VERSION ""

NS_ :

BS_:

BU_: APIM_CISM FCIMB RACM_RCIM DSP WCM DACMC HUD_ADV TRM_ITRM ACM GWM _delete APIM IPC GENERIC TSTR

BO_ 611 Driveline_Data_1_HS3: 8 GWM
 SG_ AwdTerrMdeChng_D_Rdy : 58|3@0+ (1,0) [0|7] "SED"  IPC
 SG_ AwdTerrMde_D_Actl : 50|3@0+ (1,0) [0|7] "SED"  IPC
 SG_ AwdSys_D_Stat : 27|2@0+ (1,0) [0|3] "SED"  IPC
 SG_ AwdStat_D_RqDsply : 63|5@0+ (1,0) [0|31] "SED"  IPC
 SG_ AwdLck_D_Stat : 31|4@0+ (1,0) [0|15] "SED"  IPC
 SG_ AwdSrvcRqd_B_Rq : 0|1@0+ (1,0) [0|1] "SED"  IPC
 SG_ AwdLck_Tq_Rq : 15|12@0+ (1,0) [0|4093] "Nm"  IPC
 SG_ TrnAout_Tq_RqMx : 47|13@0+ (1,-1250) [-1250|6941] "Nm"  IPC
 SG_ AwdOffRoadMode_D_Stats : 25|2@0+ (1,0) [0|3] "SED"  APIM_CISM,APIM,IPC
 SG_ AwdLoLamp_D_RqDsply : 35|2@0+ (1,0) [0|3] "SED"  APIM,APIM_CISM,IPC
 SG_ AwdHiLamp_D_RqDsply : 19|2@0+ (1,0) [0|3] "SED"  APIM,APIM_CISM,IPC
 SG_ AwdAutoLamp_D_RqDsply : 17|2@0+ (1,0) [0|3] "SED"  APIM,APIM_CISM,IPC
 SG_ Awd2wdLamp_D_RqDsply : 2|2@0+ (1,0) [0|3] "SED"  APIM,APIM_CISM,IPC
 SG_ AwdRnge_D_Actl : 7|3@0+ (1,0) [0|7] "SED"  APIM_CISM,ACM,APIM,IPC
 SG_ NtrlTowAvail_B_Stat : 4|1@0+ (1,0) [0|1] "SED"  IPC
 SG_ AwdDrvMde_D_Stat : 38|3@0+ (1,0) [0|7] "SED"  IPC
 SG_ SelDrvMdeAwd_D_Stat : 33|2@0+ (1,0) [0|3] "SED"  GENERIC

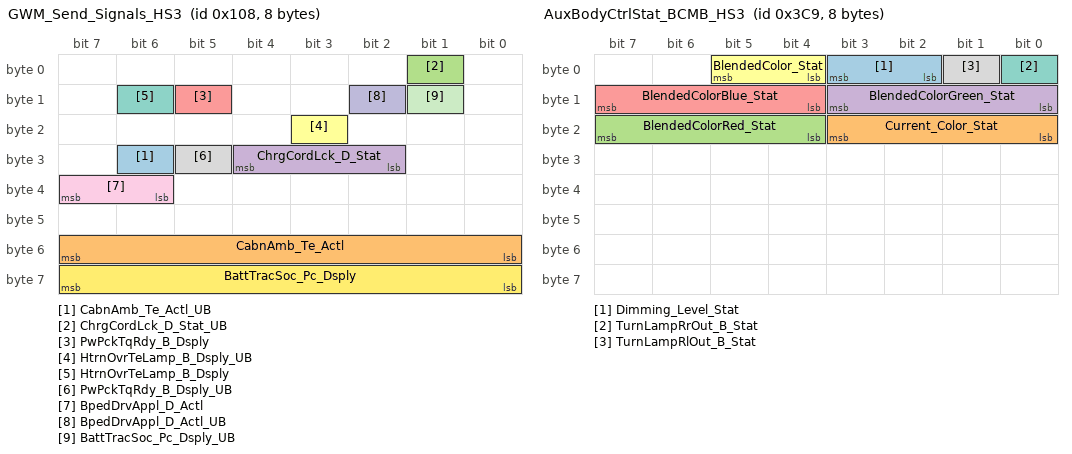
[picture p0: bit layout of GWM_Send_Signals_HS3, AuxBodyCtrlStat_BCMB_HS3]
BO_ 264 GWM_Send_Signals_HS3: 8 GWM
 SG_ CabnAmb_Te_Actl_UB : 30|1@0+ (1,0) [0|1] "SED"  APIM,APIM_CISM,WCM,ACM
 SG_ CabnAmb_Te_Actl : 55|8@0+ (0.5,-57) [-57|70] "degreesC"  APIM,APIM_CISM,WCM,ACM
 SG_ ChrgCordLck_D_Stat_UB : 1|1@0+ (1,0) [0|1] "SED"  APIM_CISM,APIM
 SG_ ChrgCordLck_D_Stat : 28|3@0+ (1,0) [0|7] "SED"  APIM_CISM,APIM
 SG_ PwPckTqRdy_B_Dsply : 13|1@0+ (1,0) [0|1] "SED"  APIM_CISM,APIM,IPC
 SG_ HtrnOvrTeLamp_B_Dsply_UB : 19|1@0+ (1,0) [0|1] "SED"  IPC
 SG_ HtrnOvrTeLamp_B_Dsply : 14|1@0+ (1,0) [0|1] "SED"  IPC
 SG_ PwPckTqRdy_B_Dsply_UB : 29|1@0+ (1,0) [0|1] "SED"  APIM_CISM,APIM,IPC
 SG_ BpedDrvAppl_D_Actl : 39|2@0+ (1,0) [0|3] "SED"  APIM_CISM,APIM,TRM_ITRM,IPC
 SG_ BpedDrvAppl_D_Actl_UB : 10|1@0+ (1,0) [0|1] "SED"  APIM_CISM,APIM,TRM_ITRM,IPC
 SG_ BattTracSoc_Pc_Dsply_UB : 9|1@0+ (1,0) [0|1] "SED"  APIM_CISM,HUD_ADV,APIM,IPC
 SG_ BattTracSoc_Pc_Dsply : 63|8@0+ (0.5,0) [0|126.5] "Percent"  APIM_CISM,HUD_ADV,APIM,IPC

BO_ 1114 TrailerAid_Data: 8 IPC
 SG_ TrailCtlSwtch_B_Stat2 : 16|1@0+ (1,0) [0|1] "SED"  GWM
 SG_ TrlBrkInitOut_D_Rq : 60|2@0+ (1,0) [0|3] "SED"  TRM_ITRM,GWM

BO_ 968 Cluster_Lighting_Rq: 8 IPC
 SG_ RvltnMatchAllw_D_Rq : 58|2@0+ (1,0) [0|3] "SED"  GWM
 SG_ BrkDrvMde_D_Rq : 18|3@0+ (1,0) [0|7] "SED"  GWM
 SG_ LnchCtl_N_Rq : 55|8@0+ (50,0) [0|12750] "rpm"  GWM
 SG_ LnchCtl_D_Rq : 63|2@0+ (1,0) [0|3] "SED"  GWM
 SG_ CurrentColor_CmdGage : 43|4@0+ (1,0) [0|15] "SED"  GWM
 SG_ BlendedColor_CmdGage : 25|2@0+ (1,0) [0|3] "SED"  GWM
 SG_ BlendColorRed_CmdGage : 47|4@0+ (1,0) [0|15] "SED"  GWM
 SG_ BlendColorGrn_CmdGage : 35|4@0+ (1,0) [0|15] "SED"  GWM
 SG_ BlendColorBlue_CmdGage : 39|4@0+ (1,0) [0|15] "SED"  GWM
 SG_ Dimming_Level_Cmd : 1|2@0+ (1,0) [0|3] "SED"  GWM
 SG_ Current_Color_Cmd : 23|4@0+ (1,0) [0|15] "SED"  GWM
 SG_ BlendedColorRed_Cmd : 11|4@0+ (1,0) [0|15] "SED"  GWM
 SG_ BlendedColorGreen_Cmd : 15|4@0+ (1,0) [0|15] "SED"  GWM
 SG_ BlendedColorBlue_Cmd : 5|4@0+ (1,0) [0|15] "SED"  GWM
 SG_ BlendedColor_Cmd : 7|2@0+ (1,0) [0|3] "SED"  GWM
 SG_ SuspDrvMde_D_Rq : 61|3@0+ (1,0) [0|7] "SED"  GWM
 SG_ SlMde_D_Rq : 27|2@0+ (1,0) [0|3] "SED"  GWM
 SG_ IsaOffst_D_Rq : 31|4@0+ (1,0) [0|15] "SED"  GWM

BO_ 969 AuxBodyCtrlStat_BCMB_HS3: 8 GWM
 SG_ Dimming_Level_Stat : 3|2@0+ (1,0) [0|3] "SED"  IPC
 SG_ Current_Color_Stat : 19|4@0+ (1,0) [0|15] "SED"  IPC
 SG_ BlendedColorRed_Stat : 23|4@0+ (1,0) [0|15] "SED"  IPC
 SG_ BlendedColorGreen_Stat : 11|4@0+ (1,0) [0|15] "SED"  IPC
 SG_ BlendedColorBlue_Stat : 15|4@0+ (1,0) [0|15] "SED"  IPC
 SG_ BlendedColor_Stat : 5|2@0+ (1,0) [0|3] "SED"  IPC
 SG_ TurnLampRrOut_B_Stat : 0|1@0+ (1,0) [0|1] "SED"  IPC
 SG_ TurnLampRlOut_B_Stat : 1|1@0+ (1,0) [0|1] "SED"  IPC

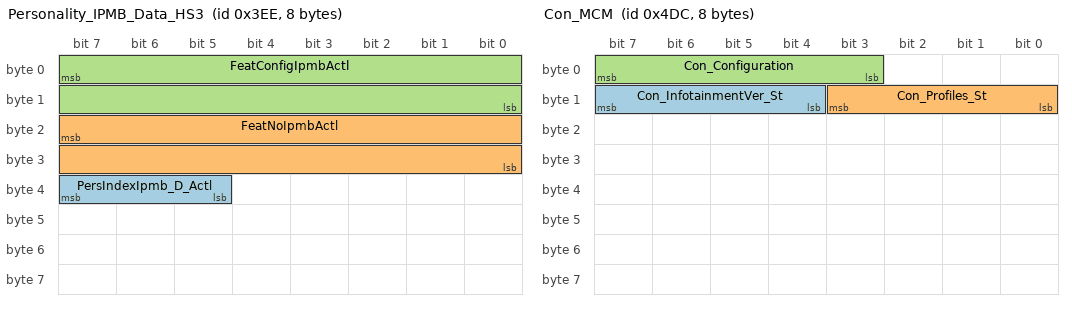
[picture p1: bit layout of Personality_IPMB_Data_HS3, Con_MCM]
BO_ 1006 Personality_IPMB_Data_HS3: 8 GWM
 SG_ PersIndexIpmb_D_Actl : 39|3@0+ (1,0) [0|7] "SED"  APIM_CISM,APIM,ACM
 SG_ FeatNoIpmbActl : 23|16@0+ (1,0) [0|65535] "Number"  APIM_CISM,APIM,ACM
 SG_ FeatConfigIpmbActl : 7|16@0+ (1,0) [0|65535] "Undefined"  APIM_CISM,APIM,ACM

BO_ 130 Steering_Wheel_Data2_HS3: 8 GWM
 SG_ EngExhMdeQuiet_B_RqDrv2 : 39|1@0+ (1,0) [0|1] "SED"  IPC
 SG_ SteWhlSwtchHome_B_Stat : 19|1@0+ (1,0) [0|1] "SED"  IPC
 SG_ SteWhlSwtchInfo_B_Stat : 18|1@0+ (1,0) [0|1] "SED"  IPC
 SG_ SelDrvMdeSwtch_D_Stat4 : 21|2@0+ (1,0) [0|3] "SED"  APIM,APIM_CISM
 SG_ SelDrvMdeSwtch3_D_Stat4 : 25|2@0+ (1,0) [0|3] "SED"  GENERIC
 SG_ SelDrvMdeSwtch2_D_Stat4 : 27|2@0+ (1,0) [0|3] "SED"  GENERIC
 SG_ SelDrvMdeSwtch1_D_Stat4 : 29|2@0+ (1,0) [0|3] "SED"  GENERIC
 SG_ PoliceAux4Swtch_B_Stat : 30|1@0+ (1,0) [0|1] "SED"  TRM_ITRM
 SG_ PoliceAux3Swtch_B_Stat : 31|1@0+ (1,0) [0|1] "SED"  TRM_ITRM
 SG_ PoliceAux2Swtch_B_Stat : 16|1@0+ (1,0) [0|1] "SED"  TRM_ITRM
 SG_ PoliceAux1Swtch_B_Stat : 17|1@0+ (1,0) [0|1] "SED"  TRM_ITRM
 SG_ SteWhlSwtchView_B_Stat : 23|1@0+ (1,0) [0|1] "SED"  IPC
 SG_ SteWhlSwtchSet_B_Stat : 8|1@0+ (1,0) [0|1] "SED"  IPC
 SG_ SteWhlSwtchPhon_B_Stat : 9|1@0+ (1,0) [0|1] "SED"  HUD_ADV,IPC
 SG_ SteWhlSwtchNav_B_Stat : 10|1@0+ (1,0) [0|1] "SED"  IPC
 SG_ SteWhlSwtchMed_B_Stat : 11|1@0+ (1,0) [0|1] "SED"  HUD_ADV,IPC
 SG_ SteWhlSwtchIod_B_Stat : 12|1@0+ (1,0) [0|1] "SED"  IPC
 SG_ SteWhlSwtchHud_B_Stat : 13|1@0+ (1,0) [0|1] "SED"  HUD_ADV,IPC
 SG_ SteWhlSwtchBack_B_Stat : 14|1@0+ (1,0) [0|1] "SED"  HUD_ADV,IPC
 SG_ SteWhlSwtchMenu_B_Stat : 22|1@0+ (1,0) [0|1] "SED"  IPC
 SG_ SteEffortInc_B_RqDrv : 5|1@0+ (1,0) [0|1] "SED"  IPC
 SG_ SelDrvMdeInc_B_RqDrv : 6|1@0+ (1,0) [0|1] "SED"  IPC
 SG_ SelDrvMdeDec_B_RqDrv : 7|1@0+ (1,0) [0|1] "SED"  IPC
 SG_ SuspDampInc_B_RqDrv : 15|1@0+ (1,0) [0|1] "SED"  IPC
 SG_ SteWhlSwtchUp_B_Stat : 3|1@0+ (1,0) [0|1] "SED"  HUD_ADV,IPC
 SG_ SteWhlSwtchRght_B_Stat : 2|1@0+ (1,0) [0|1] "SED"  HUD_ADV,IPC
 SG_ SteWhlSwtchOk_B_Stat : 4|1@0+ (1,0) [0|1] "SED"  HUD_ADV,IPC
 SG_ SteWhlSwtchLeft_B_Stat : 1|1@0+ (1,0) [0|1] "SED"  HUD_ADV,IPC
 SG_ SteWhlSwtchDown_B_Stat : 0|1@0+ (1,0) [0|1] "SED"  HUD_ADV,IPC

BO_ 1244 Con_MCM: 8 ACM
 SG_ Con_InfotainmentVer_St : 15|4@0+ (1,0) [0|0] ""  IPC
 SG_ Con_Profiles_St : 11|4@0+ (1,0) [0|0] ""  IPC
 SG_ Con_Configuration : 7|5@0+ (1,0) [0|0] ""  IPC

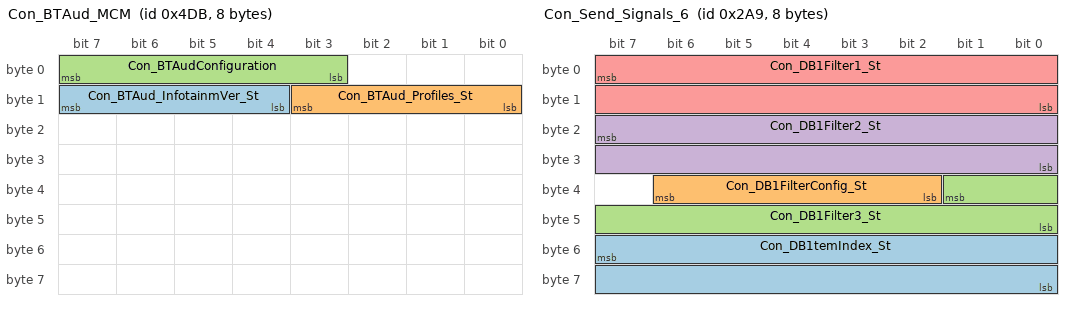
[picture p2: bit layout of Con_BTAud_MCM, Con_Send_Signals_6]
BO_ 1243 Con_BTAud_MCM: 8 ACM
 SG_ Con_BTAud_InfotainmVer_St : 15|4@0+ (1,0) [0|0] ""  IPC
 SG_ Con_BTAud_Profiles_St : 11|4@0+ (1,0) [0|0] ""  IPC
 SG_ Con_BTAudConfiguration : 7|5@0+ (1,0) [0|0] ""  IPC

BO_ 681 Con_Send_Signals_6: 8 ACM
 SG_ Con_DB1temIndex_St : 55|16@0+ (1,0) [0|0] ""  IPC
 SG_ Con_DB1FilterConfig_St : 38|5@0+ (1,0) [0|31] "SED"  IPC
 SG_ Con_DB1Filter3_St : 33|10@0+ (1,0) [0|1023] "unitless"  IPC
 SG_ Con_DB1Filter2_St : 23|16@0+ (1,0) [0|65535] "unitless"  IPC
 SG_ Con_DB1Filter1_St : 7|16@0+ (1,0) [0|65535] "unitless"  IPC

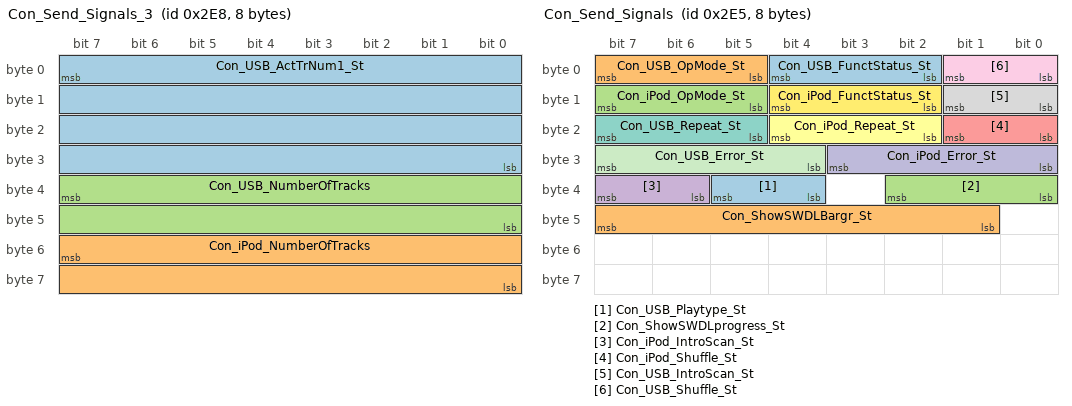
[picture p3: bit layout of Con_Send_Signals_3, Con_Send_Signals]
BO_ 744 Con_Send_Signals_3: 8 ACM
 SG_ Con_USB_ActTrNum1_St : 7|32@0+ (1,0) [0|4294967295] ""  IPC
 SG_ Con_iPod_NumberOfTracks : 55|16@0+ (1,0) [0|65535] ""  IPC
 SG_ Con_USB_NumberOfTracks : 39|16@0+ (1,0) [0|65535] ""  IPC

BO_ 741 Con_Send_Signals: 8 ACM
 SG_ Con_USB_Playtype_St : 37|2@0+ (1,0) [0|3] "SED"  APIM
 SG_ Con_ShowSWDLBargr_St : 47|7@0+ (1,0) [0|127] "unitless"  APIM
 SG_ Con_ShowSWDLprogress_St : 34|3@0+ (1,0) [0|7] "SED"  APIM
 SG_ Con_iPod_IntroScan_St : 39|2@0+ (1,0) [0|3] "SED"  APIM
 SG_ Con_iPod_Shuffle_St : 17|2@0+ (1,0) [0|3] "SED"  APIM
 SG_ Con_iPod_Repeat_St : 20|3@0+ (1,0) [0|7] "SED"  APIM
 SG_ Con_USB_Repeat_St : 23|3@0+ (1,0) [0|7] "SED"  APIM
 SG_ Con_USB_IntroScan_St : 9|2@0+ (1,0) [0|3] "SED"  APIM
 SG_ Con_USB_Shuffle_St : 1|2@0+ (1,0) [0|3] "SED"  APIM
 SG_ Con_iPod_Error_St : 27|4@0+ (1,0) [0|15] "SED"  APIM
 SG_ Con_USB_Error_St : 31|4@0+ (1,0) [0|15] "SED"  APIM
 SG_ Con_iPod_FunctStatus_St : 12|3@0+ (1,0) [0|7] "SED"  APIM
 SG_ Con_USB_FunctStatus_St : 4|3@0+ (1,0) [0|7] "SED"  APIM
 SG_ Con_USB_OpMode_St : 7|3@0+ (1,0) [0|7] "SED"  APIM
 SG_ Con_iPod_OpMode_St : 15|3@0+ (1,0) [0|7] "SED"  APIM

BO_ 954 Body_Info_10_HS3: 8 GWM
 SG_ ExtLghtFront_D_RqBody : 61|2@0+ (1,0) [0|3] "SED"  GENERIC
 SG_ CrtsyLghtRear_D_Stat : 63|2@0+ (1,0) [0|3] "SED"  APIM,APIM_CISM
 SG_ PosLghtFl_D_Stat : 51|2@0+ (1,0) [0|3] "SED"  GENERIC
 SG_ PosLghtFr_D_Stat : 49|2@0+ (1,0) [0|3] "SED"  GENERIC
 SG_ CargoLght_D_Stat : 55|2@0+ (1,0) [0|3] "SED"  APIM_CISM,APIM
 SG_ TlghtTestLght_D_Stat : 44|3@0+ (1,0) [0|7] "SED"  APIM_CISM,APIM
 SG_ LghtAmbDrvMde_B_Stat : 34|1@0+ (1,0) [0|1] "SED"  APIM_CISM,APIM
 SG_ KeylessIdl_B_Stat : 41|1@0+ (1,0) [0|1] "SED"  APIM_CISM,APIM
 SG_ PwRnngBoardPoll_D_Stat : 36|2@0+ (1,0) [0|3] "SED"  GENERIC
 SG_ PoliceDmngLvl_D_Stat : 39|3@0+ (1,0) [0|7] "SED"  APIM,IPC,APIM_CISM,GWM
 SG_ TrlrHitchLamp_D_Stat : 25|1@0+ (1,0) [0|1] "SED"  APIM,APIM_CISM
 SG_ LicPlateLght_B_Stat : 26|1@0+ (1,0) [0|1] "SED"  APIM,APIM_CISM
 SG_ TrukBedLght_B_Stat : 24|1@0+ (1,0) [0|1] "SED"  APIM,APIM_CISM
 SG_ VehWlcmFrwlMde_D_Stat : 29|3@0+ (1,0) [0|7] "SED"  APIM_CISM,RACM_RCIM,APIM,IPC
 SG_ GenericSwtch3_No_Actl : 15|3@0+ (1,0) [0|7] "unitless"  GENERIC
 SG_ GenericSwtch2_No_Actl : 4|3@0+ (1,0) [0|7] "unitless"  GENERIC
 SG_ GenericSwtch1_No_Actl : 7|3@0+ (1,0) [0|7] "unitless"  GENERIC
 SG_ PudSptLghtRight_D_Rq : 17|2@0+ (1,0) [0|3] "SED"  GENERIC
 SG_ PudSptLghtLeft_D_Rq : 19|2@0+ (1,0) [0|3] "SED"  GENERIC
 SG_ ExtLghtRight_D_Stat : 21|2@0+ (1,0) [0|3] "SED"  APIM,APIM_CISM
 SG_ VehWlcmFrwl_D_Stat : 31|2@0+ (1,0) [0|3] "SED"  RACM_RCIM,GENERIC,APIM_CISM,APIM
 SG_ ExtLghtRear_D_Stat : 23|2@0+ (1,0) [0|3] "SED"  APIM,APIM_CISM
 SG_ ExtLghtLeft_D_Stat : 9|2@0+ (1,0) [0|3] "SED"  APIM,APIM_CISM
 SG_ ExtLghtAlrt_B_Rq : 12|1@0+ (1,0) [0|1] "SED"  APIM_CISM,APIM
 SG_ ExtLght_D_Falt : 1|2@0+ (1,0) [0|3] "SED"  APIM_CISM,APIM
 SG_ ExtLghtFront_D_Stat : 11|2@0+ (1,0) [0|3] "SED"  APIM_CISM,APIM
 SG_ TlghtTestPrecnd_D_Stat : 47|3@0+ (1,0) [0|7] "SED"  APIM_CISM,APIM
 SG_ TlghtTest_D_Stat : 33|2@0+ (1,0) [0|3] "SED"  APIM_CISM,APIM

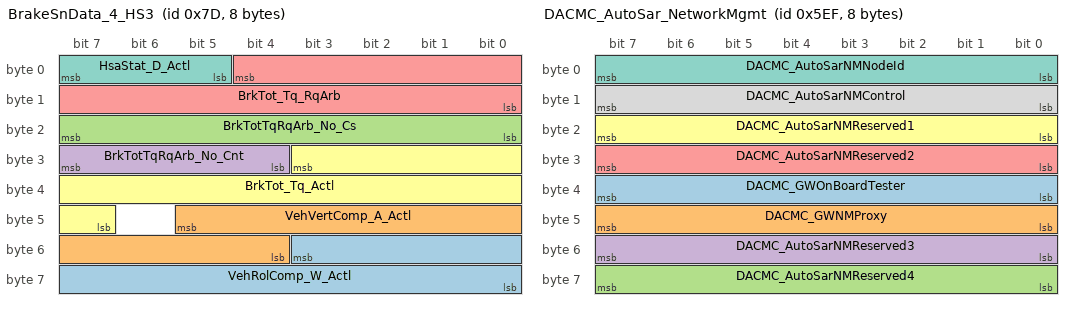
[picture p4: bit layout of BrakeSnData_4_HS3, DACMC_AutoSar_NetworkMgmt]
BO_ 125 BrakeSnData_4_HS3: 8 GWM
 SG_ VehRolComp_W_Actl : 51|12@0+ (0.03663,-75) [-75|74.92659] "degrees/sec"  APIM,APIM_CISM
 SG_ VehVertComp_A_Actl : 45|10@0+ (0.035,-17.9) [-17.9|17.835] "m/s^2"  APIM,APIM_CISM
 SG_ BrkTotTqRqArb_No_Cs : 23|8@0+ (1,0) [0|255] "Unitless"  TRM_ITRM
 SG_ BrkTotTqRqArb_No_Cnt : 31|4@0+ (1,0) [0|15] "Unitless"  TRM_ITRM
 SG_ BrkTot_Tq_RqArb : 4|13@0+ (4,0) [0|32756] "Nm"  TRM_ITRM,APIM_CISM,APIM
 SG_ BrkTot_Tq_Actl : 27|13@0+ (4,0) [0|32756] "Nm"  APIM_CISM,APIM,IPC
 SG_ HsaStat_D_Actl : 7|3@0+ (1,0) [0|7] "SED"  IPC

BO_ 2612224096 PARSEDPushIPCtoGWM_ECG: 8 IPC
 SG_ PARSEDPushIPCtoGWM_ECG : 7|29@0+ (1,0) [0|536870911] "unitless"  GWM

BO_ 2611052760 PARSEDPhysGWM_ECGtoIPC: 8 GWM
 SG_ PARSEDPhysGWM_ECGtoIPC : 7|29@0+ (1,0) [0|536870911] "unitless"  IPC

BO_ 2611175520 PARSEDPhysIPCtoGWM_ECG: 8 IPC
 SG_ PARSEDPhysIPCtoGWM_ECG : 7|29@0+ (1,0) [0|536870911] "unitless"  GWM

BO_ 2610126944 OTAPhysIPCtoGWM_ECG: 8 IPC
 SG_ OTAPhysIPCtoGWM_ECG : 7|29@0+ (1,0) [0|536870911] "unitless"  GWM

BO_ 2610004184 OTAPhysGWM_ECGtoIPC: 8 GWM
 SG_ OTAPhysGWM_ECGtoIPC : 7|29@0+ (1,0) [0|536870911] "unitless"  IPC

BO_ 2005 TesterPhysicalReqDACMC: 8 TSTR
 SG_ TesterPhysicalReqDACMC : 7|64@0+ (1,0) [0|1.84467E+019] "unitless"  DACMC

BO_ 2013 TesterPhysicalResDACMC: 8 DACMC
 SG_ TesterPhysicalResDACMC : 7|64@0+ (1,0) [0|1.84467E+019] "unitless"  TSTR

BO_ 1519 DACMC_AutoSar_NetworkMgmt: 8 DACMC
 SG_ DACMC_GWOnBoardTester : 39|8@0+ (1,0) [0|255] "unitless"  HUD_ADV,GWM
 SG_ DACMC_GWNMProxy : 47|8@0+ (1,0) [0|255] "unitless"  HUD_ADV,GWM
 SG_ DACMC_AutoSarNMReserved4 : 63|8@0+ (1,0) [0|255] "unitless"  HUD_ADV,GWM
 SG_ DACMC_AutoSarNMReserved3 : 55|8@0+ (1,0) [0|255] "unitless"  HUD_ADV,GWM
 SG_ DACMC_AutoSarNMReserved2 : 31|8@0+ (1,0) [0|255] "unitless"  HUD_ADV,GWM
 SG_ DACMC_AutoSarNMReserved1 : 23|8@0+ (1,0) [0|255] "unitless"  HUD_ADV,GWM
 SG_ DACMC_AutoSarNMNodeId : 7|8@0+ (1,0) [0|255] "unitless"  HUD_ADV,GWM
 SG_ DACMC_AutoSarNMControl : 15|8@0+ (1,0) [0|255] "unitless"  HUD_ADV,GWM

BO_ 2612002008 PARSEDFuncGWM_ECG_HS3: 8 GWM
 SG_ PARSEDFuncGWM_ECG : 7|29@0+ (1,0) [0|536870911] "unitless"  HUD_ADV,WCM,IPC

BO_ 2610953432 OTAFuncGWM_ECG_HS3: 8 GWM
 SG_ OTAFuncGWM_ECG : 7|29@0+ (1,0) [0|536870911] "unitless"  HUD_ADV,IPC,WCM

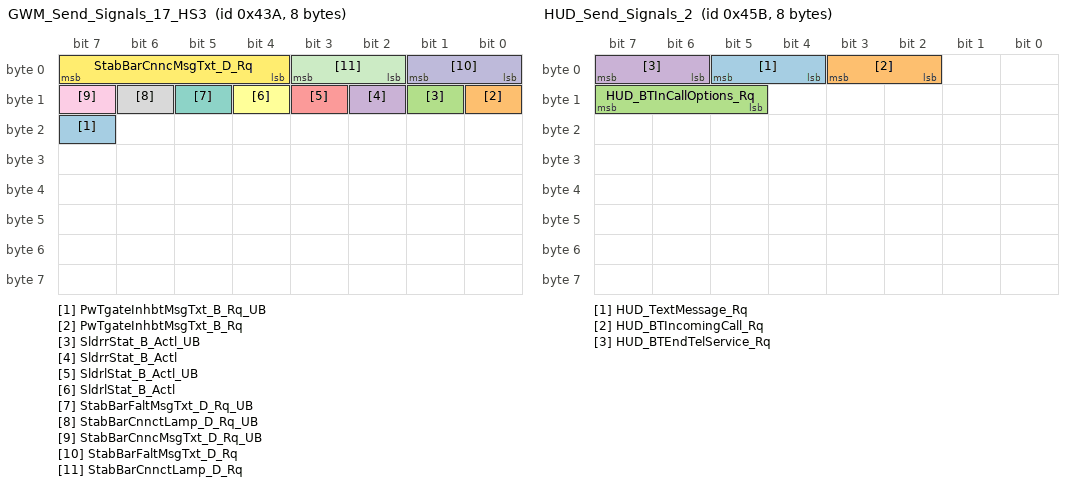
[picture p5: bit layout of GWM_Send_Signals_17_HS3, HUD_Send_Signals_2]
BO_ 1082 GWM_Send_Signals_17_HS3: 8 GWM
 SG_ PwTgateInhbtMsgTxt_B_Rq_UB : 23|1@0+ (1,0) [0|1] "SED"  IPC
 SG_ PwTgateInhbtMsgTxt_B_Rq : 8|1@0+ (1,0) [0|1] "SED"  IPC
 SG_ SldrrStat_B_Actl_UB : 9|1@0+ (1,0) [0|1] "SED"  IPC
 SG_ SldrrStat_B_Actl : 10|1@0+ (1,0) [0|1] "SED"  IPC
 SG_ SldrlStat_B_Actl_UB : 11|1@0+ (1,0) [0|1] "SED"  IPC
 SG_ SldrlStat_B_Actl : 12|1@0+ (1,0) [0|1] "SED"  IPC
 SG_ StabBarFaltMsgTxt_D_Rq_UB : 13|1@0+ (1,0) [0|1] "SED"  IPC
 SG_ StabBarCnnctLamp_D_Rq_UB : 14|1@0+ (1,0) [0|1] "SED"  APIM_CISM,IPC,APIM
 SG_ StabBarCnncMsgTxt_D_Rq_UB : 15|1@0+ (1,0) [0|1] "SED"  IPC
 SG_ StabBarFaltMsgTxt_D_Rq : 1|2@0+ (1,0) [0|3] "SED"  IPC
 SG_ StabBarCnnctLamp_D_Rq : 3|2@0+ (1,0) [0|3] "SED"  APIM_CISM,IPC,APIM
 SG_ StabBarCnncMsgTxt_D_Rq : 7|4@0+ (1,0) [0|15] "SED"  IPC

BO_ 576 AUDIO_RDISP2_WORD_Tx: 8 ACM
 SG_ AUDIO_RDISP2_WORD_Tx : 7|64@0+ (1,0) [0|1.84467440737096E+019] "unitless"  HUD_ADV

BO_ 1115 HUD_Send_Signals_2: 8 HUD_ADV
 SG_ HUD_TextMessage_Rq : 5|2@0+ (1,0) [0|3] "SED"  APIM_CISM,APIM
 SG_ HUD_BTIncomingCall_Rq : 3|2@0+ (1,0) [0|3] "SED"  APIM_CISM,APIM
 SG_ HUD_BTInCallOptions_Rq : 15|3@0+ (1,0) [0|7] "SED"  APIM_CISM,APIM
 SG_ HUD_BTEndTelService_Rq : 7|2@0+ (1,0) [0|3] "SED"  APIM_CISM,APIM

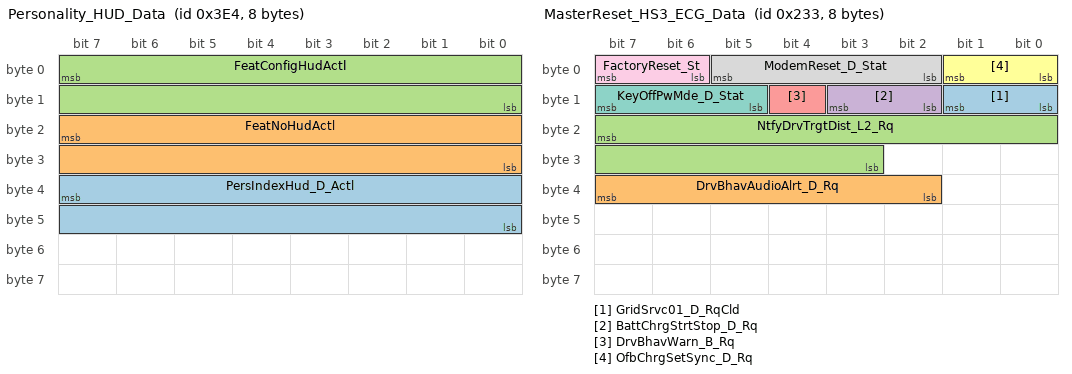
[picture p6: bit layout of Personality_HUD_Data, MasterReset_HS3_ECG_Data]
BO_ 996 Personality_HUD_Data: 8 HUD_ADV
 SG_ PersIndexHud_D_Actl : 39|16@0+ (1,0) [0|65535] "Unitless"  IPC
 SG_ FeatNoHudActl : 23|16@0+ (1,0) [0|65535] "Unitless"  IPC
 SG_ FeatConfigHudActl : 7|16@0+ (1,0) [0|65535] "Unitless"  IPC

BO_ 588 RDRV_RDISP2_WORD_Rx: 8 HUD_ADV
 SG_ RDRV_RDISP2_WORD_Rx : 7|64@0+ (1,0) [0|1.84467440737096E+019] "unitless"  GENERIC

BO_ 811 APIM_Data: 8 APIM
 SG_ ExtLghtDsply_D_Stat : 7|3@0+ (1,0) [0|7] "SED"  GWM
 SG_ SpeedoMajorUnit_D_Confg : 59|2@0+ (1,0) [0|3] "SED"  GWM
 SG_ ScMnSoc_Pc_RqMnu : 55|7@0+ (1,0) [0|125] "percent"  GWM
 SG_ ScEnbl_D_RqMnu : 57|2@0+ (1,0) [0|3] "SED"  GWM
 SG_ OnePdlDrvButtn_B_Falt : 16|1@0+ (1,0) [0|1] "SED"  GWM
 SG_ OnePdlDrvButtn_B_Stat : 48|1@0+ (1,0) [0|1] "SED"  GWM
 SG_ LongTermReset_B_RqMnu : 17|1@0+ (1,0) [0|1] "SED"  GWM
 SG_ DistToStopover_L_Actl : 31|16@0+ (0.1,0) [0|6553.4] "kilometer"  IPC,GWM
 SG_ StopoverType_D_Stat : 47|3@0+ (1,0) [0|0] "SED"  IPC,GWM
 SG_ ExtLghtRight_D_RqMnu : 11|3@0+ (1,0) [0|7] "SED"  GWM
 SG_ AutoLghtOvrrd_B_RqDrv : 8|1@0+ (1,0) [0|1] "SED"  GWM
 SG_ ExtLghtRear_D_RqMnu : 14|3@0+ (1,0) [0|7] "SED"  GWM
 SG_ ExtLghtLeft_D_RqMnu : 1|3@0+ (1,0) [0|7] "SED"  GWM
 SG_ ExtLghtFront_D_RqMnu : 4|3@0+ (1,0) [0|7] "SED"  GWM
 SG_ BecRleas_No_RqMnu : 23|3@0+ (1,0) [0|7] "unitless"  GWM
 SG_ TrnkFrontRleas_No_RqMnu : 20|3@0+ (1,0) [0|7] "unitless"  GWM
 SG_ GoTEditMnte_T_RqMnu : 63|4@0+ (1,0) [0|15] "SED"  GWM
 SG_ GoTEditHr_T_RqMnu : 44|5@0+ (1,0) [0|29] "SED"  GWM

BO_ 543 TelTaleData: 8 IPC
 SG_ TeltalWarnData_No_Actl : 7|64@0+ (1,0) [0|1.84467E+019] "unitless"  APIM,GWM,APIM_CISM

BO_ 563 MasterReset_HS3_ECG_Data: 8 GWM
 SG_ GridSrvc01_D_RqCld : 9|2@0+ (1,0) [0|3] "SED"  APIM
 SG_ DrvBhavAudioAlrt_D_Rq : 39|6@0+ (1,0) [0|63] "SED"  APIM,APIM_CISM
 SG_ NtfyDrvTrgtDist_L2_Rq : 23|13@0+ (0.1,0) [0|818.9] "Km"  GENERIC
 SG_ BattChrgStrtStop_D_Rq : 11|2@0+ (1,0) [0|3] "SED"  GENERIC
 SG_ DrvBhavWarn_B_Rq : 12|1@0+ (1,0) [0|1] "SED"  IPC
 SG_ OfbChrgSetSync_D_Rq : 1|2@0+ (1,0) [0|3] "SED"  APIM,APIM_CISM
 SG_ KeyOffPwMde_D_Stat : 15|3@0+ (1,0) [0|7] "SED"  APIM_CISM,APIM
 SG_ ModemReset_D_Stat : 5|4@0+ (1,0) [0|15] "SED"  APIM_CISM,ACM,APIM
 SG_ FactoryReset_St : 7|2@0+ (1,0) [0|3] "SED"  APIM_CISM,ACM,APIM

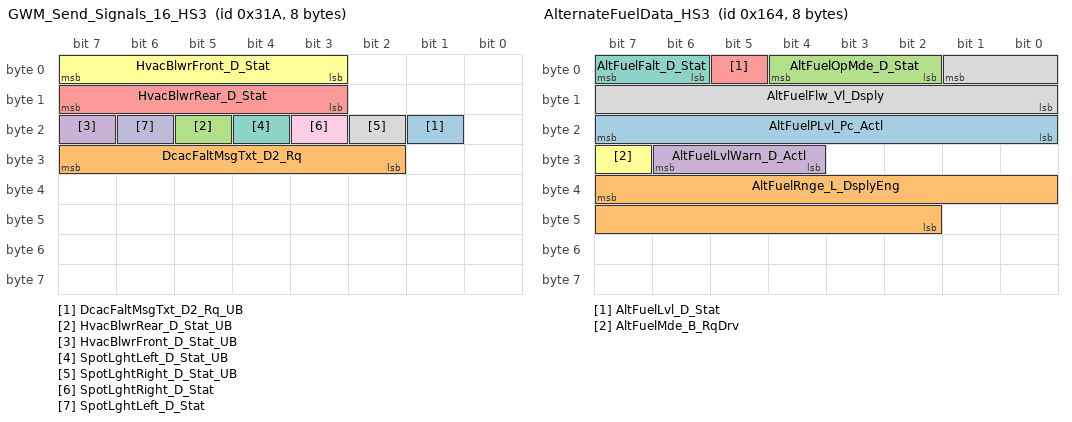
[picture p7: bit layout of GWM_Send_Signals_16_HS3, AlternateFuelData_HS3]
BO_ 794 GWM_Send_Signals_16_HS3: 8 GWM
 SG_ DcacFaltMsgTxt_D2_Rq_UB : 17|1@0+ (1,0) [0|1] "SED"  APIM,APIM_CISM
 SG_ DcacFaltMsgTxt_D2_Rq : 31|6@0+ (1,0) [0|63] "SED"  APIM,APIM_CISM
 SG_ HvacBlwrRear_D_Stat_UB : 21|1@0+ (1,0) [0|1] "SED"  WCM
 SG_ HvacBlwrFront_D_Stat_UB : 23|1@0+ (1,0) [0|1] "SED"  WCM
 SG_ HvacBlwrRear_D_Stat : 15|5@0+ (1,0) [0|31] "SED"  WCM
 SG_ HvacBlwrFront_D_Stat : 7|5@0+ (1,0) [0|31] "SED"  WCM
 SG_ SpotLghtLeft_D_Stat_UB : 20|1@0+ (1,0) [0|1] "SED"  APIM,APIM_CISM
 SG_ SpotLghtRight_D_Stat_UB : 18|1@0+ (1,0) [0|1] "SED"  APIM,APIM_CISM
 SG_ SpotLghtRight_D_Stat : 19|1@0+ (1,0) [0|1] "SED"  APIM,APIM_CISM
 SG_ SpotLghtLeft_D_Stat : 22|1@0+ (1,0) [0|1] "SED"  APIM_CISM,APIM

BO_ 587 PHONE_RDISP2_WORD_Rx: 8 HUD_ADV
 SG_ PHONE_RDISP2_WORD_Rx : 7|64@0+ (1,0) [0|1.84467440737096E+019] "unitless"  APIM_CISM,ACM,APIM

BO_ 579 PHONE_RDISP2_WORD_Tx: 8 APIM
 SG_ PHONE_RDISP2_WORD_Tx : 7|64@0+ (1,0) [0|1.84467440737096E+019] "unitless"  HUD_ADV

BO_ 585 NAV_RDISP2_WORD_Rx: 8 HUD_ADV
 SG_ NAV_RDISP2_WORD_Rx : 7|64@0+ (1,0) [0|1.84467440737096E+019] "unitless"  APIM_CISM,APIM

BO_ 586 CONMP_RDISP2_WORD_Rx: 8 HUD_ADV
 SG_ CONMP_RDISP2_WORD_Rx : 7|64@0+ (1,0) [0|1.84467440737096E+019] "unitless"  APIM_CISM,APIM

BO_ 578 CONMP_RDISP2_WORD_Tx: 8 APIM
 SG_ CONMP_RDISP2_WORD_Tx : 7|64@0+ (1,0) [0|1.84467440737096E+019] "unitless"  HUD_ADV

BO_ 577 NAV_RDISP2_WORD_Tx: 8 APIM
 SG_ NAV_RDISP2_WORD_Tx : 7|64@0+ (1,0) [0|1.84467440737096E+019] "unitless"  HUD_ADV

BO_ 356 AlternateFuelData_HS3: 8 GWM
 SG_ AltFuelPLvl_Pc_Actl : 23|8@0+ (0.471,0) [0|120.105] "percent"  APIM,IPC,APIM_CISM
 SG_ AltFuelRnge_L_DsplyEng : 39|14@0+ (0.1,0) [0|1638.3] "kilometer"  IPC,APIM_CISM,APIM
 SG_ AltFuelOpMde_D_Stat : 4|3@0+ (1,0) [0|7] "SED"  IPC
 SG_ AltFuelLvlWarn_D_Actl : 30|3@0+ (1,0) [0|7] "SED"  IPC
 SG_ AltFuelLvl_D_Stat : 5|1@0+ (1,0) [0|1] "SED"  APIM,IPC,APIM_CISM
 SG_ AltFuelMde_B_RqDrv : 31|1@0+ (1,0) [0|1] "SED"  IPC
 SG_ AltFuelFalt_D_Stat : 7|2@0+ (1,0) [0|3] "SED"  IPC
 SG_ AltFuelFlw_Vl_Dsply : 1|10@0+ (25,0) [0|25575] "micro_litre"  IPC

BO_ 712 NAV_MC_WORD_Rx: 8 IPC
 SG_ NAV_MC_WORD_Rx : 7|64@0+ (1,0) [0|1.84467440737096E+019] "unitless"  APIM_CISM,APIM

BO_ 717 DSPAMP_RDISP_WORD_Rx: 8 APIM
 SG_ DSPAMP_RDISP_WORD_Rx : 7|64@0+ (1,0) [0|1.84467440737096E+019] "unitless"  DSP

BO_ 719 MyKeySrvr_Clnt_Word_Rx: 8 APIM
 SG_ MyKeySrvr_Clnt_Word_Rx : 7|64@0+ (1,0) [0|1.84467440737096E+019] "unitless"  IPC

BO_ 1879 TesterPhysicalReqTBM_HS3: 8 TSTR
 SG_ TesterPhysicalReqTBM_HS3 : 7|64@0+ (1,0) [0|1.84467E+019] "unitless"  TRM_ITRM

BO_ 1887 TesterPhysicalResTBM_HS3: 8 TRM_ITRM
 SG_ TesterPhysicalResTBM_HS3 : 7|64@0+ (1,0) [0|1.84467E+019] "unitless"  TSTR

BO_ 1146 TrailerInfo_ITRM: 8 TRM_ITRM
 SG_ TrlrAidSwtch_D_RqDrv : 35|2@0+ (1,0) [0|3] "SED"  GWM
 SG_ TrlrAidCtl_U_RqDrv : 31|12@0+ (0.00125,0) [0|5.11625] "volt"  GWM

BO_ 737 APIM_ECG_Word_Tx: 8 APIM
 SG_ APIM_ECG_Word_Tx : 7|64@0+ (1,0) [0|1.84467440737096E+019] "unitless"  GWM

BO_ 745 ECG_APIM_Word_Tx: 8 GWM
 SG_ ECG_APIM_Word_Tx : 7|64@0+ (1,0) [0|1.84467440737096E+019] "unitless"  APIM_CISM,APIM

BO_ 1195 TCU_RDISP2_WORD_Rx: 8 HUD_ADV
 SG_ TCU_RDISP2_WORD_Rx : 7|64@0+ (1,0) [0|1.84467440737096E+019] "unitless"  GWM

BO_ 1185 TCU_MC_WORD_Rx: 8 IPC
 SG_ TCU_MC_WORD_Rx : 7|64@0+ (1,0) [0|1.84467440737096E+019] "unitless"  GWM

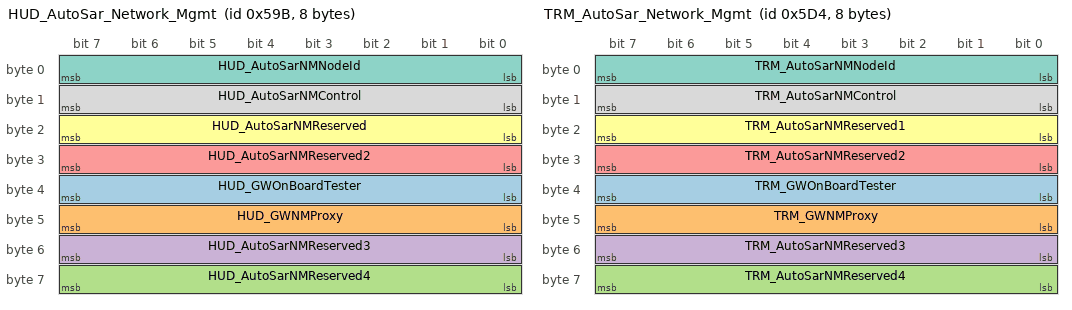
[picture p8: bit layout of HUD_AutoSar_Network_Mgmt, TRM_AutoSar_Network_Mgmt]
BO_ 1435 HUD_AutoSar_Network_Mgmt: 8 HUD_ADV
 SG_ HUD_GWOnBoardTester : 39|8@0+ (1,0) [0|255] "unitless"  GWM
 SG_ HUD_GWNMProxy : 47|8@0+ (1,0) [0|255] "unitless"  GWM
 SG_ HUD_AutoSarNMReserved4 : 63|8@0+ (1,0) [0|255] "unitless"  GWM
 SG_ HUD_AutoSarNMReserved3 : 55|8@0+ (1,0) [0|255] "unitless"  GWM
 SG_ HUD_AutoSarNMReserved2 : 31|8@0+ (1,0) [0|255] "unitless"  GWM
 SG_ HUD_AutoSarNMReserved : 23|8@0+ (1,0) [0|255] "unitless"  GWM
 SG_ HUD_AutoSarNMNodeId : 7|8@0+ (1,0) [0|255] "unitless"  GWM
 SG_ HUD_AutoSarNMControl : 15|8@0+ (1,0) [0|255] "unitless"  GWM

BO_ 1109 eCall_Info: 8 APIM
 SG_ eCallConfirmation : 7|3@0+ (1,0) [0|7] "SED"  IPC,GWM

BO_ 1492 TRM_AutoSar_Network_Mgmt: 8 TRM_ITRM
 SG_ TRM_GWOnBoardTester : 39|8@0+ (1,0) [0|255] "unitless"  GWM
 SG_ TRM_GWNMProxy : 47|8@0+ (1,0) [0|255] "unitless"  GWM
 SG_ TRM_AutoSarNMReserved4 : 63|8@0+ (1,0) [0|255] "unitless"  GWM
 SG_ TRM_AutoSarNMReserved3 : 55|8@0+ (1,0) [0|255] "unitless"  GWM
 SG_ TRM_AutoSarNMReserved2 : 31|8@0+ (1,0) [0|255] "unitless"  GWM
 SG_ TRM_AutoSarNMReserved1 : 23|8@0+ (1,0) [0|255] "unitless"  GWM
 SG_ TRM_AutoSarNMNodeId : 7|8@0+ (1,0) [0|255] "unitless"  GWM
 SG_ TRM_AutoSarNMControl : 15|8@0+ (1,0) [0|255] "unitless"  GWM

BO_ 1945 TesterPhysicalResTRM_ITRM: 8 TRM_ITRM
 SG_ TesterPhysicalResTRM_ITRM : 7|64@0+ (1,0) [0|1.84467E+019] "unitless"  TSTR

BO_ 1937 TesterPhysicalReqTRM_ITRM: 8 TSTR
 SG_ TesterPhysicalReqTRM_ITRM : 7|64@0+ (1,0) [0|1.84467E+019] "unitless"  TRM_ITRM

BO_ 300 RollerShutterControlData_HS3: 8 GWM
 SG_ TrukBedLght_B_Stat2 : 7|1@0+ (1,0) [0|1] "SED"  APIM,APIM_CISM

BO_ 2612224006 PARSEDPushHUDtoGWM_ECG: 8 HUD_ADV
 SG_ PARSEDPushHUDtoGWM_ECG : 7|29@0+ (1,0) [0|536870911] "unitless"  GWM

BO_ 2611175430 PARSEDPhysHUDtoGWM_ECG: 8 HUD_ADV
 SG_ PARSEDPhysHUDtoGWM_ECG : 7|29@0+ (1,0) [0|536870911] "Unitless"  GWM

BO_ 2610960600 PARSEDPhysGWM_ECGtoHUD: 8 GWM
 SG_ PARSEDPhysGWM_ECGtoHUD : 7|29@0+ (1,0) [0|536870911] "unitless"  HUD_ADV

BO_ 2610126854 OTAPhysHUDtoGWM_ECG: 8 HUD_ADV
 SG_ OTAPhysHUDtoGWM_ECG : 7|29@0+ (1,0) [0|536870911] "unitless"  GWM

BO_ 2609912024 OTAPhysGWM_ECGtoHUD: 8 GWM
 SG_ OTAPhysGWM_ECGtoHUD : 7|29@0+ (1,0) [0|536870911] "unitless"  HUD_ADV

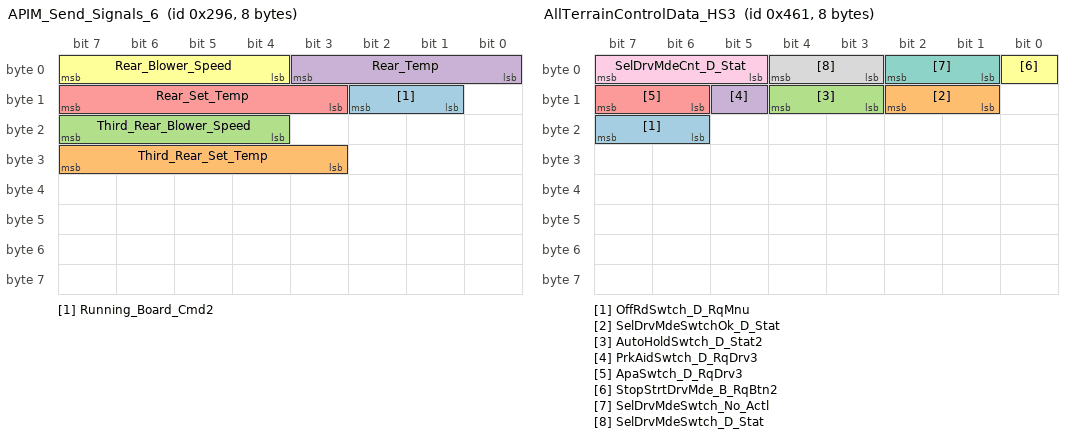
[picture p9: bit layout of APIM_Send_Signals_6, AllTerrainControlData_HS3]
BO_ 662 APIM_Send_Signals_6: 8 APIM
 SG_ Running_Board_Cmd2 : 10|2@0+ (1,0) [0|3] "SED"  GWM
 SG_ Third_Rear_Set_Temp : 31|5@0+ (1,0) [0|31] "SED"  GWM
 SG_ Third_Rear_Blower_Speed : 23|4@0+ (1,0) [0|15] "SED"  GWM
 SG_ Rear_Temp : 3|4@0+ (1,0) [0|15] "SED"  GWM
 SG_ Rear_Set_Temp : 15|5@0+ (1,0) [0|31] "SED"  GWM
 SG_ Rear_Blower_Speed : 7|4@0+ (1,0) [0|15] "SED"  GWM

BO_ 837 VeyDynamics_Data_HS3: 8 GWM
 SG_ VehCurb_M_Actl : 43|10@0+ (5,0) [0|5105] "kilogram"  APIM,APIM_CISM
 SG_ VehGvwr_M_Actl : 49|10@0+ (10,0) [0|10210] "kilogram"  APIM,APIM_CISM
 SG_ SuspVLimBRq_No_Cs : 39|8@0+ (1,0) [0|255] "Unitless"  GENERIC
 SG_ SuspVLimBRq_No_Cnt : 47|4@0+ (1,0) [0|15] "Unitless"  GENERIC
 SG_ VdmSustnActv_B_Rq : 12|1@0+ (1,0) [0|1] "SED"  GENERIC
 SG_ Ccd_B_Falt : 24|1@0+ (1,0) [0|1] "SED"  GENERIC
 SG_ SuspVLim_B_Rq : 18|1@0+ (1,0) [0|1] "SED"  GENERIC
 SG_ SelDrvMdeSusp_D_Stat : 20|2@0+ (1,0) [0|3] "SED"  GENERIC
 SG_ AdptDrvMdePt_D_Rq : 23|3@0+ (1,0) [0|7] "SED"  GENERIC
 SG_ AdptDrvMdeChassis_D_Rq : 10|3@0+ (1,0) [0|7] "SED"  GENERIC
 SG_ AirSprngRateRr_D_Rq : 27|2@0+ (1,0) [0|3] "SED"  GENERIC
 SG_ AirSprngRateRl_D_Rq : 29|2@0+ (1,0) [0|3] "SED"  GENERIC
 SG_ SuspType_B_Stat : 25|1@0+ (1,0) [0|1] "SED"  GENERIC
 SG_ AirSprngRateFr_D_Rq : 31|2@0+ (1,0) [0|3] "SED"  GENERIC
 SG_ AirSprngRateFl_D_Rq : 17|2@0+ (1,0) [0|3] "SED"  GENERIC
 SG_ AirSusp_D_Stat : 1|2@0+ (1,0) [0|3] "SED"  GENERIC
 SG_ AirSuspMsgTxt_D_Rq : 3|2@0+ (1,0) [0|3] "SED"  GENERIC
 SG_ SuspDrvMde_D_Stat : 15|3@0+ (1,0) [0|7] "SED"  GENERIC
 SG_ CcdMsgTxt_D_RqDsply : 7|4@0+ (1,0) [0|15] "SED"  GENERIC

BO_ 1121 AllTerrainControlData_HS3: 8 GWM
 SG_ OffRdSwtch_D_RqMnu : 23|2@0+ (1,0) [0|3] "SED"  APIM,APIM_CISM
 SG_ SelDrvMdeSwtchOk_D_Stat : 10|2@0+ (1,0) [0|3] "SED"  GENERIC
 SG_ AutoHoldSwtch_D_Stat2 : 12|2@0+ (1,0) [0|3] "SED"  GWM
 SG_ PrkAidSwtch_D_RqDrv3 : 13|1@0+ (1,0) [0|1] "SED"  GENERIC
 SG_ ApaSwtch_D_RqDrv3 : 15|2@0+ (1,0) [0|3] "SED"  GENERIC
 SG_ StopStrtDrvMde_B_RqBtn2 : 0|1@0+ (1,0) [0|1] "SED"  GENERIC
 SG_ SelDrvMdeSwtch_No_Actl : 2|2@0+ (1,0) [0|3] "unitless"  GENERIC
 SG_ SelDrvMdeSwtch_D_Stat : 4|2@0+ (1,0) [0|3] "SED"  GENERIC
 SG_ SelDrvMdeCnt_D_Stat : 7|3@0+ (1,0) [0|7] "Counts"  GENERIC

BO_ 670 Driver_Dr_Stat2_HS3: 8 GWM
 SG_ DrHandleOuterRl_D_Stat : 4|3@0+ (1,0) [0|7] "SED"  IPC
 SG_ DrHandleOuterFl_D_Stat : 7|3@0+ (1,0) [0|7] "SED"  IPC

BO_ 669 Pass_Dr_Stat2_HS3: 8 GWM
 SG_ DrHandleOuterRr_D_Stat : 4|3@0+ (1,0) [0|7] "SED"  IPC
 SG_ DrHandleOuterFr_D_Stat : 7|3@0+ (1,0) [0|7] "SED"  IPC

BO_ 140 CruiseCtrl_StrgData2: 8 IPC
 SG_ CcAslButtnIndxIncPress2 : 18|1@0+ (1,0) [0|1] "SED"  GWM
 SG_ SteWhlSwtchMde_D_Stat : 23|2@0+ (1,0) [0|3] "SED"  GWM
 SG_ CcAslButtnOffCnclPress2 : 17|1@0+ (1,0) [0|1] "SED"  GWM
 SG_ CcAslButtnIndxDecPress2 : 19|1@0+ (1,0) [0|1] "SED"  GWM
 SG_ CcAslButtnCnclResPress2 : 21|1@0+ (1,0) [0|1] "SED"  GWM
 SG_ CcAslButtnResIncPress3 : 29|1@0+ (1,0) [0|1] "SED"  GWM
 SG_ CcButtnOnPress3 : 37|1@0+ (1,0) [0|1] "SED"  GWM
 SG_ CcButtnOnOffPress3 : 38|1@0+ (1,0) [0|1] "SED"  GWM
 SG_ CcButtnOnOffCnclPress3 : 39|1@0+ (1,0) [0|1] "SED"  GWM
 SG_ CcButtnOffPress3 : 24|1@0+ (1,0) [0|1] "SED"  GWM
 SG_ CcAsllButtnResPress3 : 25|1@0+ (1,0) [0|1] "SED"  GWM
 SG_ CcAslButtnSetPress3 : 26|1@0+ (1,0) [0|1] "SED"  GWM
 SG_ CcAslButtnSetIncPress3 : 27|1@0+ (1,0) [0|1] "SED"  GWM
 SG_ CcAslButtnSetDecPress3 : 28|1@0+ (1,0) [0|1] "SED"  GWM
 SG_ CcAslButtnResDecPress3 : 30|1@0+ (1,0) [0|1] "SED"  GWM
 SG_ CcAslButtnOnPress3 : 31|1@0+ (1,0) [0|1] "SED"  GWM
 SG_ CcAslButtnOnOffCncl3 : 16|1@0+ (1,0) [0|1] "SED"  GWM
 SG_ CcAslButtnDeny_B_Actl3 : 20|1@0+ (1,0) [0|1] "SED"  GWM
 SG_ CcAslButtnCnclPress3 : 8|1@0+ (1,0) [0|1] "SED"  GWM
 SG_ AslButtnOnOffPress3 : 9|1@0+ (1,0) [0|1] "SED"  GWM
 SG_ AslButtnOnOffCnclPress2 : 10|1@0+ (1,0) [0|1] "SED"  GWM

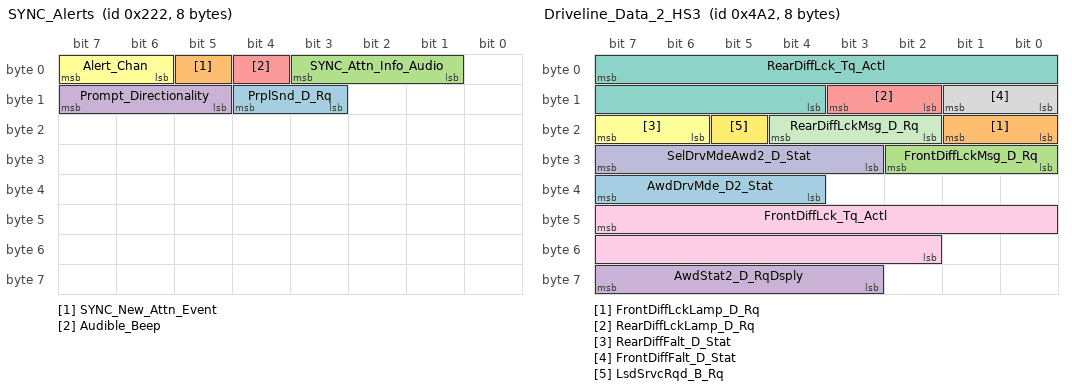
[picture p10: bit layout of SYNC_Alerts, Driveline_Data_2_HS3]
BO_ 546 SYNC_Alerts: 8 APIM
 SG_ PrplSnd_D_Rq : 12|2@0+ (1,0) [0|3] "SED"  ACM
 SG_ SYNC_New_Attn_Event : 5|1@0+ (1,0) [0|1] "SED"  ACM,DSP
 SG_ SYNC_Attn_Info_Audio : 3|3@0+ (1,0) [0|7] "SED"  ACM,DSP
 SG_ Prompt_Directionality : 15|3@0+ (1,0) [0|7] "SED"  ACM,DSP
 SG_ Audible_Beep : 4|1@0+ (1,0) [0|1] "SED"  ACM,DSP
 SG_ Alert_Chan : 7|2@0+ (1,0) [0|3] "SED"  WCM,RACM_RCIM,ACM,DSP

BO_ 1186 Driveline_Data_2_HS3: 8 GWM
 SG_ AwdDrvMde_D2_Stat : 39|4@0+ (1,0) [0|15] "SED"  IPC
 SG_ FrontDiffLckLamp_D_Rq : 17|2@0+ (1,0) [0|3] "SED"  APIM_CISM,IPC,APIM
 SG_ FrontDiffLckMsg_D_Rq : 26|3@0+ (1,0) [0|7] "SED"  IPC
 SG_ AwdStat2_D_RqDsply : 63|5@0+ (1,0) [0|31] "SED"  IPC
 SG_ RearDiffLckLamp_D_Rq : 11|2@0+ (1,0) [0|3] "SED"  APIM_CISM,ACM,APIM,IPC
 SG_ RearDiffFalt_D_Stat : 23|2@0+ (1,0) [0|3] "SED" Vector__XXX
 SG_ RearDiffLck_Tq_Actl : 7|12@0+ (1,0) [0|4093] "Nm" Vector__XXX
 SG_ FrontDiffFalt_D_Stat : 9|2@0+ (1,0) [0|3] "SED"  GENERIC
 SG_ FrontDiffLck_Tq_Actl : 47|14@0+ (1,0) [0|16381] "Nm"  GENERIC
 SG_ SelDrvMdeAwd2_D_Stat : 31|5@0+ (1,0) [0|31] "SED"  GENERIC
 SG_ RearDiffLckMsg_D_Rq : 20|3@0+ (1,0) [0|7] "SED"  IPC
 SG_ LsdSrvcRqd_B_Rq : 21|1@0+ (1,0) [0|1] "SED"  IPC

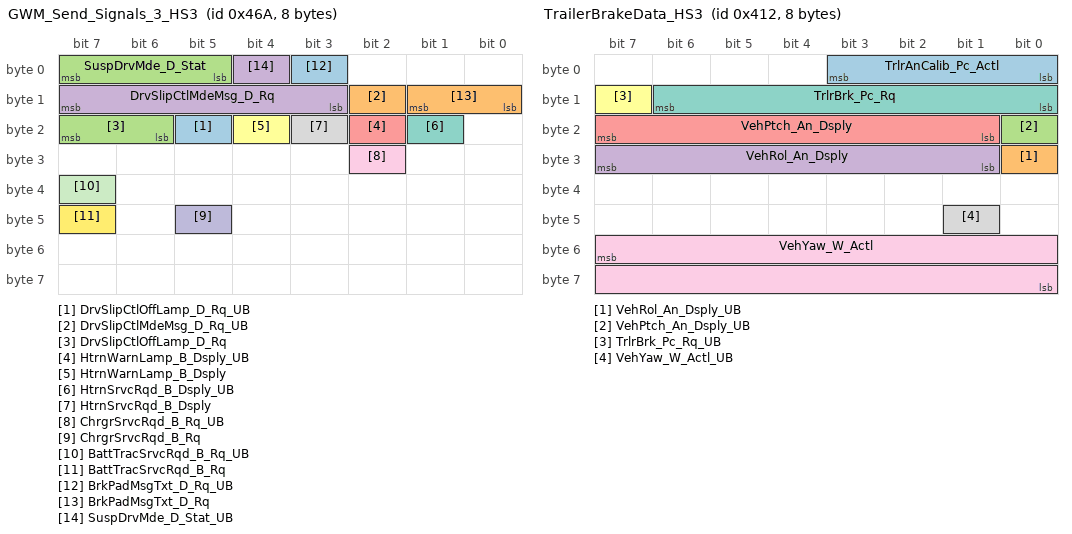
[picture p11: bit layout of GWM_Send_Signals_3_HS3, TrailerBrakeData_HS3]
BO_ 1130 GWM_Send_Signals_3_HS3: 8 GWM
 SG_ DrvSlipCtlOffLamp_D_Rq_UB : 21|1@0+ (1,0) [0|1] "SED"  APIM,IPC
 SG_ DrvSlipCtlMdeMsg_D_Rq_UB : 10|1@0+ (1,0) [0|1] "SED"  APIM,APIM_CISM,IPC
 SG_ DrvSlipCtlOffLamp_D_Rq : 23|2@0+ (1,0) [0|3] "SED"  APIM,IPC
 SG_ DrvSlipCtlMdeMsg_D_Rq : 15|5@0+ (1,0) [0|31] "SED"  APIM,APIM_CISM,IPC
 SG_ HtrnWarnLamp_B_Dsply_UB : 18|1@0+ (1,0) [0|1] "SED"  IPC
 SG_ HtrnWarnLamp_B_Dsply : 20|1@0+ (1,0) [0|1] "SED"  IPC
 SG_ HtrnSrvcRqd_B_Dsply_UB : 17|1@0+ (1,0) [0|1] "SED"  IPC
 SG_ HtrnSrvcRqd_B_Dsply : 19|1@0+ (1,0) [0|1] "SED"  IPC
 SG_ ChrgrSrvcRqd_B_Rq_UB : 26|1@0+ (1,0) [0|1] "SED"  IPC
 SG_ ChrgrSrvcRqd_B_Rq : 45|1@0+ (1,0) [0|1] "SED"  IPC
 SG_ BattTracSrvcRqd_B_Rq_UB : 39|1@0+ (1,0) [0|1] "SED"  IPC
 SG_ BattTracSrvcRqd_B_Rq : 47|1@0+ (1,0) [0|1] "SED"  IPC
 SG_ BrkPadMsgTxt_D_Rq_UB : 3|1@0+ (1,0) [0|1] "SED"  IPC
 SG_ BrkPadMsgTxt_D_Rq : 9|2@0+ (1,0) [0|3] "SED"  IPC
 SG_ SuspDrvMde_D_Stat : 7|3@0+ (1,0) [0|7] "SED"  IPC
 SG_ SuspDrvMde_D_Stat_UB : 4|1@0+ (1,0) [0|1] "SED"  IPC

BO_ 1042 TrailerBrakeData_HS3: 8 GWM
 SG_ TrlrAnCalib_Pc_Actl : 3|4@0+ (10,0) [0|140] "percent"  IPC
 SG_ VehRol_An_Dsply_UB : 24|1@0+ (1,0) [0|1] "SED"  APIM_CISM,APIM,IPC
 SG_ VehPtch_An_Dsply_UB : 16|1@0+ (1,0) [0|1] "SED"  APIM_CISM,APIM,IPC
 SG_ VehRol_An_Dsply : 31|7@0+ (1,-64) [-64|61] "degrees"  APIM_CISM,APIM,IPC
 SG_ VehPtch_An_Dsply : 23|7@0+ (1,-64) [-64|61] "degrees"  APIM_CISM,APIM,IPC
 SG_ TrlrBrk_Pc_Rq_UB : 15|1@0+ (1,0) [0|1] "SED"  TRM_ITRM,IPC
 SG_ TrlrBrk_Pc_Rq : 14|7@0+ (1,0) [0|127] "percent"  TRM_ITRM,IPC
 SG_ VehYaw_W_Actl_UB : 41|1@0+ (1,0) [0|1] "SED"  APIM_CISM,ACM,APIM
 SG_ VehYaw_W_Actl : 55|16@0+ (0.0002,-6.5) [-6.5|6.6066] "rad/s"  APIM_CISM,ACM,APIM

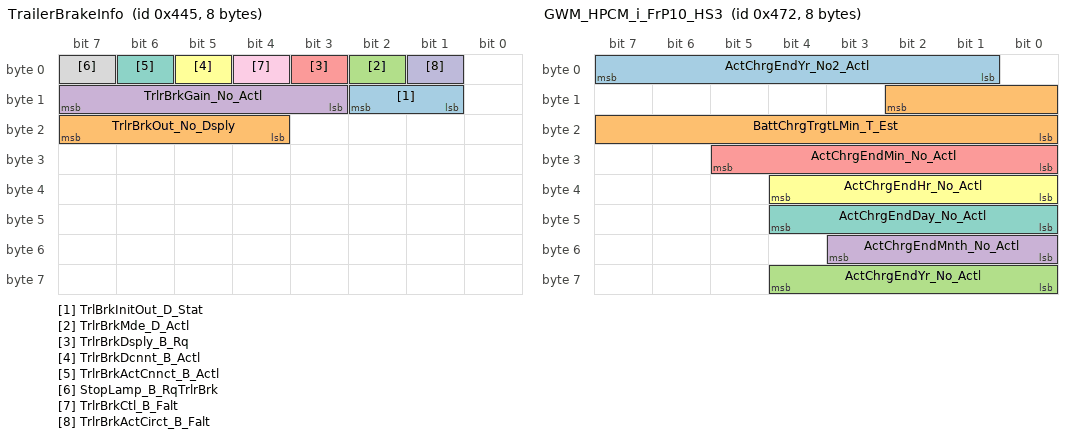
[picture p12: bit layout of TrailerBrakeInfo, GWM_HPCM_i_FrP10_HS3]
BO_ 1093 TrailerBrakeInfo: 8 TRM_ITRM
 SG_ TrlBrkInitOut_D_Stat : 10|2@0+ (1,0) [0|3] "SED"  GWM,IPC
 SG_ TrlrBrkOut_No_Dsply : 23|4@0+ (1,0) [0|15] "unitless"  GWM,IPC
 SG_ TrlrBrkMde_D_Actl : 2|1@0+ (1,0) [0|1] "SED"  GWM,IPC
 SG_ TrlrBrkGain_No_Actl : 15|5@0+ (0.5,0) [0|15.5] "unitless"  APIM_CISM,APIM,GWM,IPC
 SG_ TrlrBrkDsply_B_Rq : 3|1@0+ (1,0) [0|1] "SED"  GWM,IPC
 SG_ TrlrBrkDcnnt_B_Actl : 5|1@0+ (1,0) [0|1] "SED"  GWM,IPC
 SG_ TrlrBrkActCnnct_B_Actl : 6|1@0+ (1,0) [0|1] "SED"  APIM,APIM_CISM,GWM,IPC
 SG_ StopLamp_B_RqTrlrBrk : 7|1@0+ (1,0) [0|1] "SED"  GWM
 SG_ TrlrBrkCtl_B_Falt : 4|1@0+ (1,0) [0|1] "SED"  GWM,IPC
 SG_ TrlrBrkActCirct_B_Falt : 1|1@0+ (1,0) [0|1] "SED"  GWM,IPC

BO_ 1138 GWM_HPCM_i_FrP10_HS3: 8 GWM
 SG_ ActChrgEndYr_No2_Actl : 7|7@0+ (1,2017) [2017|2144] "year"  APIM_CISM,APIM,IPC
 SG_ BattChrgTrgtLMin_T_Est : 10|11@0+ (1,0) [0|2045] "minute"  APIM_CISM,APIM
 SG_ ActChrgEndYr_No_Actl : 60|5@0+ (1,2010) [2010|2040] "year"  IPC,APIM_CISM,APIM
 SG_ ActChrgEndMnth_No_Actl : 51|4@0+ (1,1) [1|15] "month"  IPC,APIM_CISM,APIM
 SG_ ActChrgEndMin_No_Actl : 29|6@0+ (1,0) [0|61] "minute"  IPC,APIM_CISM,APIM
 SG_ ActChrgEndHr_No_Actl : 36|5@0+ (1,0) [0|29] "hour"  IPC,APIM_CISM,APIM
 SG_ ActChrgEndDay_No_Actl : 44|5@0+ (1,1) [1|31] "days"  IPC,APIM_CISM,APIM

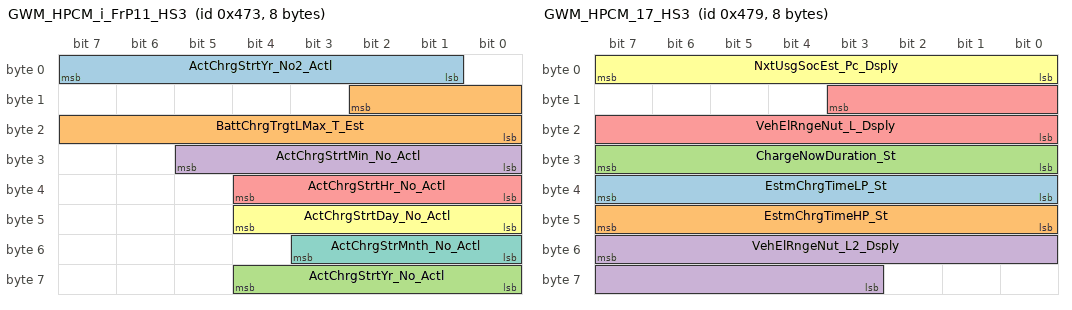
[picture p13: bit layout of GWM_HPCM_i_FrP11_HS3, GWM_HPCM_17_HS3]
BO_ 1139 GWM_HPCM_i_FrP11_HS3: 8 GWM
 SG_ ActChrgStrtYr_No2_Actl : 7|7@0+ (1,2017) [2017|2144] "year"  APIM_CISM,APIM,IPC
 SG_ BattChrgTrgtLMax_T_Est : 10|11@0+ (1,0) [0|2045] "minute"  APIM_CISM,APIM
 SG_ ActChrgStrtYr_No_Actl : 60|5@0+ (1,2010) [2010|2040] "year"  IPC,APIM_CISM,APIM
 SG_ ActChrgStrtMin_No_Actl : 29|6@0+ (1,0) [0|61] "minute"  IPC,APIM_CISM,APIM
 SG_ ActChrgStrtHr_No_Actl : 36|5@0+ (1,0) [0|29] "hour"  IPC,APIM_CISM,HUD_ADV,APIM
 SG_ ActChrgStrtDay_No_Actl : 44|5@0+ (1,1) [1|31] "days"  IPC,APIM_CISM,APIM
 SG_ ActChrgStrMnth_No_Actl : 51|4@0+ (1,1) [1|15] "month"  IPC,APIM_CISM,APIM

BO_ 1145 GWM_HPCM_17_HS3: 8 GWM
 SG_ EstmChrgTimeLP_St : 39|8@0+ (0.1,0) [0|25.4] "hour"  GENERIC
 SG_ EstmChrgTimeHP_St : 47|8@0+ (0.1,0) [0|25.4] "hour"  GENERIC
 SG_ ChargeNowDuration_St : 31|8@0+ (0.1,0) [0|25.4] "hour"  GENERIC
 SG_ VehElRngeNut_L2_Dsply : 55|13@0+ (0.1,0) [0|818.9] "km"  APIM_CISM,APIM
 SG_ VehElRngeNut_L_Dsply : 11|12@0+ (0.1,0) [0|409.3] "km"  APIM_CISM,APIM,IPC
 SG_ NxtUsgSocEst_Pc_Dsply : 7|8@0+ (0.5,0) [0|126.5] "unitless"  APIM_CISM,APIM

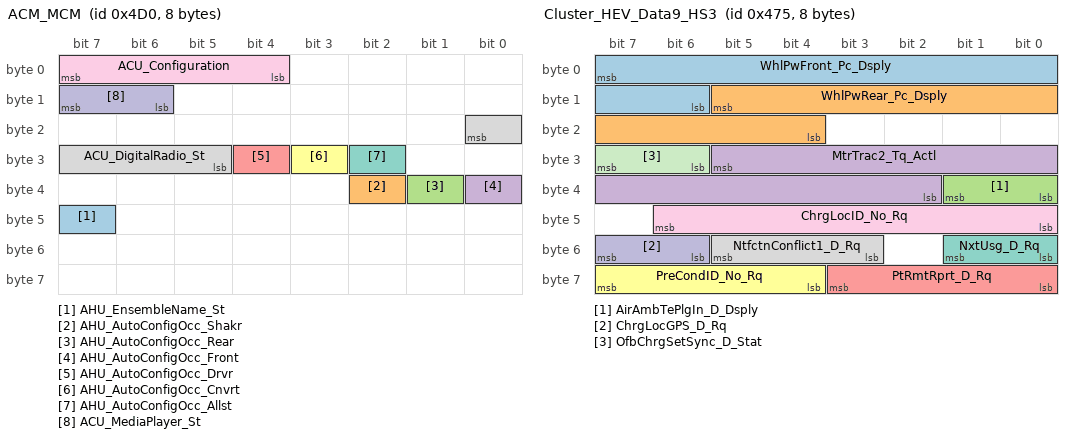
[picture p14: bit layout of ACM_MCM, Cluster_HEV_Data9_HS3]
BO_ 1232 ACM_MCM: 8 ACM
 SG_ AHU_EnsembleName_St : 47|1@0+ (1,0) [0|1] "SED"  APIM
 SG_ AHU_AutoConfigOcc_Shakr : 34|1@0+ (1,0) [0|1] "SED"  APIM
 SG_ AHU_AutoConfigOcc_Rear : 33|1@0+ (1,0) [0|1] "SED"  APIM
 SG_ AHU_AutoConfigOcc_Front : 32|1@0+ (1,0) [0|1] "SED"  APIM
 SG_ AHU_AutoConfigOcc_Drvr : 28|1@0+ (1,0) [0|1] "SED"  APIM
 SG_ AHU_AutoConfigOcc_Cnvrt : 27|1@0+ (1,0) [0|1] "SED"  APIM
 SG_ AHU_AutoConfigOcc_Allst : 26|1@0+ (1,0) [0|1] "SED"  APIM
 SG_ ACU_DigitalRadio_St : 16|4@0+ (1,0) [0|15] "SED"  APIM,IPC
 SG_ ACU_Configuration : 7|4@0+ (1,0) [0|15] "SED"  APIM,IPC
 SG_ ACU_MediaPlayer_St : 15|2@0+ (1,0) [0|3] "SED"  APIM,IPC

BO_ 1141 Cluster_HEV_Data9_HS3: 8 GWM
 SG_ WhlPwFront_Pc_Dsply : 7|10@0+ (0.2,-102.2) [-102.2|102.4] "percent"  IPC
 SG_ WhlPwRear_Pc_Dsply : 13|10@0+ (0.2,-102.2) [-102.2|102.4] "percent"  IPC
 SG_ AirAmbTePlgIn_D_Dsply : 33|2@0+ (1,0) [0|3] "SED"  IPC
 SG_ MtrTrac2_Tq_Actl : 29|12@0+ (1,-2047) [-2047|2048] "Nm" Vector__XXX
 SG_ PtRmtRprt_D_Rq : 59|4@0+ (1,0) [0|15] "SED"  IPC
 SG_ PreCondID_No_Rq : 63|4@0+ (1,0) [0|15] "unitless"  IPC
 SG_ NxtUsg_D_Rq : 49|2@0+ (1,0) [0|3] "SED"  IPC
 SG_ NtfctnConflict1_D_Rq : 53|3@0+ (1,0) [0|7] "SED"  APIM_CISM,APIM
 SG_ ChrgLocID_No_Rq : 46|7@0+ (1,0) [0|127] "unitless"  IPC
 SG_ ChrgLocGPS_D_Rq : 55|2@0+ (1,0) [0|3] "SED"  IPC
 SG_ OfbChrgSetSync_D_Stat : 31|2@0+ (1,0) [0|3] "SED"  APIM,APIM_CISM

BO_ 631 HEV_ChargeStat_HS3: 8 GWM
 SG_ RearPassWindowPos : 58|3@0+ (1,0) [0|7] "SED"  APIM,APIM_CISM,WCM,ACM
 SG_ RearDriverWindowPos : 62|3@0+ (1,0) [0|7] "SED"  APIM,APIM_CISM,WCM,ACM
 SG_ PassWindowPosition : 50|3@0+ (1,0) [0|7] "SED"  APIM,APIM_CISM,ACM,WCM
 SG_ RearPassWindowPos_UB : 59|1@0+ (1,0) [0|1] "SED"  APIM,APIM_CISM,WCM,ACM
 SG_ RearDriverWindowPos_UB : 63|1@0+ (1,0) [0|1] "SED"  APIM,APIM_CISM,WCM,ACM
 SG_ PassWindowPosition_UB : 51|1@0+ (1,0) [0|1] "SED"  APIM,APIM_CISM,ACM,WCM
 SG_ DriverWindowPosition : 54|3@0+ (1,0) [0|7] "SED"  APIM,APIM_CISM,WCM,ACM
 SG_ DriverWindowPosition_UB : 55|1@0+ (1,0) [0|1] "SED"  APIM,APIM_CISM,WCM,ACM
 SG_ CnvtTopPos_Up_Stat : 38|1@0+ (1,0) [0|1] "SED"  APIM_CISM,DACMC,DSP,ACM
 SG_ Memory_Cmd : 7|4@0+ (1,0) [0|15] "SED"  HUD_ADV,IPC
 SG_ CnvtTopPos_Up_Stat_UB : 37|1@0+ (1,0) [0|1] "SED"  APIM_CISM,DACMC,DSP,ACM
 SG_ Memory_Cmd_UB : 3|1@0+ (1,0) [0|1] "SED"  HUD_ADV,IPC
 SG_ EstmChrgTimeLP_St : 31|8@0+ (0.1,0) [0|25.4] "hour"  IPC,APIM_CISM,APIM
 SG_ EstmChrgTimeHP_St : 23|8@0+ (0.1,0) [0|25.4] "hour"  IPC,APIM_CISM,APIM
 SG_ ChargeNowDuration_St : 15|8@0+ (0.1,0) [0|25.4] "hour"  IPC,APIM_CISM,APIM
 SG_ CnvtTopMsgTxt_D_Rq_UB : 34|1@0+ (1,0) [0|1] "SED"  IPC
 SG_ CnvtTopMsgTxt_D_Rq : 36|2@0+ (1,0) [0|3] "SED"  IPC
 SG_ CnvtTopPos_Dn_Stat_UB : 1|1@0+ (1,0) [0|1] "SED"  APIM_CISM,DACMC,ACM
 SG_ CnvtTopPos_Dn_Stat : 2|1@0+ (1,0) [0|1] "SED"  APIM_CISM,DACMC,ACM
 SG_ EstmChrgTimeLP_St_UB : 33|1@0+ (1,0) [0|1] "SED"  APIM_CISM,APIM,IPC
 SG_ EstmChrgTimeHP_St_UB : 39|1@0+ (1,0) [0|1] "SED"  APIM_CISM,APIM,IPC
 SG_ ChargeNowDuration_St_UB : 0|1@0+ (1,0) [0|1] "SED"  APIM_CISM,APIM

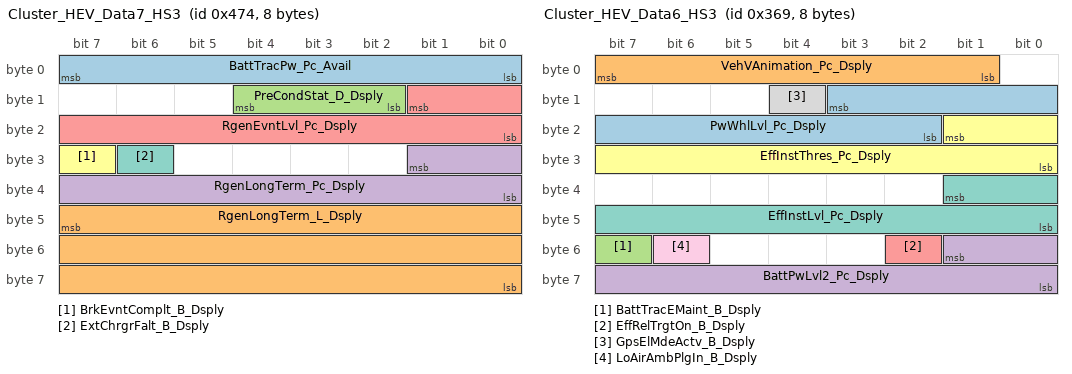
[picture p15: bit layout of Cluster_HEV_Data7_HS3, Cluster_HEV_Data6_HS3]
BO_ 1140 Cluster_HEV_Data7_HS3: 8 GWM
 SG_ BattTracPw_Pc_Avail : 7|8@0+ (0.5,0) [0|126.5] "percent"  IPC
 SG_ RgenLongTerm_L_Dsply : 47|24@0+ (0.1,0) [0|1677721.3] "km"  IPC
 SG_ PreCondStat_D_Dsply : 12|3@0+ (1,0) [0|7] "SED"  IPC
 SG_ RgenLongTerm_Pc_Dsply : 25|10@0+ (0.1,0) [0|102.3] "percent"  IPC
 SG_ RgenEvntLvl_Pc_Dsply : 9|10@0+ (0.1,0) [0|102.1] "percent"  IPC
 SG_ BrkEvntComplt_B_Dsply : 31|1@0+ (1,0) [0|1] "SED"  IPC
 SG_ ExtChrgrFalt_B_Dsply : 30|1@0+ (1,0) [0|1] "SED"  IPC

BO_ 873 Cluster_HEV_Data6_HS3: 8 GWM
 SG_ PwWhlLvl_Pc_Dsply : 11|10@0+ (0.2,-102.2) [-102.2|102.4] "percent"  IPC
 SG_ VehVAnimation_Pc_Dsply : 7|7@0+ (1,0) [0|127] "percent"  IPC
 SG_ BattTracEMaint_B_Dsply : 55|1@0+ (1,0) [0|1] "SED"  IPC
 SG_ BattPwLvl2_Pc_Dsply : 49|10@0+ (0.2,-102.2) [-102.2|102.4] "percent"  APIM_CISM,APIM,IPC
 SG_ EffRelTrgtOn_B_Dsply : 50|1@0+ (1,0) [0|1] "SED"  IPC
 SG_ EffInstThres_Pc_Dsply : 17|10@0+ (0.1,0) [0|102.3] "percent"  IPC
 SG_ EffInstLvl_Pc_Dsply : 33|10@0+ (0.1,0) [0|102.3] "percent"  IPC
 SG_ GpsElMdeActv_B_Dsply : 12|1@0+ (1,0) [0|1] "SED"  APIM_CISM,APIM,IPC
 SG_ LoAirAmbPlgIn_B_Dsply : 54|1@0+ (1,0) [0|1] "SED"  IPC

BO_TX_BU_ 576 : APIM_CISM,ACM;
BO_TX_BU_ 811 : APIM_CISM,APIM;
BO_TX_BU_ 579 : ACM,APIM_CISM,APIM;
BO_TX_BU_ 578 : APIM_CISM,APIM;
BO_TX_BU_ 577 : APIM_CISM,APIM;
BO_TX_BU_ 717 : APIM_CISM,APIM;
BO_TX_BU_ 719 : APIM_CISM,APIM;
BO_TX_BU_ 737 : APIM_CISM,APIM;
BO_TX_BU_ 1109 : APIM_CISM,APIM;
BO_TX_BU_ 662 : APIM_CISM,APIM;
BO_TX_BU_ 546 : APIM_CISM,APIM;
BO_TX_BU_ 1232 : APIM_CISM,ACM;
CM_ BO_ 611 "Used on Applications with 4x4 supplied by Motorola.";
CM_ SG_ 611 AwdStat_D_RqDsply "Signal not transmitted on programs that do not have AWD.";
CM_ SG_ 611 AwdSrvcRqd_B_Rq "Signal not transmitted on programs that do not have AWD.";
CM_ SG_ 611 AwdLck_Tq_Rq "Signal not transmitted on programs that do not have AWD.";
CM_ SG_ 969 TurnLampRrOut_B_Stat "Signal not transmitted on vehicles without a BCMB module.";
CM_ SG_ 969 TurnLampRlOut_B_Stat "Signal not transmitted on vehicles without a BCMB module.";
CM_ SG_ 130 SelDrvMdeSwtch3_D_Stat4 "ECM_HEV does not support or Transmit signal.";
CM_ SG_ 1244 Con_InfotainmentVer_St "Object Configuration Management.CON_InfotainmetVer";
CM_ SG_ 1244 Con_Profiles_St "Object Configuration Management.CON_Profiles

Bit 0: 0: invalid 1: valid
Bit 1: 0: No iPod browsing support 1: iPod browsing support
Bit 2: 0: No USB browsing support 1: USB browsing support
Bit 3: Reserved
Bit 4: Reserved";
CM_ SG_ 1244 Con_Configuration "Object Configuration Management.CON_Configuration

Bit 0: 0=invalid, 1=valid
Bit 1: SWDLviaUSB support: 0=No, 1=Yes
Bit 2: iPod support 0=No, 1:=Yes
Bit 3: USB support 0=No, 1=Yes
Bit 4: Reserved";
CM_ SG_ 1243 Con_BTAud_InfotainmVer_St "Object Configuration Management.BTAud_InfotainmentVer";
CM_ SG_ 1243 Con_BTAud_Profiles_St "Object Configuration Management.BTAud_Profiles

Bit 0: 0: invalid 1: valid
Bit 1: 0: No BTAudio browsing support 1: BTAudio browsing support
Bit 2: 0: No BTAudio device setting support 1: BTAudio device setting support
Bit 3: ElapsedRemainingTiming

";
CM_ SG_ 1243 Con_BTAudConfiguration "Object Configuration Management.BTAud_Configuration

Bit 0: 0: invalid 1: valid
Bit 1: 0: No BTAudio streaming support 1: BTAudio streaming
Bit 2: 0: No mobile navigation support 1: Mobile navigation";
CM_ SG_ 681 Con_DB1temIndex_St "Object Media Player iPod.MDBActiveTrack.ItemIndex";
CM_ SG_ 681 Con_DB1FilterConfig_St "Object Media Player iPod.MDBActiveTrack.MDBFilterConf";
CM_ SG_ 681 Con_DB1Filter3_St "Object Media Player iPod.MDBActiveTrack.MDBFilter3";
CM_ SG_ 681 Con_DB1Filter2_St "Object Media Player iPod..MDBActiveTrack.MDBFilter2";
CM_ SG_ 681 Con_DB1Filter1_St "Object Media Player iPod..MDBActiveTrack.MDBFilter1";
CM_ SG_ 744 Con_USB_ActTrNum1_St "Object Media Player USB.ActiveTrackNum1";
CM_ SG_ 744 Con_iPod_NumberOfTracks "Object Media Player USB..NumberofTracks
Info: Tracks in current folder";
CM_ SG_ 744 Con_USB_NumberOfTracks "Object Media Player USB..NumberofTracks
Info: Tracks in current folder";
CM_ SG_ 741 Con_USB_Playtype_St "Object Media Player USB.Playtype
Playtype:
Playlist is selected if CON module plays tracks out of a Playlist
";
CM_ SG_ 741 Con_ShowSWDLBargr_St "Object SWDL.ShowSWDLBargraphStatus

Range (dec): 0% - 100% (0x00 - 0x64)

No update in progress: ConnectivitySWUpdateNotRunning: $7E";
CM_ SG_ 741 Con_ShowSWDLprogress_St "Object SWDL.Con_ShowCONSWDL_St";
CM_ SG_ 741 Con_iPod_IntroScan_St "Object Media Player iPod.Introscan";
CM_ SG_ 741 Con_iPod_Shuffle_St "Object Media Player iPod.Shuffle";
CM_ SG_ 741 Con_iPod_Repeat_St "Object Media Player iPod.Repeat";
CM_ SG_ 741 Con_USB_Repeat_St "Object Media Player USB.Repeat";
CM_ SG_ 741 Con_USB_IntroScan_St "Object Media Player USB.IntroScan";
CM_ SG_ 741 Con_USB_Shuffle_St "Object MediaPlayer USB.Shuffle";
CM_ SG_ 741 Con_iPod_Error_St "Object Media Player iPod.iPodError";
CM_ SG_ 741 Con_USB_Error_St "Object Media Player USB.USBError";
CM_ SG_ 741 Con_iPod_FunctStatus_St "Object Media Player iPod.FunctionStatus";
CM_ SG_ 741 Con_USB_FunctStatus_St "Object Media Player USB.FunctionStatus";
CM_ SG_ 741 Con_USB_OpMode_St "Object Media Player USB.OperationMode";
CM_ SG_ 741 Con_iPod_OpMode_St "Object Media Player iPod.OperationMode";
CM_ SG_ 954 GenericSwtch2_No_Actl "U625 Police Wig Wag feature";
CM_ BO_ 2611175520 "TpTxIndex = 463569112 paired to 0x1BA180D8";
CM_ BO_ 2610126944 "TpTxIndex = 462520536 which is paired to 0x1B9180D8 OTAPhysGWM_ECGtoIPC ";
CM_ SG_ 576 AUDIO_RDISP2_WORD_Tx "MM ISO 15765-2 Message Catalogue AUDIO - RDISP2";
CM_ SG_ 1115 HUD_TextMessage_Rq "Object. BTPhoneClient.TextMessage.Rq";
CM_ SG_ 1115 HUD_BTIncomingCall_Rq "Object Bluetooth Phone.BTIncomingCall";
CM_ SG_ 1115 HUD_BTInCallOptions_Rq "Object.BTPhoneClient.BTInCallOptions.Rq.SingleParam";
CM_ SG_ 1115 HUD_BTEndTelService_Rq "Object Bluetooth Phone.BTEndTelService";
CM_ SG_ 588 RDRV_RDISP2_WORD_Rx "MM ISO 15765-2 Message Catalogue RDISP2 - RDRV";
CM_ SG_ 563 NtfyDrvTrgtDist_L2_Rq "Object.SetTripRangeAlert_Rq
This signal is meant to provide the customer settings for the target distance remote notification";
CM_ SG_ 587 PHONE_RDISP2_WORD_Rx "MM ISO 15765-2 Message Catalogue
Section MC - PHONE";
CM_ SG_ 579 PHONE_RDISP2_WORD_Tx "MM ISO 15765-2 Message Catalogue
Section  PHONE - MC";
CM_ SG_ 585 NAV_RDISP2_WORD_Rx "MM ISO 15765-2 Message Catalogue NavRepClient2 - NavRepServer";
CM_ SG_ 586 CONMP_RDISP2_WORD_Rx "MM ISO 15765-2 Message Catalogue
Section CONMP - MC
Section MediaPlayerServer - MediaPlayerClient";
CM_ SG_ 578 CONMP_RDISP2_WORD_Tx "MM ISO 15765-2 Message Catalogue
Section CONMP - MC
Section MediaPlayerServer - MediaPlayerClient";
CM_ SG_ 577 NAV_RDISP2_WORD_Tx "MM ISO 15765-2 Message Catalogue NavRepServer – NavRepClient2";
CM_ SG_ 712 NAV_MC_WORD_Rx "MM ISO 15765-2 Message Catalogue
Section MC - NAV
Section NavRepClient - NavRepServer";
CM_ SG_ 717 DSPAMP_RDISP_WORD_Rx "Object:BezelDiagnostics.DSP_Bezel_Diag_Data";
CM_ SG_ 719 MyKeySrvr_Clnt_Word_Rx "Object.RepSrv_RepClient_WORD_Rx";
CM_ SG_ 745 ECG_APIM_Word_Tx "Tx by HS3 APIM";
CM_ SG_ 546 Prompt_Directionality "Object.AlertMethod. SYNC_Alerts

";
CM_ SG_ 546 Audible_Beep "Object.AlertMethod. SYNC_Alerts";
CM_ SG_ 546 Alert_Chan "Object.AlertMethod. SYNC_Alerts
";
CM_ SG_ 1093 StopLamp_B_RqTrlrBrk "Signal not transmitted on all variants.";
CM_ SG_ 1232 AHU_EnsembleName_St "Object Configuration Management.EnsembleName_St";
CM_ SG_ 1232 AHU_AutoConfigOcc_Shakr "Object: AudioSettings.AHU_AutoConFigOcc_Shaker";
CM_ SG_ 1232 AHU_AutoConfigOcc_Rear "Object:AudioSettings.AHU_AutoConfigOcc_Rear";
CM_ SG_ 1232 AHU_AutoConfigOcc_Front "Object: AudioSettings. AHU_AutoConfigOcc_Front";
CM_ SG_ 1232 AHU_AutoConfigOcc_Drvr "Object:AudioSettings.AHU_AutoConfigOcc_Driver";
CM_ SG_ 1232 AHU_AutoConfigOcc_Cnvrt "AHU_AutoConfigOcc_Convertible ";
CM_ SG_ 1232 AHU_AutoConfigOcc_Allst "Object: AudioSettings. AHU_AutoConfigOcc_AllSeats";
CM_ SG_ 1232 ACU_DigitalRadio_St "Object Configuration Management.ACU_DigitalRadio";
CM_ SG_ 1232 ACU_Configuration "Object Configuration Management.ACU_Configuration";
CM_ SG_ 1232 ACU_MediaPlayer_St "Object Configuration Management.ACU_MediaPlayer

$1: MusicCassettePlayer is handled as Medialess in MFD setup";
CM_ SG_ 631 CnvtTopPos_Up_Stat "Signal not transmitted on vehicles without convertible tops.";
CM_ SG_ 631 CnvtTopPos_Dn_Stat "Signal not transmitted on vehicles without convertible tops.";
BA_DEF_ BO_  "FrameRouting" STRING ;
BA_DEF_ BO_  "FrameGatewayNetwork" STRING ;
BA_DEF_ BO_  "NetworkInitialization" ENUM  "No","Yes";
BA_DEF_ BO_  "FrameGatewayId" HEX 0 1407;
BA_DEF_ BO_  "EventRateOfChange" INT 10 10000;
BA_DEF_ BO_  "GenMsgStartDelayTime" INT 0 10000;
BA_DEF_ BO_  "GenMsgNrOfRepetition" INT 0 100;
BA_DEF_ BO_  "GenMsgDelayTime" INT 0 1000;
BA_DEF_ BO_  "GenMsgCycleTime" INT 0 100000;
BA_DEF_ BO_  "GenMsgSendType" ENUM  "FixedPeriodic","Event","EnabledPeriodic","NotUsed","NotUsed","EventPeriodic","NotUsed","NotUsed","NoMsgSendType";
BA_DEF_ SG_  "U_CD764_MY2022_Tx" ENUM  "No","Yes";
BA_DEF_ SG_  "U_U55X_MY2022_Tx" ENUM  "No","Yes";
BA_DEF_ SG_  "U_CD542_MY2021_Tx" ENUM  "No","Yes";
BA_DEF_ SG_  "ECGUsedTxSignal" ENUM  "No","Yes";
BA_DEF_ SG_  "U_T6_MCA_MY2020_Tx" ENUM  "No","Yes";
BA_DEF_ SG_  "U_P702_MY2021_Tx" ENUM  "No","Yes";
BA_DEF_ SG_  "U_CX727_MY2021_Tx" ENUM  "No","Yes";
BA_DEF_ SG_  "U_CD764_MY2022_Rx" ENUM  "No","Yes";
BA_DEF_ SG_  "U_FNV2_IVI_Rx" ENUM  "No","Yes";
BA_DEF_ SG_  "U_U55X_MY2022_Rx" ENUM  "No","Yes";
BA_DEF_ SG_  "U_CD542_MY2021_Rx" ENUM  "No","Yes";
BA_DEF_ SG_  "ECGUsedRxSignal" ENUM  "No","Yes";
BA_DEF_ SG_  "U_T6_MCA_MY2020_Rx" ENUM  "No","Yes";
BA_DEF_ SG_  "U_P702_MY2021_Rx" ENUM  "No","Yes";
BA_DEF_ SG_  "U_CX727_MY2021_Rx" ENUM  "No","Yes";
BA_DEF_ SG_  "GenSigStartValue" HEX 0 268435455;
BA_DEF_ SG_  "MetaData" ENUM  "No","Yes";
BA_DEF_ SG_  "ContentDependant" ENUM  "No","Yes";
BA_DEF_ SG_  "GenSigStartValueInteger" INT 0 1000000000;
BA_DEF_ SG_  "UsedOnPgmDBC" ENUM  "No","Yes";
BA_DEF_ SG_  "WakeupSignal" ENUM  "No","Yes";
BA_DEF_ SG_  "GenSigInactiveValue" INT 0 100000;
BA_DEF_ SG_  "GenSigSendType" ENUM  "Cyclic","OnWrite","vector_leerstring","OnChange","vector_leerstring","IfActive","vector_leerstring","NoSigSendType";
BA_DEF_ BO_  "OvtpPushApplication" ENUM  "FALSE","TRUE";
BA_DEF_ BO_  "SCP_FreshnessValueLength" INT 0 512;
BA_DEF_ BO_  "SCP_FreshnessValueTxLength" INT 0 512;
BA_DEF_ BO_  "SCP_AuthInfoTxLength" INT 0 512;
BA_DEF_ BO_  "GenMsgRoutingTimeoutTime" INT 0 5000;
BA_DEF_ BO_  "MessageGateway" ENUM  "No","Yes";
BA_DEF_ BO_  "NmAsrMessage" ENUM  "No","Yes";
BA_DEF_ BO_  "DiagState" ENUM  "No","Yes";
BA_DEF_ BO_  "TpTxIndex" INT 0 536870911;
BA_DEF_ BO_  "DiagRequest" ENUM  "No","Yes";
BA_DEF_ BO_  "DiagResponse" ENUM  "No","Yes";
BA_DEF_ BO_  "GenMsgILSupport" ENUM  "No","Yes";
BA_DEF_DEF_  "FrameRouting" "";
BA_DEF_DEF_  "FrameGatewayNetwork" "NONE";
BA_DEF_DEF_  "NetworkInitialization" "Yes";
BA_DEF_DEF_  "FrameGatewayId" 0;
BA_DEF_DEF_  "EventRateOfChange" 10000;
BA_DEF_DEF_  "GenMsgStartDelayTime" 0;
BA_DEF_DEF_  "GenMsgNrOfRepetition" 1;
BA_DEF_DEF_  "GenMsgDelayTime" 20;
BA_DEF_DEF_  "GenMsgCycleTime" 0;
BA_DEF_DEF_  "GenMsgSendType" "NoMsgSendType";
BA_DEF_DEF_  "U_CD764_MY2022_Tx" "No";
BA_DEF_DEF_  "U_U55X_MY2022_Tx" "No";
BA_DEF_DEF_  "U_CD542_MY2021_Tx" "No";
BA_DEF_DEF_  "ECGUsedTxSignal" "No";
BA_DEF_DEF_  "U_T6_MCA_MY2020_Tx" "No";
BA_DEF_DEF_  "U_P702_MY2021_Tx" "No";
BA_DEF_DEF_  "U_CX727_MY2021_Tx" "No";
BA_DEF_DEF_  "U_CD764_MY2022_Rx" "No";
BA_DEF_DEF_  "U_FNV2_IVI_Rx" "No";
BA_DEF_DEF_  "U_U55X_MY2022_Rx" "No";
BA_DEF_DEF_  "U_CD542_MY2021_Rx" "No";
BA_DEF_DEF_  "ECGUsedRxSignal" "No";
BA_DEF_DEF_  "U_T6_MCA_MY2020_Rx" "No";
BA_DEF_DEF_  "U_P702_MY2021_Rx" "No";
BA_DEF_DEF_  "U_CX727_MY2021_Rx" "No";
BA_DEF_DEF_  "GenSigStartValue" 0;
BA_DEF_DEF_  "MetaData" "No";
BA_DEF_DEF_  "ContentDependant" "No";
BA_DEF_DEF_  "GenSigStartValueInteger" 0;
BA_DEF_DEF_  "UsedOnPgmDBC" "Yes";
BA_DEF_DEF_  "WakeupSignal" "No";
BA_DEF_DEF_  "GenSigInactiveValue" 0;
BA_DEF_DEF_  "GenSigSendType" "NoSigSendType";
BA_DEF_DEF_  "OvtpPushApplication" "FALSE";
BA_DEF_DEF_  "SCP_FreshnessValueLength" 64;
BA_DEF_DEF_  "SCP_FreshnessValueTxLength" 11;
BA_DEF_DEF_  "SCP_AuthInfoTxLength" 53;
BA_DEF_DEF_  "GenMsgRoutingTimeoutTime" 0;
BA_DEF_DEF_  "MessageGateway" "No";
BA_DEF_DEF_  "NmAsrMessage" "No";
BA_DEF_DEF_  "DiagState" "No";
BA_DEF_DEF_  "TpTxIndex" 0;
BA_DEF_DEF_  "DiagRequest" "No";
BA_DEF_DEF_  "DiagResponse" "No";
BA_DEF_DEF_  "GenMsgILSupport" "Yes";
BA_ "FrameRouting" BO_ 611 "FD1_CAN,0x263;";
BA_ "FrameGatewayNetwork" BO_ 611 "FD1_CAN";
BA_ "FrameGatewayId" BO_ 611 611;
BA_ "GenMsgCycleTime" BO_ 264 1000;
BA_ "GenMsgSendType" BO_ 264 5;
BA_ "GenMsgCycleTime" BO_ 1114 1000;
BA_ "GenMsgSendType" BO_ 1114 5;
BA_ "GenMsgCycleTime" BO_ 968 1000;
BA_ "GenMsgSendType" BO_ 968 5;
BA_ "FrameRouting" BO_ 969 "MS1_CAN,0x3C9;";
BA_ "FrameGatewayNetwork" BO_ 969 "MS1_CAN";
BA_ "FrameGatewayId" BO_ 969 969;
BA_ "FrameRouting" BO_ 1006 "FD1_CAN,0x3EE;HS2_CAN,0x3EE";
BA_ "FrameRouting" BO_ 130 "HS2_CAN,0x81;";
BA_ "FrameGatewayNetwork" BO_ 130 "HS2_CAN";
BA_ "FrameGatewayId" BO_ 130 129;
BA_ "GenMsgCycleTime" BO_ 1244 1000;
BA_ "GenMsgSendType" BO_ 1244 0;
BA_ "GenMsgCycleTime" BO_ 1243 1000;
BA_ "GenMsgSendType" BO_ 1243 0;
BA_ "GenMsgCycleTime" BO_ 681 1000;
BA_ "GenMsgSendType" BO_ 681 5;
BA_ "GenMsgCycleTime" BO_ 744 1000;
BA_ "GenMsgSendType" BO_ 744 5;
BA_ "GenMsgCycleTime" BO_ 741 1000;
BA_ "GenMsgSendType" BO_ 741 5;
BA_ "FrameRouting" BO_ 954 "HS1_CAN,0x3BA;";
BA_ "FrameGatewayNetwork" BO_ 954 "HS1_CAN";
BA_ "FrameGatewayId" BO_ 954 954;
BA_ "FrameRouting" BO_ 125 "FD1_CAN,0x7D;";
BA_ "FrameGatewayNetwork" BO_ 125 "FD1_CAN";
BA_ "FrameGatewayId" BO_ 125 125;
BA_ "MessageGateway" BO_ 125 1;
BA_ "NetworkInitialization" BO_ 2612224096 0;
BA_ "GenMsgDelayTime" BO_ 2612224096 0;
BA_ "GenMsgSendType" BO_ 2612224096 1;
BA_ "OvtpPushApplication" BO_ 2612224096 1;
BA_ "TpTxIndex" BO_ 2612224096 464617688;
BA_ "NetworkInitialization" BO_ 2611052760 0;
BA_ "GenMsgDelayTime" BO_ 2611052760 0;
BA_ "GenMsgSendType" BO_ 2611052760 1;
BA_ "TpTxIndex" BO_ 2611052760 463569112;
BA_ "NetworkInitialization" BO_ 2611175520 0;
BA_ "GenMsgDelayTime" BO_ 2611175520 0;
BA_ "GenMsgSendType" BO_ 2611175520 1;
BA_ "TpTxIndex" BO_ 2611175520 463569112;
BA_ "NetworkInitialization" BO_ 2610126944 0;
BA_ "GenMsgDelayTime" BO_ 2610126944 0;
BA_ "GenMsgSendType" BO_ 2610126944 1;
BA_ "TpTxIndex" BO_ 2610126944 462520536;
BA_ "NetworkInitialization" BO_ 2610004184 0;
BA_ "GenMsgDelayTime" BO_ 2610004184 0;
BA_ "GenMsgSendType" BO_ 2610004184 1;
BA_ "TpTxIndex" BO_ 2610004184 462520536;
BA_ "NetworkInitialization" BO_ 2005 0;
BA_ "GenMsgDelayTime" BO_ 2005 0;
BA_ "GenMsgSendType" BO_ 2005 1;
BA_ "DiagRequest" BO_ 2005 1;
BA_ "GenMsgILSupport" BO_ 2005 0;
BA_ "NetworkInitialization" BO_ 2013 0;
BA_ "GenMsgDelayTime" BO_ 2013 0;
BA_ "GenMsgSendType" BO_ 2013 1;
BA_ "DiagResponse" BO_ 2013 1;
BA_ "GenMsgILSupport" BO_ 2013 0;
BA_ "NetworkInitialization" BO_ 1519 0;
BA_ "GenMsgCycleTime" BO_ 1519 1000;
BA_ "GenMsgSendType" BO_ 1519 0;
BA_ "NmAsrMessage" BO_ 1519 1;
BA_ "GenMsgILSupport" BO_ 1519 0;
BA_ "NetworkInitialization" BO_ 2612002008 0;
BA_ "GenMsgDelayTime" BO_ 2612002008 0;
BA_ "GenMsgSendType" BO_ 2612002008 1;
BA_ "TpTxIndex" BO_ 2612002008 464518360;
BA_ "NetworkInitialization" BO_ 2610953432 0;
BA_ "GenMsgDelayTime" BO_ 2610953432 0;
BA_ "GenMsgSendType" BO_ 2610953432 1;
BA_ "TpTxIndex" BO_ 2610953432 463469784;
BA_ "GenMsgCycleTime" BO_ 1082 1000;
BA_ "GenMsgSendType" BO_ 1082 5;
BA_ "TpTxIndex" BO_ 576 41;
BA_ "GenMsgCycleTime" BO_ 1115 1000;
BA_ "GenMsgSendType" BO_ 1115 5;
BA_ "GenMsgCycleTime" BO_ 996 1000;
BA_ "GenMsgSendType" BO_ 996 5;
BA_ "TpTxIndex" BO_ 588 45;
BA_ "GenMsgCycleTime" BO_ 811 1000;
BA_ "GenMsgSendType" BO_ 811 5;
BA_ "GenMsgCycleTime" BO_ 543 1000;
BA_ "GenMsgSendType" BO_ 543 0;
BA_ "GenMsgCycleTime" BO_ 563 1000;
BA_ "GenMsgSendType" BO_ 563 5;
BA_ "GenMsgCycleTime" BO_ 794 1000;
BA_ "GenMsgSendType" BO_ 794 5;
BA_ "TpTxIndex" BO_ 587 44;
BA_ "TpTxIndex" BO_ 579 44;
BA_ "TpTxIndex" BO_ 585 42;
BA_ "TpTxIndex" BO_ 586 43;
BA_ "TpTxIndex" BO_ 578 43;
BA_ "TpTxIndex" BO_ 577 42;
BA_ "FrameRouting" BO_ 356 "HS1_CAN,0x164;";
BA_ "FrameGatewayNetwork" BO_ 356 "HS1_CAN";
BA_ "FrameGatewayId" BO_ 356 356;
BA_ "NetworkInitialization" BO_ 712 0;
BA_ "TpTxIndex" BO_ 712 31;
BA_ "TpTxIndex" BO_ 717 25;
BA_ "TpTxIndex" BO_ 719 24;
BA_ "NetworkInitialization" BO_ 1879 0;
BA_ "GenMsgDelayTime" BO_ 1879 0;
BA_ "GenMsgSendType" BO_ 1879 1;
BA_ "DiagRequest" BO_ 1879 1;
BA_ "GenMsgILSupport" BO_ 1879 0;
BA_ "NetworkInitialization" BO_ 1887 0;
BA_ "GenMsgDelayTime" BO_ 1887 0;
BA_ "GenMsgSendType" BO_ 1887 1;
BA_ "DiagResponse" BO_ 1887 1;
BA_ "GenMsgILSupport" BO_ 1887 0;
BA_ "GenMsgCycleTime" BO_ 1146 50;
BA_ "GenMsgSendType" BO_ 1146 0;
BA_ "TpTxIndex" BO_ 737 53;
BA_ "TpTxIndex" BO_ 745 53;
BA_ "TpTxIndex" BO_ 1195 52;
BA_ "TpTxIndex" BO_ 1185 51;
BA_ "NetworkInitialization" BO_ 1435 0;
BA_ "GenMsgCycleTime" BO_ 1435 1000;
BA_ "GenMsgSendType" BO_ 1435 0;
BA_ "NmAsrMessage" BO_ 1435 1;
BA_ "GenMsgILSupport" BO_ 1435 0;
BA_ "GenMsgCycleTime" BO_ 1109 100;
BA_ "GenMsgSendType" BO_ 1109 5;
BA_ "NetworkInitialization" BO_ 1492 0;
BA_ "GenMsgCycleTime" BO_ 1492 1000;
BA_ "GenMsgSendType" BO_ 1492 0;
BA_ "NmAsrMessage" BO_ 1492 1;
BA_ "GenMsgILSupport" BO_ 1492 0;
BA_ "NetworkInitialization" BO_ 1945 0;
BA_ "GenMsgDelayTime" BO_ 1945 0;
BA_ "GenMsgSendType" BO_ 1945 1;
BA_ "DiagResponse" BO_ 1945 1;
BA_ "GenMsgILSupport" BO_ 1945 0;
BA_ "NetworkInitialization" BO_ 1937 0;
BA_ "GenMsgDelayTime" BO_ 1937 0;
BA_ "GenMsgSendType" BO_ 1937 1;
BA_ "DiagRequest" BO_ 1937 1;
BA_ "GenMsgILSupport" BO_ 1937 0;
BA_ "FrameRouting" BO_ 300 "MS1_CAN,0x12C;";
BA_ "FrameGatewayNetwork" BO_ 300 "MS1_CAN";
BA_ "FrameGatewayId" BO_ 300 300;
BA_ "GenMsgDelayTime" BO_ 2612224006 0;
BA_ "GenMsgSendType" BO_ 2612224006 1;
BA_ "OvtpPushApplication" BO_ 2612224006 1;
BA_ "TpTxIndex" BO_ 2612224006 464525528;
BA_ "GenMsgDelayTime" BO_ 2611175430 0;
BA_ "GenMsgSendType" BO_ 2611175430 1;
BA_ "TpTxIndex" BO_ 2611175430 463476952;
BA_ "GenMsgDelayTime" BO_ 2610960600 0;
BA_ "GenMsgSendType" BO_ 2610960600 1;
BA_ "TpTxIndex" BO_ 2610960600 463476952;
BA_ "GenMsgDelayTime" BO_ 2610126854 0;
BA_ "GenMsgSendType" BO_ 2610126854 1;
BA_ "TpTxIndex" BO_ 2610126854 462428376;
BA_ "GenMsgDelayTime" BO_ 2609912024 0;
BA_ "GenMsgSendType" BO_ 2609912024 1;
BA_ "TpTxIndex" BO_ 2609912024 462428376;
BA_ "GenMsgCycleTime" BO_ 662 1000;
BA_ "GenMsgSendType" BO_ 662 5;
BA_ "FrameRouting" BO_ 837 "FD1_CAN,0x345;HS2_CAN,0x345";
BA_ "FrameRouting" BO_ 1121 "HS2_CAN,0x461;";
BA_ "FrameGatewayNetwork" BO_ 1121 "HS2_CAN";
BA_ "FrameGatewayId" BO_ 1121 1121;
BA_ "FrameRouting" BO_ 670 "MS1_CAN,0x29E;";
BA_ "FrameGatewayNetwork" BO_ 670 "MS1_CAN";
BA_ "FrameGatewayId" BO_ 670 670;
BA_ "FrameRouting" BO_ 669 "MS1_CAN,0x29D;";
BA_ "FrameGatewayNetwork" BO_ 669 "MS1_CAN";
BA_ "FrameGatewayId" BO_ 669 669;
BA_ "GenMsgCycleTime" BO_ 140 1000;
BA_ "GenMsgSendType" BO_ 140 5;
BA_ "GenMsgCycleTime" BO_ 546 1000;
BA_ "GenMsgSendType" BO_ 546 5;
BA_ "FrameRouting" BO_ 1186 "FD1_CAN,0x4A2;";
BA_ "FrameGatewayNetwork" BO_ 1186 "FD1_CAN";
BA_ "FrameGatewayId" BO_ 1186 1186;
BA_ "GenMsgCycleTime" BO_ 1130 1000;
BA_ "GenMsgSendType" BO_ 1130 5;
BA_ "GenMsgCycleTime" BO_ 1042 50;
BA_ "GenMsgSendType" BO_ 1042 0;
BA_ "GenMsgCycleTime" BO_ 1093 100;
BA_ "GenMsgSendType" BO_ 1093 0;
BA_ "FrameRouting" BO_ 1138 "FD1_CAN,0x472;";
BA_ "FrameGatewayNetwork" BO_ 1138 "FD1_CAN";
BA_ "FrameGatewayId" BO_ 1138 1138;
BA_ "FrameRouting" BO_ 1139 "FD1_CAN,0x473;";
BA_ "FrameGatewayNetwork" BO_ 1139 "FD1_CAN";
BA_ "FrameGatewayId" BO_ 1139 1139;
BA_ "FrameRouting" BO_ 1145 "FD1_CAN,0x352;";
BA_ "FrameGatewayNetwork" BO_ 1145 "FD1_CAN";
BA_ "FrameGatewayId" BO_ 1145 850;
BA_ "GenMsgCycleTime" BO_ 1232 1000;
BA_ "GenMsgSendType" BO_ 1232 0;
BA_ "FrameRouting" BO_ 1141 "FD1_CAN,0x475;";
BA_ "FrameGatewayNetwork" BO_ 1141 "FD1_CAN";
BA_ "FrameGatewayId" BO_ 1141 1141;
BA_ "GenMsgCycleTime" BO_ 631 1000;
BA_ "GenMsgSendType" BO_ 631 5;
BA_ "FrameRouting" BO_ 1140 "FD1_CAN,0x474;";
BA_ "FrameGatewayNetwork" BO_ 1140 "FD1_CAN";
BA_ "FrameGatewayId" BO_ 1140 1140;
BA_ "FrameRouting" BO_ 873 "FD1_CAN,0x369;";
BA_ "FrameGatewayNetwork" BO_ 873 "FD1_CAN";
BA_ "FrameGatewayId" BO_ 873 873;
BA_ "U_CD764_MY2022_Rx" SG_ 611 AwdTerrMdeChng_D_Rdy 1;
BA_ "U_T6_MCA_MY2020_Rx" SG_ 611 AwdTerrMdeChng_D_Rdy 1;
BA_ "U_CD764_MY2022_Rx" SG_ 611 AwdTerrMde_D_Actl 1;
BA_ "U_T6_MCA_MY2020_Rx" SG_ 611 AwdTerrMde_D_Actl 1;
BA_ "U_CD764_MY2022_Rx" SG_ 611 AwdSys_D_Stat 1;
BA_ "U_T6_MCA_MY2020_Rx" SG_ 611 AwdSys_D_Stat 1;
BA_ "U_CD764_MY2022_Rx" SG_ 611 AwdStat_D_RqDsply 1;
BA_ "U_U55X_MY2022_Rx" SG_ 611 AwdStat_D_RqDsply 1;
BA_ "U_CD542_MY2021_Rx" SG_ 611 AwdStat_D_RqDsply 1;
BA_ "U_T6_MCA_MY2020_Rx" SG_ 611 AwdStat_D_RqDsply 1;
BA_ "U_P702_MY2021_Rx" SG_ 611 AwdStat_D_RqDsply 1;
BA_ "ContentDependant" SG_ 611 AwdStat_D_RqDsply 1;
BA_ "U_CD764_MY2022_Rx" SG_ 611 AwdLck_D_Stat 1;
BA_ "U_U55X_MY2022_Rx" SG_ 611 AwdLck_D_Stat 1;
BA_ "U_T6_MCA_MY2020_Rx" SG_ 611 AwdLck_D_Stat 1;
BA_ "U_P702_MY2021_Rx" SG_ 611 AwdLck_D_Stat 1;
BA_ "U_CD764_MY2022_Rx" SG_ 611 AwdSrvcRqd_B_Rq 1;
BA_ "U_U55X_MY2022_Rx" SG_ 611 AwdSrvcRqd_B_Rq 1;
BA_ "U_CD542_MY2021_Rx" SG_ 611 AwdSrvcRqd_B_Rq 1;
BA_ "U_T6_MCA_MY2020_Rx" SG_ 611 AwdSrvcRqd_B_Rq 1;
BA_ "U_P702_MY2021_Rx" SG_ 611 AwdSrvcRqd_B_Rq 1;
BA_ "ContentDependant" SG_ 611 AwdSrvcRqd_B_Rq 1;
BA_ "U_CD764_MY2022_Rx" SG_ 611 AwdLck_Tq_Rq 1;
BA_ "U_U55X_MY2022_Rx" SG_ 611 AwdLck_Tq_Rq 1;
BA_ "U_T6_MCA_MY2020_Rx" SG_ 611 AwdLck_Tq_Rq 1;
BA_ "U_P702_MY2021_Rx" SG_ 611 AwdLck_Tq_Rq 1;
BA_ "ContentDependant" SG_ 611 AwdLck_Tq_Rq 1;
BA_ "U_CD764_MY2022_Rx" SG_ 611 TrnAout_Tq_RqMx 1;
BA_ "U_T6_MCA_MY2020_Rx" SG_ 611 TrnAout_Tq_RqMx 1;
BA_ "GenSigStartValue" SG_ 611 TrnAout_Tq_RqMx 8191;
BA_ "GenSigStartValueInteger" SG_ 611 TrnAout_Tq_RqMx 8191;
BA_ "U_U55X_MY2022_Rx" SG_ 611 AwdOffRoadMode_D_Stats 1;
BA_ "U_T6_MCA_MY2020_Rx" SG_ 611 AwdOffRoadMode_D_Stats 1;
BA_ "U_P702_MY2021_Rx" SG_ 611 AwdOffRoadMode_D_Stats 1;
BA_ "U_CD764_MY2022_Rx" SG_ 611 AwdOffRoadMode_D_Stats 1;
BA_ "U_CD542_MY2021_Rx" SG_ 611 AwdOffRoadMode_D_Stats 1;
BA_ "U_CD764_MY2022_Rx" SG_ 611 AwdLoLamp_D_RqDsply 1;
BA_ "U_U55X_MY2022_Rx" SG_ 611 AwdLoLamp_D_RqDsply 1;
BA_ "U_T6_MCA_MY2020_Rx" SG_ 611 AwdLoLamp_D_RqDsply 1;
BA_ "U_P702_MY2021_Rx" SG_ 611 AwdLoLamp_D_RqDsply 1;
BA_ "U_CD764_MY2022_Rx" SG_ 611 AwdHiLamp_D_RqDsply 1;
BA_ "U_U55X_MY2022_Rx" SG_ 611 AwdHiLamp_D_RqDsply 1;
BA_ "U_T6_MCA_MY2020_Rx" SG_ 611 AwdHiLamp_D_RqDsply 1;
BA_ "U_P702_MY2021_Rx" SG_ 611 AwdHiLamp_D_RqDsply 1;
BA_ "U_CD764_MY2022_Rx" SG_ 611 AwdAutoLamp_D_RqDsply 1;
BA_ "U_U55X_MY2022_Rx" SG_ 611 AwdAutoLamp_D_RqDsply 1;
BA_ "U_T6_MCA_MY2020_Rx" SG_ 611 AwdAutoLamp_D_RqDsply 1;
BA_ "U_P702_MY2021_Rx" SG_ 611 AwdAutoLamp_D_RqDsply 1;
BA_ "U_CD764_MY2022_Rx" SG_ 611 Awd2wdLamp_D_RqDsply 1;
BA_ "U_U55X_MY2022_Rx" SG_ 611 Awd2wdLamp_D_RqDsply 1;
BA_ "U_T6_MCA_MY2020_Rx" SG_ 611 Awd2wdLamp_D_RqDsply 1;
BA_ "U_P702_MY2021_Rx" SG_ 611 Awd2wdLamp_D_RqDsply 1;
BA_ "U_CD542_MY2021_Rx" SG_ 611 AwdRnge_D_Actl 1;
BA_ "U_CD764_MY2022_Rx" SG_ 611 AwdRnge_D_Actl 1;
BA_ "U_U55X_MY2022_Rx" SG_ 611 AwdRnge_D_Actl 1;
BA_ "U_T6_MCA_MY2020_Rx" SG_ 611 AwdRnge_D_Actl 1;
BA_ "U_P702_MY2021_Rx" SG_ 611 AwdRnge_D_Actl 1;
BA_ "GenSigStartValue" SG_ 611 AwdRnge_D_Actl 7;
BA_ "GenSigStartValueInteger" SG_ 611 AwdRnge_D_Actl 7;
BA_ "U_CD764_MY2022_Rx" SG_ 611 NtrlTowAvail_B_Stat 1;
BA_ "U_U55X_MY2022_Rx" SG_ 611 NtrlTowAvail_B_Stat 1;
BA_ "U_T6_MCA_MY2020_Rx" SG_ 611 NtrlTowAvail_B_Stat 1;
BA_ "U_P702_MY2021_Rx" SG_ 611 NtrlTowAvail_B_Stat 1;
BA_ "U_CD764_MY2022_Rx" SG_ 611 AwdDrvMde_D_Stat 1;
BA_ "U_T6_MCA_MY2020_Rx" SG_ 611 AwdDrvMde_D_Stat 1;
BA_ "U_CD764_MY2022_Rx" SG_ 264 CabnAmb_Te_Actl_UB 1;
BA_ "U_CD542_MY2021_Rx" SG_ 264 CabnAmb_Te_Actl_UB 1;
BA_ "U_U55X_MY2022_Rx" SG_ 264 CabnAmb_Te_Actl_UB 1;
BA_ "U_T6_MCA_MY2020_Rx" SG_ 264 CabnAmb_Te_Actl_UB 1;
BA_ "U_CD764_MY2022_Rx" SG_ 264 CabnAmb_Te_Actl 1;
BA_ "U_U55X_MY2022_Rx" SG_ 264 CabnAmb_Te_Actl 1;
BA_ "U_CD542_MY2021_Rx" SG_ 264 CabnAmb_Te_Actl 1;
BA_ "U_T6_MCA_MY2020_Rx" SG_ 264 CabnAmb_Te_Actl 1;
BA_ "GenSigStartValueInteger" SG_ 264 CabnAmb_Te_Actl 114;
BA_ "U_CD764_MY2022_Rx" SG_ 264 ChrgCordLck_D_Stat_UB 1;
BA_ "U_CD542_MY2021_Rx" SG_ 264 ChrgCordLck_D_Stat_UB 1;
BA_ "U_U55X_MY2022_Rx" SG_ 264 ChrgCordLck_D_Stat_UB 1;
BA_ "U_T6_MCA_MY2020_Rx" SG_ 264 ChrgCordLck_D_Stat_UB 1;
BA_ "U_P702_MY2021_Rx" SG_ 264 ChrgCordLck_D_Stat_UB 1;
BA_ "U_CD764_MY2022_Rx" SG_ 264 ChrgCordLck_D_Stat 1;
BA_ "U_CD542_MY2021_Rx" SG_ 264 ChrgCordLck_D_Stat 1;
BA_ "U_U55X_MY2022_Rx" SG_ 264 ChrgCordLck_D_Stat 1;
BA_ "U_T6_MCA_MY2020_Rx" SG_ 264 ChrgCordLck_D_Stat 1;
BA_ "U_P702_MY2021_Rx" SG_ 264 ChrgCordLck_D_Stat 1;
BA_ "U_U55X_MY2022_Rx" SG_ 264 PwPckTqRdy_B_Dsply 1;
BA_ "U_CD764_MY2022_Rx" SG_ 264 PwPckTqRdy_B_Dsply 1;
BA_ "U_CD542_MY2021_Rx" SG_ 264 PwPckTqRdy_B_Dsply 1;
BA_ "U_T6_MCA_MY2020_Rx" SG_ 264 PwPckTqRdy_B_Dsply 1;
BA_ "U_P702_MY2021_Rx" SG_ 264 PwPckTqRdy_B_Dsply 1;
BA_ "U_CD764_MY2022_Rx" SG_ 264 HtrnOvrTeLamp_B_Dsply_UB 1;
BA_ "U_CD542_MY2021_Rx" SG_ 264 HtrnOvrTeLamp_B_Dsply_UB 1;
BA_ "U_T6_MCA_MY2020_Rx" SG_ 264 HtrnOvrTeLamp_B_Dsply_UB 1;
BA_ "U_P702_MY2021_Rx" SG_ 264 HtrnOvrTeLamp_B_Dsply_UB 1;
BA_ "U_CD764_MY2022_Rx" SG_ 264 HtrnOvrTeLamp_B_Dsply 1;
BA_ "U_CD542_MY2021_Rx" SG_ 264 HtrnOvrTeLamp_B_Dsply 1;
BA_ "U_T6_MCA_MY2020_Rx" SG_ 264 HtrnOvrTeLamp_B_Dsply 1;
BA_ "U_P702_MY2021_Rx" SG_ 264 HtrnOvrTeLamp_B_Dsply 1;
BA_ "U_CD542_MY2021_Rx" SG_ 264 PwPckTqRdy_B_Dsply_UB 1;
BA_ "U_U55X_MY2022_Rx" SG_ 264 PwPckTqRdy_B_Dsply_UB 1;
BA_ "U_CD764_MY2022_Rx" SG_ 264 PwPckTqRdy_B_Dsply_UB 1;
BA_ "U_T6_MCA_MY2020_Rx" SG_ 264 PwPckTqRdy_B_Dsply_UB 1;
BA_ "U_P702_MY2021_Rx" SG_ 264 PwPckTqRdy_B_Dsply_UB 1;
BA_ "U_U55X_MY2022_Rx" SG_ 264 BpedDrvAppl_D_Actl 1;
BA_ "U_CD764_MY2022_Rx" SG_ 264 BpedDrvAppl_D_Actl 1;
BA_ "U_CD542_MY2021_Rx" SG_ 264 BpedDrvAppl_D_Actl 1;
BA_ "U_T6_MCA_MY2020_Rx" SG_ 264 BpedDrvAppl_D_Actl 1;
BA_ "U_P702_MY2021_Rx" SG_ 264 BpedDrvAppl_D_Actl 1;
BA_ "GenSigSendType" SG_ 264 BpedDrvAppl_D_Actl 3;
BA_ "GenSigStartValue" SG_ 264 BpedDrvAppl_D_Actl 1;
BA_ "GenSigStartValueInteger" SG_ 264 BpedDrvAppl_D_Actl 1;
BA_ "U_U55X_MY2022_Rx" SG_ 264 BpedDrvAppl_D_Actl_UB 1;
BA_ "U_CD764_MY2022_Rx" SG_ 264 BpedDrvAppl_D_Actl_UB 1;
BA_ "U_CD542_MY2021_Rx" SG_ 264 BpedDrvAppl_D_Actl_UB 1;
BA_ "U_T6_MCA_MY2020_Rx" SG_ 264 BpedDrvAppl_D_Actl_UB 1;
BA_ "U_P702_MY2021_Rx" SG_ 264 BpedDrvAppl_D_Actl_UB 1;
BA_ "U_CD764_MY2022_Rx" SG_ 264 BattTracSoc_Pc_Dsply_UB 1;
BA_ "U_U55X_MY2022_Rx" SG_ 264 BattTracSoc_Pc_Dsply_UB 1;
BA_ "U_CD542_MY2021_Rx" SG_ 264 BattTracSoc_Pc_Dsply_UB 1;
BA_ "U_T6_MCA_MY2020_Rx" SG_ 264 BattTracSoc_Pc_Dsply_UB 1;
BA_ "U_P702_MY2021_Rx" SG_ 264 BattTracSoc_Pc_Dsply_UB 1;
BA_ "U_CD764_MY2022_Rx" SG_ 264 BattTracSoc_Pc_Dsply 1;
BA_ "U_U55X_MY2022_Rx" SG_ 264 BattTracSoc_Pc_Dsply 1;
BA_ "U_CD542_MY2021_Rx" SG_ 264 BattTracSoc_Pc_Dsply 1;
BA_ "U_T6_MCA_MY2020_Rx" SG_ 264 BattTracSoc_Pc_Dsply 1;
BA_ "U_P702_MY2021_Rx" SG_ 264 BattTracSoc_Pc_Dsply 1;
BA_ "GenSigStartValue" SG_ 264 BattTracSoc_Pc_Dsply 254;
BA_ "GenSigStartValueInteger" SG_ 264 BattTracSoc_Pc_Dsply 254;
BA_ "U_U55X_MY2022_Tx" SG_ 1114 TrailCtlSwtch_B_Stat2 1;
BA_ "U_P702_MY2021_Tx" SG_ 1114 TrailCtlSwtch_B_Stat2 1;
BA_ "GenSigSendType" SG_ 1114 TrailCtlSwtch_B_Stat2 3;
BA_ "U_U55X_MY2022_Tx" SG_ 1114 TrlBrkInitOut_D_Rq 1;
BA_ "U_U55X_MY2022_Rx" SG_ 1114 TrlBrkInitOut_D_Rq 1;
BA_ "U_T6_MCA_MY2020_Rx" SG_ 1114 TrlBrkInitOut_D_Rq 1;
BA_ "U_P702_MY2021_Rx" SG_ 1114 TrlBrkInitOut_D_Rq 1;
BA_ "GenSigSendType" SG_ 1114 TrlBrkInitOut_D_Rq 3;
BA_ "U_CD764_MY2022_Tx" SG_ 968 RvltnMatchAllw_D_Rq 1;
BA_ "U_CD542_MY2021_Tx" SG_ 968 RvltnMatchAllw_D_Rq 1;
BA_ "U_T6_MCA_MY2020_Tx" SG_ 968 RvltnMatchAllw_D_Rq 1;
BA_ "GenSigSendType" SG_ 968 RvltnMatchAllw_D_Rq 3;
BA_ "U_CD764_MY2022_Tx" SG_ 968 BrkDrvMde_D_Rq 1;
BA_ "U_CD542_MY2021_Tx" SG_ 968 BrkDrvMde_D_Rq 1;
BA_ "U_T6_MCA_MY2020_Tx" SG_ 968 BrkDrvMde_D_Rq 1;
BA_ "GenSigSendType" SG_ 968 BrkDrvMde_D_Rq 3;
BA_ "U_CD764_MY2022_Tx" SG_ 968 LnchCtl_N_Rq 1;
BA_ "GenSigSendType" SG_ 968 LnchCtl_N_Rq 3;
BA_ "U_CD764_MY2022_Tx" SG_ 968 LnchCtl_D_Rq 1;
BA_ "GenSigSendType" SG_ 968 LnchCtl_D_Rq 3;
BA_ "U_CD764_MY2022_Tx" SG_ 968 CurrentColor_CmdGage 1;
BA_ "GenSigSendType" SG_ 968 CurrentColor_CmdGage 3;
BA_ "GenSigStartValue" SG_ 968 CurrentColor_CmdGage 8;
BA_ "GenSigStartValueInteger" SG_ 968 CurrentColor_CmdGage 8;
BA_ "U_CD764_MY2022_Tx" SG_ 968 BlendedColor_CmdGage 1;
BA_ "GenSigSendType" SG_ 968 BlendedColor_CmdGage 3;
BA_ "GenSigStartValue" SG_ 968 BlendedColor_CmdGage 2;
BA_ "GenSigStartValueInteger" SG_ 968 BlendedColor_CmdGage 2;
BA_ "U_CD764_MY2022_Tx" SG_ 968 BlendColorRed_CmdGage 1;
BA_ "GenSigSendType" SG_ 968 BlendColorRed_CmdGage 3;
BA_ "U_CD764_MY2022_Tx" SG_ 968 BlendColorGrn_CmdGage 1;
BA_ "GenSigSendType" SG_ 968 BlendColorGrn_CmdGage 3;
BA_ "U_CD764_MY2022_Tx" SG_ 968 BlendColorBlue_CmdGage 1;
BA_ "GenSigSendType" SG_ 968 BlendColorBlue_CmdGage 3;
BA_ "U_CD764_MY2022_Tx" SG_ 968 Dimming_Level_Cmd 1;
BA_ "GenSigSendType" SG_ 968 Dimming_Level_Cmd 3;
BA_ "U_CD764_MY2022_Tx" SG_ 968 Current_Color_Cmd 1;
BA_ "GenSigSendType" SG_ 968 Current_Color_Cmd 3;
BA_ "GenSigStartValue" SG_ 968 Current_Color_Cmd 8;
BA_ "GenSigStartValueInteger" SG_ 968 Current_Color_Cmd 8;
BA_ "U_CD764_MY2022_Tx" SG_ 968 BlendedColorRed_Cmd 1;
BA_ "GenSigSendType" SG_ 968 BlendedColorRed_Cmd 3;
BA_ "U_CD764_MY2022_Tx" SG_ 968 BlendedColorGreen_Cmd 1;
BA_ "GenSigSendType" SG_ 968 BlendedColorGreen_Cmd 3;
BA_ "U_CD764_MY2022_Tx" SG_ 968 BlendedColorBlue_Cmd 1;
BA_ "GenSigSendType" SG_ 968 BlendedColorBlue_Cmd 3;
BA_ "U_CD764_MY2022_Tx" SG_ 968 BlendedColor_Cmd 1;
BA_ "GenSigSendType" SG_ 968 BlendedColor_Cmd 3;
BA_ "GenSigStartValue" SG_ 968 BlendedColor_Cmd 2;
BA_ "GenSigStartValueInteger" SG_ 968 BlendedColor_Cmd 2;
BA_ "U_CD764_MY2022_Tx" SG_ 968 SuspDrvMde_D_Rq 1;
BA_ "U_T6_MCA_MY2020_Tx" SG_ 968 SuspDrvMde_D_Rq 1;
BA_ "GenSigSendType" SG_ 968 SuspDrvMde_D_Rq 3;
BA_ "U_CD764_MY2022_Tx" SG_ 968 SlMde_D_Rq 1;
BA_ "U_U55X_MY2022_Tx" SG_ 968 SlMde_D_Rq 1;
BA_ "U_CD542_MY2021_Tx" SG_ 968 SlMde_D_Rq 1;
BA_ "U_T6_MCA_MY2020_Tx" SG_ 968 SlMde_D_Rq 1;
BA_ "U_P702_MY2021_Tx" SG_ 968 SlMde_D_Rq 1;
BA_ "GenSigSendType" SG_ 968 SlMde_D_Rq 3;
BA_ "GenSigStartValue" SG_ 968 SlMde_D_Rq 2;
BA_ "GenSigStartValueInteger" SG_ 968 SlMde_D_Rq 2;
BA_ "U_CD764_MY2022_Tx" SG_ 968 IsaOffst_D_Rq 1;
BA_ "U_U55X_MY2022_Tx" SG_ 968 IsaOffst_D_Rq 1;
BA_ "U_CD542_MY2021_Tx" SG_ 968 IsaOffst_D_Rq 1;
BA_ "U_T6_MCA_MY2020_Tx" SG_ 968 IsaOffst_D_Rq 1;
BA_ "U_P702_MY2021_Tx" SG_ 968 IsaOffst_D_Rq 1;
BA_ "GenSigSendType" SG_ 968 IsaOffst_D_Rq 3;
BA_ "GenSigStartValue" SG_ 968 IsaOffst_D_Rq 14;
BA_ "GenSigStartValueInteger" SG_ 968 IsaOffst_D_Rq 14;
BA_ "U_CD764_MY2022_Rx" SG_ 969 Dimming_Level_Stat 1;
BA_ "U_T6_MCA_MY2020_Rx" SG_ 969 Dimming_Level_Stat 1;
BA_ "U_CD764_MY2022_Rx" SG_ 969 Current_Color_Stat 1;
BA_ "U_T6_MCA_MY2020_Rx" SG_ 969 Current_Color_Stat 1;
BA_ "GenSigStartValue" SG_ 969 Current_Color_Stat 8;
BA_ "GenSigStartValueInteger" SG_ 969 Current_Color_Stat 8;
BA_ "U_CD764_MY2022_Rx" SG_ 969 BlendedColorRed_Stat 1;
BA_ "U_T6_MCA_MY2020_Rx" SG_ 969 BlendedColorRed_Stat 1;
BA_ "U_CD764_MY2022_Rx" SG_ 969 BlendedColorGreen_Stat 1;
BA_ "U_T6_MCA_MY2020_Rx" SG_ 969 BlendedColorGreen_Stat 1;
BA_ "U_CD764_MY2022_Rx" SG_ 969 BlendedColorBlue_Stat 1;
BA_ "U_T6_MCA_MY2020_Rx" SG_ 969 BlendedColorBlue_Stat 1;
BA_ "U_CD764_MY2022_Rx" SG_ 969 BlendedColor_Stat 1;
BA_ "U_T6_MCA_MY2020_Rx" SG_ 969 BlendedColor_Stat 1;
BA_ "GenSigStartValue" SG_ 969 BlendedColor_Stat 2;
BA_ "GenSigStartValueInteger" SG_ 969 BlendedColor_Stat 2;
BA_ "U_CD764_MY2022_Rx" SG_ 969 TurnLampRrOut_B_Stat 1;
BA_ "U_T6_MCA_MY2020_Rx" SG_ 969 TurnLampRrOut_B_Stat 1;
BA_ "ContentDependant" SG_ 969 TurnLampRrOut_B_Stat 1;
BA_ "WakeupSignal" SG_ 969 TurnLampRrOut_B_Stat 1;
BA_ "U_CD764_MY2022_Rx" SG_ 969 TurnLampRlOut_B_Stat 1;
BA_ "U_T6_MCA_MY2020_Rx" SG_ 969 TurnLampRlOut_B_Stat 1;
BA_ "ContentDependant" SG_ 969 TurnLampRlOut_B_Stat 1;
BA_ "WakeupSignal" SG_ 969 TurnLampRlOut_B_Stat 1;
BA_ "U_CD764_MY2022_Rx" SG_ 1006 PersIndexIpmb_D_Actl 1;
BA_ "U_CD542_MY2021_Rx" SG_ 1006 PersIndexIpmb_D_Actl 1;
BA_ "U_T6_MCA_MY2020_Rx" SG_ 1006 PersIndexIpmb_D_Actl 1;
BA_ "GenSigStartValue" SG_ 1006 PersIndexIpmb_D_Actl 4;
BA_ "GenSigStartValueInteger" SG_ 1006 PersIndexIpmb_D_Actl 4;
BA_ "U_CD764_MY2022_Rx" SG_ 1006 FeatNoIpmbActl 1;
BA_ "U_CD542_MY2021_Rx" SG_ 1006 FeatNoIpmbActl 1;
BA_ "U_P702_MY2021_Rx" SG_ 1006 FeatNoIpmbActl 1;
BA_ "U_U55X_MY2022_Rx" SG_ 1006 FeatNoIpmbActl 1;
BA_ "U_T6_MCA_MY2020_Rx" SG_ 1006 FeatNoIpmbActl 1;
BA_ "U_CD764_MY2022_Rx" SG_ 1006 FeatConfigIpmbActl 1;
BA_ "U_CD542_MY2021_Rx" SG_ 1006 FeatConfigIpmbActl 1;
BA_ "U_P702_MY2021_Rx" SG_ 1006 FeatConfigIpmbActl 1;
BA_ "U_U55X_MY2022_Rx" SG_ 1006 FeatConfigIpmbActl 1;
BA_ "U_T6_MCA_MY2020_Rx" SG_ 1006 FeatConfigIpmbActl 1;
BA_ "U_CD764_MY2022_Rx" SG_ 130 EngExhMdeQuiet_B_RqDrv2 1;
BA_ "U_CD764_MY2022_Rx" SG_ 130 SteWhlSwtchHome_B_Stat 1;
BA_ "U_U55X_MY2022_Rx" SG_ 130 SteWhlSwtchHome_B_Stat 1;
BA_ "U_CD542_MY2021_Rx" SG_ 130 SteWhlSwtchHome_B_Stat 1;
BA_ "U_T6_MCA_MY2020_Rx" SG_ 130 SteWhlSwtchHome_B_Stat 1;
BA_ "U_P702_MY2021_Rx" SG_ 130 SteWhlSwtchHome_B_Stat 1;
BA_ "U_CD764_MY2022_Rx" SG_ 130 SteWhlSwtchInfo_B_Stat 1;
BA_ "U_CD542_MY2021_Rx" SG_ 130 SteWhlSwtchInfo_B_Stat 1;
BA_ "U_T6_MCA_MY2020_Rx" SG_ 130 SteWhlSwtchInfo_B_Stat 1;
BA_ "ContentDependant" SG_ 130 SelDrvMdeSwtch3_D_Stat4 1;
BA_ "U_CD764_MY2022_Rx" SG_ 130 SteWhlSwtchView_B_Stat 1;
BA_ "U_CD542_MY2021_Rx" SG_ 130 SteWhlSwtchView_B_Stat 1;
BA_ "U_T6_MCA_MY2020_Rx" SG_ 130 SteWhlSwtchView_B_Stat 1;
BA_ "WakeupSignal" SG_ 130 SteWhlSwtchView_B_Stat 1;
BA_ "U_CD764_MY2022_Rx" SG_ 130 SteWhlSwtchSet_B_Stat 1;
BA_ "U_CD542_MY2021_Rx" SG_ 130 SteWhlSwtchSet_B_Stat 1;
BA_ "U_T6_MCA_MY2020_Rx" SG_ 130 SteWhlSwtchSet_B_Stat 1;
BA_ "WakeupSignal" SG_ 130 SteWhlSwtchSet_B_Stat 1;
BA_ "U_CD542_MY2021_Rx" SG_ 130 SteWhlSwtchPhon_B_Stat 1;
BA_ "U_CD764_MY2022_Rx" SG_ 130 SteWhlSwtchPhon_B_Stat 1;
BA_ "U_U55X_MY2022_Rx" SG_ 130 SteWhlSwtchPhon_B_Stat 1;
BA_ "U_T6_MCA_MY2020_Rx" SG_ 130 SteWhlSwtchPhon_B_Stat 1;
BA_ "WakeupSignal" SG_ 130 SteWhlSwtchPhon_B_Stat 1;
BA_ "U_CD764_MY2022_Rx" SG_ 130 SteWhlSwtchNav_B_Stat 1;
BA_ "U_CD542_MY2021_Rx" SG_ 130 SteWhlSwtchNav_B_Stat 1;
BA_ "U_T6_MCA_MY2020_Rx" SG_ 130 SteWhlSwtchNav_B_Stat 1;
BA_ "WakeupSignal" SG_ 130 SteWhlSwtchNav_B_Stat 1;
BA_ "U_CD542_MY2021_Rx" SG_ 130 SteWhlSwtchMed_B_Stat 1;
BA_ "U_CD764_MY2022_Rx" SG_ 130 SteWhlSwtchMed_B_Stat 1;
BA_ "U_U55X_MY2022_Rx" SG_ 130 SteWhlSwtchMed_B_Stat 1;
BA_ "U_T6_MCA_MY2020_Rx" SG_ 130 SteWhlSwtchMed_B_Stat 1;
BA_ "WakeupSignal" SG_ 130 SteWhlSwtchMed_B_Stat 1;
BA_ "U_CD764_MY2022_Rx" SG_ 130 SteWhlSwtchIod_B_Stat 1;
BA_ "U_CD542_MY2021_Rx" SG_ 130 SteWhlSwtchIod_B_Stat 1;
BA_ "U_T6_MCA_MY2020_Rx" SG_ 130 SteWhlSwtchIod_B_Stat 1;
BA_ "WakeupSignal" SG_ 130 SteWhlSwtchIod_B_Stat 1;
BA_ "U_CD764_MY2022_Rx" SG_ 130 SteWhlSwtchHud_B_Stat 1;
BA_ "U_CD542_MY2021_Rx" SG_ 130 SteWhlSwtchHud_B_Stat 1;
BA_ "U_U55X_MY2022_Rx" SG_ 130 SteWhlSwtchHud_B_Stat 1;
BA_ "U_T6_MCA_MY2020_Rx" SG_ 130 SteWhlSwtchHud_B_Stat 1;
BA_ "WakeupSignal" SG_ 130 SteWhlSwtchHud_B_Stat 1;
BA_ "U_CD764_MY2022_Rx" SG_ 130 SteWhlSwtchBack_B_Stat 1;
BA_ "U_CD542_MY2021_Rx" SG_ 130 SteWhlSwtchBack_B_Stat 1;
BA_ "U_P702_MY2021_Rx" SG_ 130 SteWhlSwtchBack_B_Stat 1;
BA_ "U_U55X_MY2022_Rx" SG_ 130 SteWhlSwtchBack_B_Stat 1;
BA_ "U_T6_MCA_MY2020_Rx" SG_ 130 SteWhlSwtchBack_B_Stat 1;
BA_ "WakeupSignal" SG_ 130 SteWhlSwtchBack_B_Stat 1;
BA_ "U_CD764_MY2022_Rx" SG_ 130 SteWhlSwtchMenu_B_Stat 1;
BA_ "U_U55X_MY2022_Rx" SG_ 130 SteWhlSwtchMenu_B_Stat 1;
BA_ "U_CD542_MY2021_Rx" SG_ 130 SteWhlSwtchMenu_B_Stat 1;
BA_ "U_T6_MCA_MY2020_Rx" SG_ 130 SteWhlSwtchMenu_B_Stat 1;
BA_ "U_P702_MY2021_Rx" SG_ 130 SteWhlSwtchMenu_B_Stat 1;
BA_ "WakeupSignal" SG_ 130 SteWhlSwtchMenu_B_Stat 1;
BA_ "U_CD764_MY2022_Rx" SG_ 130 SteEffortInc_B_RqDrv 1;
BA_ "U_CD542_MY2021_Rx" SG_ 130 SteEffortInc_B_RqDrv 1;
BA_ "U_T6_MCA_MY2020_Rx" SG_ 130 SteEffortInc_B_RqDrv 1;
BA_ "U_CD764_MY2022_Rx" SG_ 130 SelDrvMdeInc_B_RqDrv 1;
BA_ "U_CD542_MY2021_Rx" SG_ 130 SelDrvMdeInc_B_RqDrv 1;
BA_ "U_T6_MCA_MY2020_Rx" SG_ 130 SelDrvMdeInc_B_RqDrv 1;
BA_ "U_CD764_MY2022_Rx" SG_ 130 SelDrvMdeDec_B_RqDrv 1;
BA_ "U_CD542_MY2021_Rx" SG_ 130 SelDrvMdeDec_B_RqDrv 1;
BA_ "U_T6_MCA_MY2020_Rx" SG_ 130 SelDrvMdeDec_B_RqDrv 1;
BA_ "U_CD764_MY2022_Rx" SG_ 130 SuspDampInc_B_RqDrv 1;
BA_ "U_CD542_MY2021_Rx" SG_ 130 SuspDampInc_B_RqDrv 1;
BA_ "U_T6_MCA_MY2020_Rx" SG_ 130 SuspDampInc_B_RqDrv 1;
BA_ "U_CD764_MY2022_Rx" SG_ 130 SteWhlSwtchUp_B_Stat 1;
BA_ "U_U55X_MY2022_Rx" SG_ 130 SteWhlSwtchUp_B_Stat 1;
BA_ "U_CD542_MY2021_Rx" SG_ 130 SteWhlSwtchUp_B_Stat 1;
BA_ "U_T6_MCA_MY2020_Rx" SG_ 130 SteWhlSwtchUp_B_Stat 1;
BA_ "U_P702_MY2021_Rx" SG_ 130 SteWhlSwtchUp_B_Stat 1;
BA_ "WakeupSignal" SG_ 130 SteWhlSwtchUp_B_Stat 1;
BA_ "U_U55X_MY2022_Rx" SG_ 130 SteWhlSwtchRght_B_Stat 1;
BA_ "U_CD764_MY2022_Rx" SG_ 130 SteWhlSwtchRght_B_Stat 1;
BA_ "U_CD542_MY2021_Rx" SG_ 130 SteWhlSwtchRght_B_Stat 1;
BA_ "U_T6_MCA_MY2020_Rx" SG_ 130 SteWhlSwtchRght_B_Stat 1;
BA_ "WakeupSignal" SG_ 130 SteWhlSwtchRght_B_Stat 1;
BA_ "U_CD764_MY2022_Rx" SG_ 130 SteWhlSwtchOk_B_Stat 1;
BA_ "U_U55X_MY2022_Rx" SG_ 130 SteWhlSwtchOk_B_Stat 1;
BA_ "U_CD542_MY2021_Rx" SG_ 130 SteWhlSwtchOk_B_Stat 1;
BA_ "U_T6_MCA_MY2020_Rx" SG_ 130 SteWhlSwtchOk_B_Stat 1;
BA_ "U_P702_MY2021_Rx" SG_ 130 SteWhlSwtchOk_B_Stat 1;
BA_ "WakeupSignal" SG_ 130 SteWhlSwtchOk_B_Stat 1;
BA_ "U_U55X_MY2022_Rx" SG_ 130 SteWhlSwtchLeft_B_Stat 1;
BA_ "U_CD764_MY2022_Rx" SG_ 130 SteWhlSwtchLeft_B_Stat 1;
BA_ "U_CD542_MY2021_Rx" SG_ 130 SteWhlSwtchLeft_B_Stat 1;
BA_ "U_T6_MCA_MY2020_Rx" SG_ 130 SteWhlSwtchLeft_B_Stat 1;
BA_ "WakeupSignal" SG_ 130 SteWhlSwtchLeft_B_Stat 1;
BA_ "U_CD764_MY2022_Rx" SG_ 130 SteWhlSwtchDown_B_Stat 1;
BA_ "U_U55X_MY2022_Rx" SG_ 130 SteWhlSwtchDown_B_Stat 1;
BA_ "U_CD542_MY2021_Rx" SG_ 130 SteWhlSwtchDown_B_Stat 1;
BA_ "U_T6_MCA_MY2020_Rx" SG_ 130 SteWhlSwtchDown_B_Stat 1;
BA_ "U_P702_MY2021_Rx" SG_ 130 SteWhlSwtchDown_B_Stat 1;
BA_ "WakeupSignal" SG_ 130 SteWhlSwtchDown_B_Stat 1;
BA_ "U_U55X_MY2022_Tx" SG_ 1244 Con_InfotainmentVer_St 1;
BA_ "U_T6_MCA_MY2020_Tx" SG_ 1244 Con_InfotainmentVer_St 1;
BA_ "U_U55X_MY2022_Tx" SG_ 1244 Con_Profiles_St 1;
BA_ "U_T6_MCA_MY2020_Tx" SG_ 1244 Con_Profiles_St 1;
BA_ "U_U55X_MY2022_Tx" SG_ 1244 Con_Configuration 1;
BA_ "U_T6_MCA_MY2020_Tx" SG_ 1244 Con_Configuration 1;
BA_ "U_T6_MCA_MY2020_Tx" SG_ 1243 Con_BTAud_InfotainmVer_St 1;
BA_ "U_T6_MCA_MY2020_Tx" SG_ 1243 Con_BTAud_Profiles_St 1;
BA_ "U_T6_MCA_MY2020_Tx" SG_ 1243 Con_BTAudConfiguration 1;
BA_ "U_T6_MCA_MY2020_Tx" SG_ 681 Con_DB1temIndex_St 1;
BA_ "GenSigSendType" SG_ 681 Con_DB1temIndex_St 1;
BA_ "U_T6_MCA_MY2020_Tx" SG_ 681 Con_DB1FilterConfig_St 1;
BA_ "U_T6_MCA_MY2020_Tx" SG_ 681 Con_DB1Filter3_St 1;
BA_ "U_T6_MCA_MY2020_Tx" SG_ 681 Con_DB1Filter2_St 1;
BA_ "U_T6_MCA_MY2020_Tx" SG_ 681 Con_DB1Filter1_St 1;
BA_ "U_T6_MCA_MY2020_Tx" SG_ 744 Con_USB_ActTrNum1_St 1;
BA_ "U_CD542_MY2021_Rx" SG_ 744 Con_USB_ActTrNum1_St 1;
BA_ "U_T6_MCA_MY2020_Rx" SG_ 744 Con_USB_ActTrNum1_St 1;
BA_ "GenSigSendType" SG_ 744 Con_USB_ActTrNum1_St 3;
BA_ "U_T6_MCA_MY2020_Tx" SG_ 744 Con_iPod_NumberOfTracks 1;
BA_ "U_CD542_MY2021_Rx" SG_ 744 Con_iPod_NumberOfTracks 1;
BA_ "U_T6_MCA_MY2020_Rx" SG_ 744 Con_iPod_NumberOfTracks 1;
BA_ "GenSigSendType" SG_ 744 Con_iPod_NumberOfTracks 3;
BA_ "U_T6_MCA_MY2020_Tx" SG_ 744 Con_USB_NumberOfTracks 1;
BA_ "U_CD542_MY2021_Rx" SG_ 744 Con_USB_NumberOfTracks 1;
BA_ "U_T6_MCA_MY2020_Rx" SG_ 744 Con_USB_NumberOfTracks 1;
BA_ "GenSigSendType" SG_ 744 Con_USB_NumberOfTracks 3;
BA_ "U_T6_MCA_MY2020_Tx" SG_ 741 Con_USB_Playtype_St 1;
BA_ "U_U55X_MY2022_Rx" SG_ 741 Con_USB_Playtype_St 1;
BA_ "U_CD542_MY2021_Rx" SG_ 741 Con_USB_Playtype_St 1;
BA_ "U_T6_MCA_MY2020_Rx" SG_ 741 Con_USB_Playtype_St 1;
BA_ "GenSigSendType" SG_ 741 Con_USB_Playtype_St 3;
BA_ "U_T6_MCA_MY2020_Tx" SG_ 741 Con_ShowSWDLBargr_St 1;
BA_ "U_U55X_MY2022_Rx" SG_ 741 Con_ShowSWDLBargr_St 1;
BA_ "U_CD542_MY2021_Rx" SG_ 741 Con_ShowSWDLBargr_St 1;
BA_ "U_T6_MCA_MY2020_Rx" SG_ 741 Con_ShowSWDLBargr_St 1;
BA_ "U_T6_MCA_MY2020_Tx" SG_ 741 Con_ShowSWDLprogress_St 1;
BA_ "U_U55X_MY2022_Rx" SG_ 741 Con_ShowSWDLprogress_St 1;
BA_ "U_CD542_MY2021_Rx" SG_ 741 Con_ShowSWDLprogress_St 1;
BA_ "U_T6_MCA_MY2020_Rx" SG_ 741 Con_ShowSWDLprogress_St 1;
BA_ "GenSigSendType" SG_ 741 Con_ShowSWDLprogress_St 3;
BA_ "U_T6_MCA_MY2020_Tx" SG_ 741 Con_iPod_IntroScan_St 1;
BA_ "U_U55X_MY2022_Rx" SG_ 741 Con_iPod_IntroScan_St 1;
BA_ "U_CD542_MY2021_Rx" SG_ 741 Con_iPod_IntroScan_St 1;
BA_ "U_T6_MCA_MY2020_Rx" SG_ 741 Con_iPod_IntroScan_St 1;
BA_ "GenSigSendType" SG_ 741 Con_iPod_IntroScan_St 3;
BA_ "U_T6_MCA_MY2020_Tx" SG_ 741 Con_iPod_Shuffle_St 1;
BA_ "U_U55X_MY2022_Rx" SG_ 741 Con_iPod_Shuffle_St 1;
BA_ "U_CD542_MY2021_Rx" SG_ 741 Con_iPod_Shuffle_St 1;
BA_ "U_T6_MCA_MY2020_Rx" SG_ 741 Con_iPod_Shuffle_St 1;
BA_ "GenSigSendType" SG_ 741 Con_iPod_Shuffle_St 3;
BA_ "U_T6_MCA_MY2020_Tx" SG_ 741 Con_iPod_Repeat_St 1;
BA_ "U_U55X_MY2022_Rx" SG_ 741 Con_iPod_Repeat_St 1;
BA_ "U_CD542_MY2021_Rx" SG_ 741 Con_iPod_Repeat_St 1;
BA_ "U_T6_MCA_MY2020_Rx" SG_ 741 Con_iPod_Repeat_St 1;
BA_ "GenSigSendType" SG_ 741 Con_iPod_Repeat_St 3;
BA_ "U_T6_MCA_MY2020_Tx" SG_ 741 Con_USB_Repeat_St 1;
BA_ "U_U55X_MY2022_Rx" SG_ 741 Con_USB_Repeat_St 1;
BA_ "U_CD542_MY2021_Rx" SG_ 741 Con_USB_Repeat_St 1;
BA_ "U_T6_MCA_MY2020_Rx" SG_ 741 Con_USB_Repeat_St 1;
BA_ "GenSigSendType" SG_ 741 Con_USB_Repeat_St 3;
BA_ "U_T6_MCA_MY2020_Tx" SG_ 741 Con_USB_IntroScan_St 1;
BA_ "U_U55X_MY2022_Rx" SG_ 741 Con_USB_IntroScan_St 1;
BA_ "U_CD542_MY2021_Rx" SG_ 741 Con_USB_IntroScan_St 1;
BA_ "U_T6_MCA_MY2020_Rx" SG_ 741 Con_USB_IntroScan_St 1;
BA_ "GenSigSendType" SG_ 741 Con_USB_IntroScan_St 3;
BA_ "U_T6_MCA_MY2020_Tx" SG_ 741 Con_USB_Shuffle_St 1;
BA_ "U_U55X_MY2022_Rx" SG_ 741 Con_USB_Shuffle_St 1;
BA_ "U_CD542_MY2021_Rx" SG_ 741 Con_USB_Shuffle_St 1;
BA_ "U_T6_MCA_MY2020_Rx" SG_ 741 Con_USB_Shuffle_St 1;
BA_ "GenSigSendType" SG_ 741 Con_USB_Shuffle_St 3;
BA_ "U_T6_MCA_MY2020_Tx" SG_ 741 Con_iPod_Error_St 1;
BA_ "U_U55X_MY2022_Rx" SG_ 741 Con_iPod_Error_St 1;
BA_ "U_CD542_MY2021_Rx" SG_ 741 Con_iPod_Error_St 1;
BA_ "U_T6_MCA_MY2020_Rx" SG_ 741 Con_iPod_Error_St 1;
BA_ "GenSigSendType" SG_ 741 Con_iPod_Error_St 3;
BA_ "U_T6_MCA_MY2020_Tx" SG_ 741 Con_USB_Error_St 1;
BA_ "U_U55X_MY2022_Rx" SG_ 741 Con_USB_Error_St 1;
BA_ "U_CD542_MY2021_Rx" SG_ 741 Con_USB_Error_St 1;
BA_ "U_T6_MCA_MY2020_Rx" SG_ 741 Con_USB_Error_St 1;
BA_ "GenSigSendType" SG_ 741 Con_USB_Error_St 3;
BA_ "U_T6_MCA_MY2020_Tx" SG_ 741 Con_iPod_FunctStatus_St 1;
BA_ "U_U55X_MY2022_Rx" SG_ 741 Con_iPod_FunctStatus_St 1;
BA_ "U_CD542_MY2021_Rx" SG_ 741 Con_iPod_FunctStatus_St 1;
BA_ "U_T6_MCA_MY2020_Rx" SG_ 741 Con_iPod_FunctStatus_St 1;
BA_ "GenSigSendType" SG_ 741 Con_iPod_FunctStatus_St 3;
BA_ "U_T6_MCA_MY2020_Tx" SG_ 741 Con_USB_FunctStatus_St 1;
BA_ "U_U55X_MY2022_Rx" SG_ 741 Con_USB_FunctStatus_St 1;
BA_ "U_CD542_MY2021_Rx" SG_ 741 Con_USB_FunctStatus_St 1;
BA_ "U_T6_MCA_MY2020_Rx" SG_ 741 Con_USB_FunctStatus_St 1;
BA_ "GenSigSendType" SG_ 741 Con_USB_FunctStatus_St 3;
BA_ "U_T6_MCA_MY2020_Tx" SG_ 741 Con_USB_OpMode_St 1;
BA_ "U_U55X_MY2022_Rx" SG_ 741 Con_USB_OpMode_St 1;
BA_ "U_CD542_MY2021_Rx" SG_ 741 Con_USB_OpMode_St 1;
BA_ "U_T6_MCA_MY2020_Rx" SG_ 741 Con_USB_OpMode_St 1;
BA_ "GenSigSendType" SG_ 741 Con_USB_OpMode_St 3;
BA_ "U_T6_MCA_MY2020_Tx" SG_ 741 Con_iPod_OpMode_St 1;
BA_ "U_U55X_MY2022_Rx" SG_ 741 Con_iPod_OpMode_St 1;
BA_ "U_CD542_MY2021_Rx" SG_ 741 Con_iPod_OpMode_St 1;
BA_ "U_T6_MCA_MY2020_Rx" SG_ 741 Con_iPod_OpMode_St 1;
BA_ "GenSigSendType" SG_ 741 Con_iPod_OpMode_St 3;
BA_ "GenSigStartValue" SG_ 954 ExtLghtFront_D_RqBody 1;
BA_ "WakeupSignal" SG_ 954 ExtLghtFront_D_RqBody 1;
BA_ "U_U55X_MY2022_Rx" SG_ 954 CargoLght_D_Stat 1;
BA_ "U_T6_MCA_MY2020_Rx" SG_ 954 CargoLght_D_Stat 1;
BA_ "U_U55X_MY2022_Rx" SG_ 954 TlghtTestLght_D_Stat 1;
BA_ "U_CD542_MY2021_Rx" SG_ 954 TlghtTestLght_D_Stat 1;
BA_ "U_T6_MCA_MY2020_Rx" SG_ 954 TlghtTestLght_D_Stat 1;
BA_ "U_U55X_MY2022_Rx" SG_ 954 LghtAmbDrvMde_B_Stat 1;
BA_ "WakeupSignal" SG_ 954 LghtAmbDrvMde_B_Stat 1;
BA_ "U_U55X_MY2022_Rx" SG_ 954 KeylessIdl_B_Stat 1;
BA_ "U_CD542_MY2021_Rx" SG_ 954 KeylessIdl_B_Stat 1;
BA_ "U_T6_MCA_MY2020_Rx" SG_ 954 KeylessIdl_B_Stat 1;
BA_ "WakeupSignal" SG_ 954 PwRnngBoardPoll_D_Stat 1;
BA_ "U_U55X_MY2022_Rx" SG_ 954 PoliceDmngLvl_D_Stat 1;
BA_ "U_CD542_MY2021_Rx" SG_ 954 PoliceDmngLvl_D_Stat 1;
BA_ "U_T6_MCA_MY2020_Rx" SG_ 954 PoliceDmngLvl_D_Stat 1;
BA_ "U_U55X_MY2022_Rx" SG_ 954 TrlrHitchLamp_D_Stat 1;
BA_ "U_CD542_MY2021_Rx" SG_ 954 TrlrHitchLamp_D_Stat 1;
BA_ "U_T6_MCA_MY2020_Rx" SG_ 954 TrlrHitchLamp_D_Stat 1;
BA_ "WakeupSignal" SG_ 954 TrlrHitchLamp_D_Stat 1;
BA_ "U_U55X_MY2022_Rx" SG_ 954 LicPlateLght_B_Stat 1;
BA_ "U_CD542_MY2021_Rx" SG_ 954 LicPlateLght_B_Stat 1;
BA_ "U_T6_MCA_MY2020_Rx" SG_ 954 LicPlateLght_B_Stat 1;
BA_ "U_U55X_MY2022_Rx" SG_ 954 TrukBedLght_B_Stat 1;
BA_ "U_CD542_MY2021_Rx" SG_ 954 TrukBedLght_B_Stat 1;
BA_ "U_T6_MCA_MY2020_Rx" SG_ 954 TrukBedLght_B_Stat 1;
BA_ "WakeupSignal" SG_ 954 TrukBedLght_B_Stat 1;
BA_ "U_U55X_MY2022_Rx" SG_ 954 VehWlcmFrwlMde_D_Stat 1;
BA_ "U_CD542_MY2021_Rx" SG_ 954 VehWlcmFrwlMde_D_Stat 1;
BA_ "U_T6_MCA_MY2020_Rx" SG_ 954 VehWlcmFrwlMde_D_Stat 1;
BA_ "WakeupSignal" SG_ 954 VehWlcmFrwlMde_D_Stat 1;
BA_ "ContentDependant" SG_ 954 GenericSwtch2_No_Actl 1;
BA_ "WakeupSignal" SG_ 954 PudSptLghtRight_D_Rq 1;
BA_ "WakeupSignal" SG_ 954 PudSptLghtLeft_D_Rq 1;
BA_ "U_U55X_MY2022_Rx" SG_ 954 ExtLghtRight_D_Stat 1;
BA_ "U_CD542_MY2021_Rx" SG_ 954 ExtLghtRight_D_Stat 1;
BA_ "U_T6_MCA_MY2020_Rx" SG_ 954 ExtLghtRight_D_Stat 1;
BA_ "WakeupSignal" SG_ 954 ExtLghtRight_D_Stat 1;
BA_ "U_CD764_MY2022_Rx" SG_ 954 VehWlcmFrwl_D_Stat 1;
BA_ "U_U55X_MY2022_Rx" SG_ 954 VehWlcmFrwl_D_Stat 1;
BA_ "U_CD542_MY2021_Rx" SG_ 954 VehWlcmFrwl_D_Stat 1;
BA_ "U_T6_MCA_MY2020_Rx" SG_ 954 VehWlcmFrwl_D_Stat 1;
BA_ "WakeupSignal" SG_ 954 VehWlcmFrwl_D_Stat 1;
BA_ "U_U55X_MY2022_Rx" SG_ 954 ExtLghtRear_D_Stat 1;
BA_ "U_CD542_MY2021_Rx" SG_ 954 ExtLghtRear_D_Stat 1;
BA_ "U_T6_MCA_MY2020_Rx" SG_ 954 ExtLghtRear_D_Stat 1;
BA_ "WakeupSignal" SG_ 954 ExtLghtRear_D_Stat 1;
BA_ "U_U55X_MY2022_Rx" SG_ 954 ExtLghtLeft_D_Stat 1;
BA_ "U_CD542_MY2021_Rx" SG_ 954 ExtLghtLeft_D_Stat 1;
BA_ "U_T6_MCA_MY2020_Rx" SG_ 954 ExtLghtLeft_D_Stat 1;
BA_ "WakeupSignal" SG_ 954 ExtLghtLeft_D_Stat 1;
BA_ "U_U55X_MY2022_Rx" SG_ 954 ExtLghtAlrt_B_Rq 1;
BA_ "U_CD542_MY2021_Rx" SG_ 954 ExtLghtAlrt_B_Rq 1;
BA_ "U_T6_MCA_MY2020_Rx" SG_ 954 ExtLghtAlrt_B_Rq 1;
BA_ "WakeupSignal" SG_ 954 ExtLghtAlrt_B_Rq 1;
BA_ "U_U55X_MY2022_Rx" SG_ 954 ExtLght_D_Falt 1;
BA_ "U_CD542_MY2021_Rx" SG_ 954 ExtLght_D_Falt 1;
BA_ "U_T6_MCA_MY2020_Rx" SG_ 954 ExtLght_D_Falt 1;
BA_ "WakeupSignal" SG_ 954 ExtLght_D_Falt 1;
BA_ "U_U55X_MY2022_Rx" SG_ 954 ExtLghtFront_D_Stat 1;
BA_ "U_CD542_MY2021_Rx" SG_ 954 ExtLghtFront_D_Stat 1;
BA_ "U_T6_MCA_MY2020_Rx" SG_ 954 ExtLghtFront_D_Stat 1;
BA_ "WakeupSignal" SG_ 954 ExtLghtFront_D_Stat 1;
BA_ "U_U55X_MY2022_Rx" SG_ 954 TlghtTestPrecnd_D_Stat 1;
BA_ "U_CD542_MY2021_Rx" SG_ 954 TlghtTestPrecnd_D_Stat 1;
BA_ "U_T6_MCA_MY2020_Rx" SG_ 954 TlghtTestPrecnd_D_Stat 1;
BA_ "U_U55X_MY2022_Rx" SG_ 954 TlghtTest_D_Stat 1;
BA_ "U_CD542_MY2021_Rx" SG_ 954 TlghtTest_D_Stat 1;
BA_ "U_T6_MCA_MY2020_Rx" SG_ 954 TlghtTest_D_Stat 1;
BA_ "U_U55X_MY2022_Rx" SG_ 125 VehRolComp_W_Actl 1;
BA_ "U_CD542_MY2021_Rx" SG_ 125 VehRolComp_W_Actl 1;
BA_ "U_T6_MCA_MY2020_Rx" SG_ 125 VehRolComp_W_Actl 1;
BA_ "U_P702_MY2021_Rx" SG_ 125 VehRolComp_W_Actl 1;
BA_ "GenSigStartValue" SG_ 125 VehRolComp_W_Actl 4094;
BA_ "GenSigStartValueInteger" SG_ 125 VehRolComp_W_Actl 4094;
BA_ "U_U55X_MY2022_Rx" SG_ 125 VehVertComp_A_Actl 1;
BA_ "U_CD542_MY2021_Rx" SG_ 125 VehVertComp_A_Actl 1;
BA_ "U_T6_MCA_MY2020_Rx" SG_ 125 VehVertComp_A_Actl 1;
BA_ "U_P702_MY2021_Rx" SG_ 125 VehVertComp_A_Actl 1;
BA_ "GenSigStartValue" SG_ 125 VehVertComp_A_Actl 1022;
BA_ "GenSigStartValueInteger" SG_ 125 VehVertComp_A_Actl 1022;
BA_ "U_U55X_MY2022_Rx" SG_ 125 BrkTotTqRqArb_No_Cs 1;
BA_ "U_T6_MCA_MY2020_Rx" SG_ 125 BrkTotTqRqArb_No_Cs 1;
BA_ "U_P702_MY2021_Rx" SG_ 125 BrkTotTqRqArb_No_Cs 1;
BA_ "MetaData" SG_ 125 BrkTotTqRqArb_No_Cs 1;
BA_ "U_U55X_MY2022_Rx" SG_ 125 BrkTotTqRqArb_No_Cnt 1;
BA_ "U_T6_MCA_MY2020_Rx" SG_ 125 BrkTotTqRqArb_No_Cnt 1;
BA_ "U_P702_MY2021_Rx" SG_ 125 BrkTotTqRqArb_No_Cnt 1;
BA_ "MetaData" SG_ 125 BrkTotTqRqArb_No_Cnt 1;
BA_ "U_CD542_MY2021_Rx" SG_ 125 BrkTot_Tq_RqArb 1;
BA_ "U_U55X_MY2022_Rx" SG_ 125 BrkTot_Tq_RqArb 1;
BA_ "U_T6_MCA_MY2020_Rx" SG_ 125 BrkTot_Tq_RqArb 1;
BA_ "U_P702_MY2021_Rx" SG_ 125 BrkTot_Tq_RqArb 1;
BA_ "U_CD542_MY2021_Rx" SG_ 125 BrkTot_Tq_Actl 1;
BA_ "U_P702_MY2021_Rx" SG_ 125 BrkTot_Tq_Actl 1;
BA_ "U_CD764_MY2022_Rx" SG_ 125 BrkTot_Tq_Actl 1;
BA_ "U_U55X_MY2022_Rx" SG_ 125 BrkTot_Tq_Actl 1;
BA_ "U_T6_MCA_MY2020_Rx" SG_ 125 BrkTot_Tq_Actl 1;
BA_ "U_CD764_MY2022_Rx" SG_ 125 HsaStat_D_Actl 1;
BA_ "U_CD542_MY2021_Rx" SG_ 125 HsaStat_D_Actl 1;
BA_ "U_T6_MCA_MY2020_Rx" SG_ 125 HsaStat_D_Actl 1;
BA_ "U_P702_MY2021_Rx" SG_ 125 HsaStat_D_Actl 1;
BA_ "U_CD764_MY2022_Tx" SG_ 2612224096 PARSEDPushIPCtoGWM_ECG 1;
BA_ "U_U55X_MY2022_Tx" SG_ 2612224096 PARSEDPushIPCtoGWM_ECG 1;
BA_ "U_CD542_MY2021_Tx" SG_ 2612224096 PARSEDPushIPCtoGWM_ECG 1;
BA_ "U_T6_MCA_MY2020_Tx" SG_ 2612224096 PARSEDPushIPCtoGWM_ECG 1;
BA_ "U_P702_MY2021_Tx" SG_ 2612224096 PARSEDPushIPCtoGWM_ECG 1;
BA_ "U_CD764_MY2022_Rx" SG_ 2612224096 PARSEDPushIPCtoGWM_ECG 1;
BA_ "U_U55X_MY2022_Rx" SG_ 2612224096 PARSEDPushIPCtoGWM_ECG 1;
BA_ "U_CD542_MY2021_Rx" SG_ 2612224096 PARSEDPushIPCtoGWM_ECG 1;
BA_ "ECGUsedRxSignal" SG_ 2612224096 PARSEDPushIPCtoGWM_ECG 1;
BA_ "U_T6_MCA_MY2020_Rx" SG_ 2612224096 PARSEDPushIPCtoGWM_ECG 1;
BA_ "GenSigSendType" SG_ 2612224096 PARSEDPushIPCtoGWM_ECG 3;
BA_ "U_CD764_MY2022_Tx" SG_ 2611052760 PARSEDPhysGWM_ECGtoIPC 1;
BA_ "U_U55X_MY2022_Tx" SG_ 2611052760 PARSEDPhysGWM_ECGtoIPC 1;
BA_ "U_CD542_MY2021_Tx" SG_ 2611052760 PARSEDPhysGWM_ECGtoIPC 1;
BA_ "ECGUsedTxSignal" SG_ 2611052760 PARSEDPhysGWM_ECGtoIPC 1;
BA_ "U_T6_MCA_MY2020_Tx" SG_ 2611052760 PARSEDPhysGWM_ECGtoIPC 1;
BA_ "U_CD764_MY2022_Rx" SG_ 2611052760 PARSEDPhysGWM_ECGtoIPC 1;
BA_ "U_U55X_MY2022_Rx" SG_ 2611052760 PARSEDPhysGWM_ECGtoIPC 1;
BA_ "U_CD542_MY2021_Rx" SG_ 2611052760 PARSEDPhysGWM_ECGtoIPC 1;
BA_ "U_T6_MCA_MY2020_Rx" SG_ 2611052760 PARSEDPhysGWM_ECGtoIPC 1;
BA_ "U_P702_MY2021_Rx" SG_ 2611052760 PARSEDPhysGWM_ECGtoIPC 1;
BA_ "GenSigSendType" SG_ 2611052760 PARSEDPhysGWM_ECGtoIPC 3;
BA_ "U_CD764_MY2022_Tx" SG_ 2611175520 PARSEDPhysIPCtoGWM_ECG 1;
BA_ "U_U55X_MY2022_Tx" SG_ 2611175520 PARSEDPhysIPCtoGWM_ECG 1;
BA_ "U_CD542_MY2021_Tx" SG_ 2611175520 PARSEDPhysIPCtoGWM_ECG 1;
BA_ "U_T6_MCA_MY2020_Tx" SG_ 2611175520 PARSEDPhysIPCtoGWM_ECG 1;
BA_ "U_P702_MY2021_Tx" SG_ 2611175520 PARSEDPhysIPCtoGWM_ECG 1;
BA_ "U_CD764_MY2022_Rx" SG_ 2611175520 PARSEDPhysIPCtoGWM_ECG 1;
BA_ "U_U55X_MY2022_Rx" SG_ 2611175520 PARSEDPhysIPCtoGWM_ECG 1;
BA_ "U_CD542_MY2021_Rx" SG_ 2611175520 PARSEDPhysIPCtoGWM_ECG 1;
BA_ "ECGUsedRxSignal" SG_ 2611175520 PARSEDPhysIPCtoGWM_ECG 1;
BA_ "U_T6_MCA_MY2020_Rx" SG_ 2611175520 PARSEDPhysIPCtoGWM_ECG 1;
BA_ "GenSigSendType" SG_ 2611175520 PARSEDPhysIPCtoGWM_ECG 3;
BA_ "U_CD764_MY2022_Tx" SG_ 2610126944 OTAPhysIPCtoGWM_ECG 1;
BA_ "U_U55X_MY2022_Tx" SG_ 2610126944 OTAPhysIPCtoGWM_ECG 1;
BA_ "U_CD542_MY2021_Tx" SG_ 2610126944 OTAPhysIPCtoGWM_ECG 1;
BA_ "U_T6_MCA_MY2020_Tx" SG_ 2610126944 OTAPhysIPCtoGWM_ECG 1;
BA_ "U_P702_MY2021_Tx" SG_ 2610126944 OTAPhysIPCtoGWM_ECG 1;
BA_ "U_CD764_MY2022_Rx" SG_ 2610126944 OTAPhysIPCtoGWM_ECG 1;
BA_ "U_U55X_MY2022_Rx" SG_ 2610126944 OTAPhysIPCtoGWM_ECG 1;
BA_ "U_CD542_MY2021_Rx" SG_ 2610126944 OTAPhysIPCtoGWM_ECG 1;
BA_ "ECGUsedRxSignal" SG_ 2610126944 OTAPhysIPCtoGWM_ECG 1;
BA_ "U_T6_MCA_MY2020_Rx" SG_ 2610126944 OTAPhysIPCtoGWM_ECG 1;
BA_ "GenSigSendType" SG_ 2610126944 OTAPhysIPCtoGWM_ECG 3;
BA_ "U_CD764_MY2022_Tx" SG_ 2610004184 OTAPhysGWM_ECGtoIPC 1;
BA_ "U_U55X_MY2022_Tx" SG_ 2610004184 OTAPhysGWM_ECGtoIPC 1;
BA_ "U_CD542_MY2021_Tx" SG_ 2610004184 OTAPhysGWM_ECGtoIPC 1;
BA_ "ECGUsedTxSignal" SG_ 2610004184 OTAPhysGWM_ECGtoIPC 1;
BA_ "U_T6_MCA_MY2020_Tx" SG_ 2610004184 OTAPhysGWM_ECGtoIPC 1;
BA_ "U_CD764_MY2022_Rx" SG_ 2610004184 OTAPhysGWM_ECGtoIPC 1;
BA_ "U_U55X_MY2022_Rx" SG_ 2610004184 OTAPhysGWM_ECGtoIPC 1;
BA_ "U_CD542_MY2021_Rx" SG_ 2610004184 OTAPhysGWM_ECGtoIPC 1;
BA_ "U_T6_MCA_MY2020_Rx" SG_ 2610004184 OTAPhysGWM_ECGtoIPC 1;
BA_ "U_P702_MY2021_Rx" SG_ 2610004184 OTAPhysGWM_ECGtoIPC 1;
BA_ "GenSigSendType" SG_ 2610004184 OTAPhysGWM_ECGtoIPC 3;
BA_ "GenSigSendType" SG_ 2005 TesterPhysicalReqDACMC 3;
BA_ "GenSigSendType" SG_ 2013 TesterPhysicalResDACMC 3;
BA_ "U_CD764_MY2022_Rx" SG_ 1519 DACMC_GWOnBoardTester 1;
BA_ "U_U55X_MY2022_Rx" SG_ 1519 DACMC_GWOnBoardTester 1;
BA_ "GenSigStartValue" SG_ 1519 DACMC_GWOnBoardTester 255;
BA_ "ContentDependant" SG_ 1519 DACMC_GWOnBoardTester 1;
BA_ "GenSigStartValueInteger" SG_ 1519 DACMC_GWOnBoardTester 255;
BA_ "U_CD764_MY2022_Rx" SG_ 1519 DACMC_GWNMProxy 1;
BA_ "U_U55X_MY2022_Rx" SG_ 1519 DACMC_GWNMProxy 1;
BA_ "GenSigStartValue" SG_ 1519 DACMC_GWNMProxy 255;
BA_ "ContentDependant" SG_ 1519 DACMC_GWNMProxy 1;
BA_ "GenSigStartValueInteger" SG_ 1519 DACMC_GWNMProxy 255;
BA_ "U_CD764_MY2022_Rx" SG_ 1519 DACMC_AutoSarNMReserved4 1;
BA_ "U_U55X_MY2022_Rx" SG_ 1519 DACMC_AutoSarNMReserved4 1;
BA_ "GenSigStartValue" SG_ 1519 DACMC_AutoSarNMReserved4 255;
BA_ "ContentDependant" SG_ 1519 DACMC_AutoSarNMReserved4 1;
BA_ "GenSigStartValueInteger" SG_ 1519 DACMC_AutoSarNMReserved4 255;
BA_ "U_CD764_MY2022_Rx" SG_ 1519 DACMC_AutoSarNMReserved3 1;
BA_ "U_U55X_MY2022_Rx" SG_ 1519 DACMC_AutoSarNMReserved3 1;
BA_ "GenSigStartValue" SG_ 1519 DACMC_AutoSarNMReserved3 255;
BA_ "ContentDependant" SG_ 1519 DACMC_AutoSarNMReserved3 1;
BA_ "GenSigStartValueInteger" SG_ 1519 DACMC_AutoSarNMReserved3 255;
BA_ "U_CD764_MY2022_Rx" SG_ 1519 DACMC_AutoSarNMReserved2 1;
BA_ "U_U55X_MY2022_Rx" SG_ 1519 DACMC_AutoSarNMReserved2 1;
BA_ "GenSigStartValue" SG_ 1519 DACMC_AutoSarNMReserved2 255;
BA_ "ContentDependant" SG_ 1519 DACMC_AutoSarNMReserved2 1;
BA_ "GenSigStartValueInteger" SG_ 1519 DACMC_AutoSarNMReserved2 255;
BA_ "U_CD764_MY2022_Rx" SG_ 1519 DACMC_AutoSarNMReserved1 1;
BA_ "U_U55X_MY2022_Rx" SG_ 1519 DACMC_AutoSarNMReserved1 1;
BA_ "GenSigStartValue" SG_ 1519 DACMC_AutoSarNMReserved1 255;
BA_ "ContentDependant" SG_ 1519 DACMC_AutoSarNMReserved1 1;
BA_ "GenSigStartValueInteger" SG_ 1519 DACMC_AutoSarNMReserved1 255;
BA_ "U_CD764_MY2022_Rx" SG_ 1519 DACMC_AutoSarNMNodeId 1;
BA_ "U_U55X_MY2022_Rx" SG_ 1519 DACMC_AutoSarNMNodeId 1;
BA_ "GenSigStartValue" SG_ 1519 DACMC_AutoSarNMNodeId 239;
BA_ "ContentDependant" SG_ 1519 DACMC_AutoSarNMNodeId 1;
BA_ "GenSigStartValueInteger" SG_ 1519 DACMC_AutoSarNMNodeId 150;
BA_ "U_CD764_MY2022_Rx" SG_ 1519 DACMC_AutoSarNMControl 1;
BA_ "U_U55X_MY2022_Rx" SG_ 1519 DACMC_AutoSarNMControl 1;
BA_ "ContentDependant" SG_ 1519 DACMC_AutoSarNMControl 1;
BA_ "U_CD764_MY2022_Tx" SG_ 2612002008 PARSEDFuncGWM_ECG 1;
BA_ "U_U55X_MY2022_Tx" SG_ 2612002008 PARSEDFuncGWM_ECG 1;
BA_ "U_CD542_MY2021_Tx" SG_ 2612002008 PARSEDFuncGWM_ECG 1;
BA_ "ECGUsedTxSignal" SG_ 2612002008 PARSEDFuncGWM_ECG 1;
BA_ "U_T6_MCA_MY2020_Tx" SG_ 2612002008 PARSEDFuncGWM_ECG 1;
BA_ "U_CD764_MY2022_Rx" SG_ 2612002008 PARSEDFuncGWM_ECG 1;
BA_ "U_U55X_MY2022_Rx" SG_ 2612002008 PARSEDFuncGWM_ECG 1;
BA_ "U_CD542_MY2021_Rx" SG_ 2612002008 PARSEDFuncGWM_ECG 1;
BA_ "U_T6_MCA_MY2020_Rx" SG_ 2612002008 PARSEDFuncGWM_ECG 1;
BA_ "U_P702_MY2021_Rx" SG_ 2612002008 PARSEDFuncGWM_ECG 1;
BA_ "GenSigSendType" SG_ 2612002008 PARSEDFuncGWM_ECG 3;
BA_ "U_CD764_MY2022_Tx" SG_ 2610953432 OTAFuncGWM_ECG 1;
BA_ "U_U55X_MY2022_Tx" SG_ 2610953432 OTAFuncGWM_ECG 1;
BA_ "U_CD542_MY2021_Tx" SG_ 2610953432 OTAFuncGWM_ECG 1;
BA_ "ECGUsedTxSignal" SG_ 2610953432 OTAFuncGWM_ECG 1;
BA_ "U_T6_MCA_MY2020_Tx" SG_ 2610953432 OTAFuncGWM_ECG 1;
BA_ "U_CD764_MY2022_Rx" SG_ 2610953432 OTAFuncGWM_ECG 1;
BA_ "U_U55X_MY2022_Rx" SG_ 2610953432 OTAFuncGWM_ECG 1;
BA_ "U_CD542_MY2021_Rx" SG_ 2610953432 OTAFuncGWM_ECG 1;
BA_ "U_T6_MCA_MY2020_Rx" SG_ 2610953432 OTAFuncGWM_ECG 1;
BA_ "U_P702_MY2021_Rx" SG_ 2610953432 OTAFuncGWM_ECG 1;
BA_ "GenSigSendType" SG_ 2610953432 OTAFuncGWM_ECG 3;
BA_ "U_CD764_MY2022_Rx" SG_ 1082 PwTgateInhbtMsgTxt_B_Rq_UB 1;
BA_ "U_CD764_MY2022_Rx" SG_ 1082 PwTgateInhbtMsgTxt_B_Rq 1;
BA_ "GenSigSendType" SG_ 1082 PwTgateInhbtMsgTxt_B_Rq 3;
BA_ "U_CD764_MY2022_Rx" SG_ 1082 SldrrStat_B_Actl_UB 1;
BA_ "U_CD764_MY2022_Rx" SG_ 1082 SldrrStat_B_Actl 1;
BA_ "GenSigSendType" SG_ 1082 SldrrStat_B_Actl 3;
BA_ "U_CD764_MY2022_Rx" SG_ 1082 SldrlStat_B_Actl_UB 1;
BA_ "U_CD764_MY2022_Rx" SG_ 1082 SldrlStat_B_Actl 1;
BA_ "GenSigSendType" SG_ 1082 SldrlStat_B_Actl 3;
BA_ "U_CD764_MY2022_Rx" SG_ 1082 StabBarFaltMsgTxt_D_Rq_UB 1;
BA_ "U_T6_MCA_MY2020_Rx" SG_ 1082 StabBarFaltMsgTxt_D_Rq_UB 1;
BA_ "U_U55X_MY2022_Rx" SG_ 1082 StabBarCnnctLamp_D_Rq_UB 1;
BA_ "U_CD764_MY2022_Rx" SG_ 1082 StabBarCnnctLamp_D_Rq_UB 1;
BA_ "U_T6_MCA_MY2020_Rx" SG_ 1082 StabBarCnnctLamp_D_Rq_UB 1;
BA_ "U_CD764_MY2022_Rx" SG_ 1082 StabBarCnncMsgTxt_D_Rq_UB 1;
BA_ "U_T6_MCA_MY2020_Rx" SG_ 1082 StabBarCnncMsgTxt_D_Rq_UB 1;
BA_ "U_CD764_MY2022_Rx" SG_ 1082 StabBarFaltMsgTxt_D_Rq 1;
BA_ "U_T6_MCA_MY2020_Rx" SG_ 1082 StabBarFaltMsgTxt_D_Rq 1;
BA_ "GenSigSendType" SG_ 1082 StabBarFaltMsgTxt_D_Rq 3;
BA_ "U_U55X_MY2022_Rx" SG_ 1082 StabBarCnnctLamp_D_Rq 1;
BA_ "U_CD764_MY2022_Rx" SG_ 1082 StabBarCnnctLamp_D_Rq 1;
BA_ "U_T6_MCA_MY2020_Rx" SG_ 1082 StabBarCnnctLamp_D_Rq 1;
BA_ "GenSigSendType" SG_ 1082 StabBarCnnctLamp_D_Rq 3;
BA_ "U_CD764_MY2022_Rx" SG_ 1082 StabBarCnncMsgTxt_D_Rq 1;
BA_ "U_T6_MCA_MY2020_Rx" SG_ 1082 StabBarCnncMsgTxt_D_Rq 1;
BA_ "GenSigSendType" SG_ 1082 StabBarCnncMsgTxt_D_Rq 3;
BA_ "U_U55X_MY2022_Tx" SG_ 576 AUDIO_RDISP2_WORD_Tx 1;
BA_ "U_T6_MCA_MY2020_Tx" SG_ 576 AUDIO_RDISP2_WORD_Tx 1;
BA_ "U_CD764_MY2022_Rx" SG_ 576 AUDIO_RDISP2_WORD_Tx 1;
BA_ "U_U55X_MY2022_Rx" SG_ 576 AUDIO_RDISP2_WORD_Tx 1;
BA_ "U_T6_MCA_MY2020_Rx" SG_ 576 AUDIO_RDISP2_WORD_Tx 1;
BA_ "U_CD764_MY2022_Tx" SG_ 1115 HUD_TextMessage_Rq 1;
BA_ "U_U55X_MY2022_Tx" SG_ 1115 HUD_TextMessage_Rq 1;
BA_ "U_T6_MCA_MY2020_Tx" SG_ 1115 HUD_TextMessage_Rq 1;
BA_ "U_U55X_MY2022_Rx" SG_ 1115 HUD_TextMessage_Rq 1;
BA_ "U_CD542_MY2021_Rx" SG_ 1115 HUD_TextMessage_Rq 1;
BA_ "GenSigSendType" SG_ 1115 HUD_TextMessage_Rq 3;
BA_ "U_CD764_MY2022_Tx" SG_ 1115 HUD_BTIncomingCall_Rq 1;
BA_ "U_U55X_MY2022_Tx" SG_ 1115 HUD_BTIncomingCall_Rq 1;
BA_ "U_T6_MCA_MY2020_Tx" SG_ 1115 HUD_BTIncomingCall_Rq 1;
BA_ "U_U55X_MY2022_Rx" SG_ 1115 HUD_BTIncomingCall_Rq 1;
BA_ "U_CD542_MY2021_Rx" SG_ 1115 HUD_BTIncomingCall_Rq 1;
BA_ "GenSigSendType" SG_ 1115 HUD_BTIncomingCall_Rq 3;
BA_ "U_CD764_MY2022_Tx" SG_ 1115 HUD_BTInCallOptions_Rq 1;
BA_ "U_U55X_MY2022_Tx" SG_ 1115 HUD_BTInCallOptions_Rq 1;
BA_ "U_T6_MCA_MY2020_Tx" SG_ 1115 HUD_BTInCallOptions_Rq 1;
BA_ "U_U55X_MY2022_Rx" SG_ 1115 HUD_BTInCallOptions_Rq 1;
BA_ "U_CD542_MY2021_Rx" SG_ 1115 HUD_BTInCallOptions_Rq 1;
BA_ "GenSigSendType" SG_ 1115 HUD_BTInCallOptions_Rq 3;
BA_ "U_CD764_MY2022_Tx" SG_ 1115 HUD_BTEndTelService_Rq 1;
BA_ "U_U55X_MY2022_Tx" SG_ 1115 HUD_BTEndTelService_Rq 1;
BA_ "U_T6_MCA_MY2020_Tx" SG_ 1115 HUD_BTEndTelService_Rq 1;
BA_ "U_U55X_MY2022_Rx" SG_ 1115 HUD_BTEndTelService_Rq 1;
BA_ "U_CD542_MY2021_Rx" SG_ 1115 HUD_BTEndTelService_Rq 1;
BA_ "GenSigSendType" SG_ 1115 HUD_BTEndTelService_Rq 3;
BA_ "U_CD764_MY2022_Tx" SG_ 996 PersIndexHud_D_Actl 1;
BA_ "U_U55X_MY2022_Tx" SG_ 996 PersIndexHud_D_Actl 1;
BA_ "U_T6_MCA_MY2020_Tx" SG_ 996 PersIndexHud_D_Actl 1;
BA_ "U_U55X_MY2022_Rx" SG_ 996 PersIndexHud_D_Actl 1;
BA_ "U_T6_MCA_MY2020_Rx" SG_ 996 PersIndexHud_D_Actl 1;
BA_ "GenSigSendType" SG_ 996 PersIndexHud_D_Actl 3;
BA_ "U_CD764_MY2022_Tx" SG_ 996 FeatNoHudActl 1;
BA_ "U_U55X_MY2022_Tx" SG_ 996 FeatNoHudActl 1;
BA_ "U_T6_MCA_MY2020_Tx" SG_ 996 FeatNoHudActl 1;
BA_ "U_U55X_MY2022_Rx" SG_ 996 FeatNoHudActl 1;
BA_ "U_T6_MCA_MY2020_Rx" SG_ 996 FeatNoHudActl 1;
BA_ "GenSigSendType" SG_ 996 FeatNoHudActl 3;
BA_ "U_CD764_MY2022_Tx" SG_ 996 FeatConfigHudActl 1;
BA_ "U_U55X_MY2022_Tx" SG_ 996 FeatConfigHudActl 1;
BA_ "U_T6_MCA_MY2020_Tx" SG_ 996 FeatConfigHudActl 1;
BA_ "U_U55X_MY2022_Rx" SG_ 996 FeatConfigHudActl 1;
BA_ "U_T6_MCA_MY2020_Rx" SG_ 996 FeatConfigHudActl 1;
BA_ "GenSigSendType" SG_ 996 FeatConfigHudActl 3;
BA_ "U_CD764_MY2022_Tx" SG_ 588 RDRV_RDISP2_WORD_Rx 1;
BA_ "U_U55X_MY2022_Tx" SG_ 588 RDRV_RDISP2_WORD_Rx 1;
BA_ "U_T6_MCA_MY2020_Tx" SG_ 588 RDRV_RDISP2_WORD_Rx 1;
BA_ "U_U55X_MY2022_Tx" SG_ 811 ExtLghtDsply_D_Stat 1;
BA_ "U_CD542_MY2021_Tx" SG_ 811 ExtLghtDsply_D_Stat 1;
BA_ "U_T6_MCA_MY2020_Tx" SG_ 811 ExtLghtDsply_D_Stat 1;
BA_ "U_CD764_MY2022_Rx" SG_ 811 ExtLghtDsply_D_Stat 1;
BA_ "U_U55X_MY2022_Rx" SG_ 811 ExtLghtDsply_D_Stat 1;
BA_ "U_CD542_MY2021_Rx" SG_ 811 ExtLghtDsply_D_Stat 1;
BA_ "ECGUsedRxSignal" SG_ 811 ExtLghtDsply_D_Stat 1;
BA_ "U_T6_MCA_MY2020_Rx" SG_ 811 ExtLghtDsply_D_Stat 1;
BA_ "GenSigSendType" SG_ 811 ExtLghtDsply_D_Stat 3;
BA_ "U_CD764_MY2022_Tx" SG_ 811 SpeedoMajorUnit_D_Confg 1;
BA_ "U_U55X_MY2022_Tx" SG_ 811 SpeedoMajorUnit_D_Confg 1;
BA_ "U_CD542_MY2021_Tx" SG_ 811 SpeedoMajorUnit_D_Confg 1;
BA_ "U_T6_MCA_MY2020_Tx" SG_ 811 SpeedoMajorUnit_D_Confg 1;
BA_ "GenSigSendType" SG_ 811 SpeedoMajorUnit_D_Confg 3;
BA_ "U_U55X_MY2022_Tx" SG_ 811 ScMnSoc_Pc_RqMnu 1;
BA_ "U_CD542_MY2021_Tx" SG_ 811 ScMnSoc_Pc_RqMnu 1;
BA_ "U_T6_MCA_MY2020_Tx" SG_ 811 ScMnSoc_Pc_RqMnu 1;
BA_ "GenSigStartValue" SG_ 811 ScMnSoc_Pc_RqMnu 126;
BA_ "U_U55X_MY2022_Tx" SG_ 811 ScEnbl_D_RqMnu 1;
BA_ "U_CD542_MY2021_Tx" SG_ 811 ScEnbl_D_RqMnu 1;
BA_ "U_T6_MCA_MY2020_Tx" SG_ 811 ScEnbl_D_RqMnu 1;
BA_ "GenSigSendType" SG_ 811 ScEnbl_D_RqMnu 3;
BA_ "U_U55X_MY2022_Tx" SG_ 811 OnePdlDrvButtn_B_Falt 1;
BA_ "U_CD542_MY2021_Tx" SG_ 811 OnePdlDrvButtn_B_Falt 1;
BA_ "U_T6_MCA_MY2020_Tx" SG_ 811 OnePdlDrvButtn_B_Falt 1;
BA_ "GenSigSendType" SG_ 811 OnePdlDrvButtn_B_Falt 3;
BA_ "U_U55X_MY2022_Tx" SG_ 811 OnePdlDrvButtn_B_Stat 1;
BA_ "U_CD542_MY2021_Tx" SG_ 811 OnePdlDrvButtn_B_Stat 1;
BA_ "U_T6_MCA_MY2020_Tx" SG_ 811 OnePdlDrvButtn_B_Stat 1;
BA_ "GenSigSendType" SG_ 811 OnePdlDrvButtn_B_Stat 3;
BA_ "U_CD764_MY2022_Tx" SG_ 811 LongTermReset_B_RqMnu 1;
BA_ "U_U55X_MY2022_Tx" SG_ 811 LongTermReset_B_RqMnu 1;
BA_ "U_CD542_MY2021_Tx" SG_ 811 LongTermReset_B_RqMnu 1;
BA_ "U_T6_MCA_MY2020_Tx" SG_ 811 LongTermReset_B_RqMnu 1;
BA_ "GenSigSendType" SG_ 811 LongTermReset_B_RqMnu 3;
BA_ "U_U55X_MY2022_Tx" SG_ 811 DistToStopover_L_Actl 1;
BA_ "U_CD542_MY2021_Tx" SG_ 811 DistToStopover_L_Actl 1;
BA_ "U_T6_MCA_MY2020_Tx" SG_ 811 DistToStopover_L_Actl 1;
BA_ "U_CD764_MY2022_Rx" SG_ 811 DistToStopover_L_Actl 1;
BA_ "U_U55X_MY2022_Rx" SG_ 811 DistToStopover_L_Actl 1;
BA_ "U_CD542_MY2021_Rx" SG_ 811 DistToStopover_L_Actl 1;
BA_ "ECGUsedRxSignal" SG_ 811 DistToStopover_L_Actl 1;
BA_ "U_T6_MCA_MY2020_Rx" SG_ 811 DistToStopover_L_Actl 1;
BA_ "GenSigStartValue" SG_ 811 DistToStopover_L_Actl 65535;
BA_ "U_U55X_MY2022_Tx" SG_ 811 StopoverType_D_Stat 1;
BA_ "U_CD542_MY2021_Tx" SG_ 811 StopoverType_D_Stat 1;
BA_ "U_T6_MCA_MY2020_Tx" SG_ 811 StopoverType_D_Stat 1;
BA_ "U_U55X_MY2022_Rx" SG_ 811 StopoverType_D_Stat 1;
BA_ "U_CD542_MY2021_Rx" SG_ 811 StopoverType_D_Stat 1;
BA_ "ECGUsedRxSignal" SG_ 811 StopoverType_D_Stat 1;
BA_ "U_CD764_MY2022_Rx" SG_ 811 StopoverType_D_Stat 1;
BA_ "U_T6_MCA_MY2020_Rx" SG_ 811 StopoverType_D_Stat 1;
BA_ "GenSigSendType" SG_ 811 StopoverType_D_Stat 3;
BA_ "U_U55X_MY2022_Tx" SG_ 811 ExtLghtRight_D_RqMnu 1;
BA_ "U_CD542_MY2021_Tx" SG_ 811 ExtLghtRight_D_RqMnu 1;
BA_ "U_T6_MCA_MY2020_Tx" SG_ 811 ExtLghtRight_D_RqMnu 1;
BA_ "GenSigSendType" SG_ 811 ExtLghtRight_D_RqMnu 3;
BA_ "WakeupSignal" SG_ 811 ExtLghtRight_D_RqMnu 1;
BA_ "U_U55X_MY2022_Tx" SG_ 811 AutoLghtOvrrd_B_RqDrv 1;
BA_ "U_CD542_MY2021_Tx" SG_ 811 AutoLghtOvrrd_B_RqDrv 1;
BA_ "U_T6_MCA_MY2020_Tx" SG_ 811 AutoLghtOvrrd_B_RqDrv 1;
BA_ "GenSigSendType" SG_ 811 AutoLghtOvrrd_B_RqDrv 3;
BA_ "WakeupSignal" SG_ 811 AutoLghtOvrrd_B_RqDrv 1;
BA_ "U_U55X_MY2022_Tx" SG_ 811 ExtLghtRear_D_RqMnu 1;
BA_ "U_CD542_MY2021_Tx" SG_ 811 ExtLghtRear_D_RqMnu 1;
BA_ "U_T6_MCA_MY2020_Tx" SG_ 811 ExtLghtRear_D_RqMnu 1;
BA_ "GenSigSendType" SG_ 811 ExtLghtRear_D_RqMnu 3;
BA_ "WakeupSignal" SG_ 811 ExtLghtRear_D_RqMnu 1;
BA_ "U_U55X_MY2022_Tx" SG_ 811 ExtLghtLeft_D_RqMnu 1;
BA_ "U_CD542_MY2021_Tx" SG_ 811 ExtLghtLeft_D_RqMnu 1;
BA_ "U_T6_MCA_MY2020_Tx" SG_ 811 ExtLghtLeft_D_RqMnu 1;
BA_ "GenSigSendType" SG_ 811 ExtLghtLeft_D_RqMnu 3;
BA_ "WakeupSignal" SG_ 811 ExtLghtLeft_D_RqMnu 1;
BA_ "U_U55X_MY2022_Tx" SG_ 811 ExtLghtFront_D_RqMnu 1;
BA_ "U_CD542_MY2021_Tx" SG_ 811 ExtLghtFront_D_RqMnu 1;
BA_ "U_T6_MCA_MY2020_Tx" SG_ 811 ExtLghtFront_D_RqMnu 1;
BA_ "GenSigSendType" SG_ 811 ExtLghtFront_D_RqMnu 3;
BA_ "WakeupSignal" SG_ 811 ExtLghtFront_D_RqMnu 1;
BA_ "U_CD764_MY2022_Tx" SG_ 811 BecRleas_No_RqMnu 1;
BA_ "U_U55X_MY2022_Tx" SG_ 811 BecRleas_No_RqMnu 1;
BA_ "U_CD542_MY2021_Tx" SG_ 811 BecRleas_No_RqMnu 1;
BA_ "U_T6_MCA_MY2020_Tx" SG_ 811 BecRleas_No_RqMnu 1;
BA_ "GenSigSendType" SG_ 811 BecRleas_No_RqMnu 3;
BA_ "WakeupSignal" SG_ 811 BecRleas_No_RqMnu 1;
BA_ "U_U55X_MY2022_Tx" SG_ 811 TrnkFrontRleas_No_RqMnu 1;
BA_ "U_CD542_MY2021_Tx" SG_ 811 TrnkFrontRleas_No_RqMnu 1;
BA_ "U_T6_MCA_MY2020_Tx" SG_ 811 TrnkFrontRleas_No_RqMnu 1;
BA_ "GenSigSendType" SG_ 811 TrnkFrontRleas_No_RqMnu 3;
BA_ "WakeupSignal" SG_ 811 TrnkFrontRleas_No_RqMnu 1;
BA_ "U_U55X_MY2022_Tx" SG_ 811 GoTEditMnte_T_RqMnu 1;
BA_ "U_CD542_MY2021_Tx" SG_ 811 GoTEditMnte_T_RqMnu 1;
BA_ "U_T6_MCA_MY2020_Tx" SG_ 811 GoTEditMnte_T_RqMnu 1;
BA_ "U_CD764_MY2022_Rx" SG_ 811 GoTEditMnte_T_RqMnu 1;
BA_ "U_U55X_MY2022_Rx" SG_ 811 GoTEditMnte_T_RqMnu 1;
BA_ "U_CD542_MY2021_Rx" SG_ 811 GoTEditMnte_T_RqMnu 1;
BA_ "ECGUsedRxSignal" SG_ 811 GoTEditMnte_T_RqMnu 1;
BA_ "U_T6_MCA_MY2020_Rx" SG_ 811 GoTEditMnte_T_RqMnu 1;
BA_ "GenSigSendType" SG_ 811 GoTEditMnte_T_RqMnu 3;
BA_ "GenSigStartValue" SG_ 811 GoTEditMnte_T_RqMnu 14;
BA_ "U_U55X_MY2022_Tx" SG_ 811 GoTEditHr_T_RqMnu 1;
BA_ "U_CD542_MY2021_Tx" SG_ 811 GoTEditHr_T_RqMnu 1;
BA_ "U_T6_MCA_MY2020_Tx" SG_ 811 GoTEditHr_T_RqMnu 1;
BA_ "U_CD764_MY2022_Rx" SG_ 811 GoTEditHr_T_RqMnu 1;
BA_ "U_U55X_MY2022_Rx" SG_ 811 GoTEditHr_T_RqMnu 1;
BA_ "U_CD542_MY2021_Rx" SG_ 811 GoTEditHr_T_RqMnu 1;
BA_ "ECGUsedRxSignal" SG_ 811 GoTEditHr_T_RqMnu 1;
BA_ "U_T6_MCA_MY2020_Rx" SG_ 811 GoTEditHr_T_RqMnu 1;
BA_ "GenSigSendType" SG_ 811 GoTEditHr_T_RqMnu 3;
BA_ "GenSigStartValue" SG_ 811 GoTEditHr_T_RqMnu 30;
BA_ "U_U55X_MY2022_Tx" SG_ 543 TeltalWarnData_No_Actl 1;
BA_ "U_CD542_MY2021_Tx" SG_ 543 TeltalWarnData_No_Actl 1;
BA_ "U_T6_MCA_MY2020_Tx" SG_ 543 TeltalWarnData_No_Actl 1;
BA_ "U_CD764_MY2022_Rx" SG_ 543 TeltalWarnData_No_Actl 1;
BA_ "U_U55X_MY2022_Rx" SG_ 543 TeltalWarnData_No_Actl 1;
BA_ "U_CD542_MY2021_Rx" SG_ 543 TeltalWarnData_No_Actl 1;
BA_ "ECGUsedRxSignal" SG_ 543 TeltalWarnData_No_Actl 1;
BA_ "U_T6_MCA_MY2020_Rx" SG_ 543 TeltalWarnData_No_Actl 1;
BA_ "ECGUsedTxSignal" SG_ 563 GridSrvc01_D_RqCld 1;
BA_ "GenSigSendType" SG_ 563 GridSrvc01_D_RqCld 3;
BA_ "GenSigStartValue" SG_ 563 GridSrvc01_D_RqCld 2;
BA_ "U_CD764_MY2022_Tx" SG_ 563 DrvBhavAudioAlrt_D_Rq 1;
BA_ "ECGUsedTxSignal" SG_ 563 DrvBhavAudioAlrt_D_Rq 1;
BA_ "GenSigSendType" SG_ 563 DrvBhavAudioAlrt_D_Rq 3;
BA_ "U_CD764_MY2022_Tx" SG_ 563 NtfyDrvTrgtDist_L2_Rq 1;
BA_ "U_CD542_MY2021_Tx" SG_ 563 NtfyDrvTrgtDist_L2_Rq 1;
BA_ "ECGUsedTxSignal" SG_ 563 NtfyDrvTrgtDist_L2_Rq 1;
BA_ "GenSigSendType" SG_ 563 NtfyDrvTrgtDist_L2_Rq 3;
BA_ "GenSigStartValue" SG_ 563 NtfyDrvTrgtDist_L2_Rq 8190;
BA_ "GenSigStartValueInteger" SG_ 563 NtfyDrvTrgtDist_L2_Rq 1;
BA_ "WakeupSignal" SG_ 563 NtfyDrvTrgtDist_L2_Rq 1;
BA_ "U_CD764_MY2022_Tx" SG_ 563 BattChrgStrtStop_D_Rq 1;
BA_ "U_U55X_MY2022_Tx" SG_ 563 BattChrgStrtStop_D_Rq 1;
BA_ "U_CD542_MY2021_Tx" SG_ 563 BattChrgStrtStop_D_Rq 1;
BA_ "ECGUsedTxSignal" SG_ 563 BattChrgStrtStop_D_Rq 1;
BA_ "U_T6_MCA_MY2020_Tx" SG_ 563 BattChrgStrtStop_D_Rq 1;
BA_ "GenSigSendType" SG_ 563 BattChrgStrtStop_D_Rq 3;
BA_ "U_CD764_MY2022_Tx" SG_ 563 DrvBhavWarn_B_Rq 1;
BA_ "U_U55X_MY2022_Tx" SG_ 563 DrvBhavWarn_B_Rq 1;
BA_ "U_CD542_MY2021_Tx" SG_ 563 DrvBhavWarn_B_Rq 1;
BA_ "ECGUsedTxSignal" SG_ 563 DrvBhavWarn_B_Rq 1;
BA_ "U_T6_MCA_MY2020_Tx" SG_ 563 DrvBhavWarn_B_Rq 1;
BA_ "U_CD764_MY2022_Rx" SG_ 563 DrvBhavWarn_B_Rq 1;
BA_ "U_U55X_MY2022_Rx" SG_ 563 DrvBhavWarn_B_Rq 1;
BA_ "U_T6_MCA_MY2020_Rx" SG_ 563 DrvBhavWarn_B_Rq 1;
BA_ "GenSigSendType" SG_ 563 DrvBhavWarn_B_Rq 3;
BA_ "U_U55X_MY2022_Tx" SG_ 563 OfbChrgSetSync_D_Rq 1;
BA_ "U_CD542_MY2021_Tx" SG_ 563 OfbChrgSetSync_D_Rq 1;
BA_ "ECGUsedTxSignal" SG_ 563 OfbChrgSetSync_D_Rq 1;
BA_ "U_U55X_MY2022_Rx" SG_ 563 OfbChrgSetSync_D_Rq 1;
BA_ "U_CD542_MY2021_Rx" SG_ 563 OfbChrgSetSync_D_Rq 1;
BA_ "GenSigSendType" SG_ 563 OfbChrgSetSync_D_Rq 3;
BA_ "U_CD764_MY2022_Tx" SG_ 563 KeyOffPwMde_D_Stat 1;
BA_ "U_U55X_MY2022_Tx" SG_ 563 KeyOffPwMde_D_Stat 1;
BA_ "U_CD542_MY2021_Tx" SG_ 563 KeyOffPwMde_D_Stat 1;
BA_ "ECGUsedTxSignal" SG_ 563 KeyOffPwMde_D_Stat 1;
BA_ "U_T6_MCA_MY2020_Tx" SG_ 563 KeyOffPwMde_D_Stat 1;
BA_ "U_CD764_MY2022_Rx" SG_ 563 KeyOffPwMde_D_Stat 1;
BA_ "U_CD542_MY2021_Rx" SG_ 563 KeyOffPwMde_D_Stat 1;
BA_ "U_U55X_MY2022_Rx" SG_ 563 KeyOffPwMde_D_Stat 1;
BA_ "U_T6_MCA_MY2020_Rx" SG_ 563 KeyOffPwMde_D_Stat 1;
BA_ "GenSigSendType" SG_ 563 KeyOffPwMde_D_Stat 3;
BA_ "U_CD764_MY2022_Tx" SG_ 563 ModemReset_D_Stat 1;
BA_ "U_U55X_MY2022_Tx" SG_ 563 ModemReset_D_Stat 1;
BA_ "U_CD542_MY2021_Tx" SG_ 563 ModemReset_D_Stat 1;
BA_ "ECGUsedTxSignal" SG_ 563 ModemReset_D_Stat 1;
BA_ "U_T6_MCA_MY2020_Tx" SG_ 563 ModemReset_D_Stat 1;
BA_ "U_T6_MCA_MY2020_Rx" SG_ 563 ModemReset_D_Stat 1;
BA_ "U_CD764_MY2022_Rx" SG_ 563 ModemReset_D_Stat 1;
BA_ "U_CD542_MY2021_Rx" SG_ 563 ModemReset_D_Stat 1;
BA_ "GenSigSendType" SG_ 563 ModemReset_D_Stat 3;
BA_ "U_CD764_MY2022_Tx" SG_ 563 FactoryReset_St 1;
BA_ "U_U55X_MY2022_Tx" SG_ 563 FactoryReset_St 1;
BA_ "U_CD542_MY2021_Tx" SG_ 563 FactoryReset_St 1;
BA_ "ECGUsedTxSignal" SG_ 563 FactoryReset_St 1;
BA_ "U_T6_MCA_MY2020_Tx" SG_ 563 FactoryReset_St 1;
BA_ "U_T6_MCA_MY2020_Rx" SG_ 563 FactoryReset_St 1;
BA_ "U_CD764_MY2022_Rx" SG_ 563 FactoryReset_St 1;
BA_ "U_CD542_MY2021_Rx" SG_ 563 FactoryReset_St 1;
BA_ "GenSigSendType" SG_ 563 FactoryReset_St 3;
BA_ "GenSigSendType" SG_ 794 DcacFaltMsgTxt_D2_Rq 3;
BA_ "GenSigStartValueInteger" SG_ 794 DcacFaltMsgTxt_D2_Rq 1;
BA_ "U_U55X_MY2022_Rx" SG_ 794 HvacBlwrRear_D_Stat_UB 1;
BA_ "U_T6_MCA_MY2020_Rx" SG_ 794 HvacBlwrRear_D_Stat_UB 1;
BA_ "U_U55X_MY2022_Rx" SG_ 794 HvacBlwrFront_D_Stat_UB 1;
BA_ "U_T6_MCA_MY2020_Rx" SG_ 794 HvacBlwrFront_D_Stat_UB 1;
BA_ "U_U55X_MY2022_Rx" SG_ 794 HvacBlwrRear_D_Stat 1;
BA_ "U_T6_MCA_MY2020_Rx" SG_ 794 HvacBlwrRear_D_Stat 1;
BA_ "GenSigSendType" SG_ 794 HvacBlwrRear_D_Stat 3;
BA_ "U_U55X_MY2022_Rx" SG_ 794 HvacBlwrFront_D_Stat 1;
BA_ "U_T6_MCA_MY2020_Rx" SG_ 794 HvacBlwrFront_D_Stat 1;
BA_ "GenSigSendType" SG_ 794 HvacBlwrFront_D_Stat 3;
BA_ "U_U55X_MY2022_Rx" SG_ 794 SpotLghtLeft_D_Stat_UB 1;
BA_ "U_CD542_MY2021_Rx" SG_ 794 SpotLghtLeft_D_Stat_UB 1;
BA_ "U_T6_MCA_MY2020_Rx" SG_ 794 SpotLghtLeft_D_Stat_UB 1;
BA_ "U_U55X_MY2022_Rx" SG_ 794 SpotLghtRight_D_Stat_UB 1;
BA_ "U_CD542_MY2021_Rx" SG_ 794 SpotLghtRight_D_Stat_UB 1;
BA_ "U_T6_MCA_MY2020_Rx" SG_ 794 SpotLghtRight_D_Stat_UB 1;
BA_ "U_U55X_MY2022_Rx" SG_ 794 SpotLghtRight_D_Stat 1;
BA_ "U_CD542_MY2021_Rx" SG_ 794 SpotLghtRight_D_Stat 1;
BA_ "U_T6_MCA_MY2020_Rx" SG_ 794 SpotLghtRight_D_Stat 1;
BA_ "GenSigSendType" SG_ 794 SpotLghtRight_D_Stat 3;
BA_ "U_U55X_MY2022_Rx" SG_ 794 SpotLghtLeft_D_Stat 1;
BA_ "U_CD542_MY2021_Rx" SG_ 794 SpotLghtLeft_D_Stat 1;
BA_ "U_T6_MCA_MY2020_Rx" SG_ 794 SpotLghtLeft_D_Stat 1;
BA_ "GenSigSendType" SG_ 794 SpotLghtLeft_D_Stat 3;
BA_ "U_CD764_MY2022_Tx" SG_ 587 PHONE_RDISP2_WORD_Rx 1;
BA_ "U_U55X_MY2022_Tx" SG_ 587 PHONE_RDISP2_WORD_Rx 1;
BA_ "U_T6_MCA_MY2020_Tx" SG_ 587 PHONE_RDISP2_WORD_Rx 1;
BA_ "U_U55X_MY2022_Rx" SG_ 587 PHONE_RDISP2_WORD_Rx 1;
BA_ "U_CD542_MY2021_Rx" SG_ 587 PHONE_RDISP2_WORD_Rx 1;
BA_ "U_CD542_MY2021_Tx" SG_ 579 PHONE_RDISP2_WORD_Tx 1;
BA_ "U_T6_MCA_MY2020_Tx" SG_ 579 PHONE_RDISP2_WORD_Tx 1;
BA_ "U_CD764_MY2022_Rx" SG_ 579 PHONE_RDISP2_WORD_Tx 1;
BA_ "U_U55X_MY2022_Rx" SG_ 579 PHONE_RDISP2_WORD_Tx 1;
BA_ "U_T6_MCA_MY2020_Rx" SG_ 579 PHONE_RDISP2_WORD_Tx 1;
BA_ "U_CD764_MY2022_Tx" SG_ 585 NAV_RDISP2_WORD_Rx 1;
BA_ "U_U55X_MY2022_Tx" SG_ 585 NAV_RDISP2_WORD_Rx 1;
BA_ "U_T6_MCA_MY2020_Tx" SG_ 585 NAV_RDISP2_WORD_Rx 1;
BA_ "U_U55X_MY2022_Rx" SG_ 585 NAV_RDISP2_WORD_Rx 1;
BA_ "U_CD542_MY2021_Rx" SG_ 585 NAV_RDISP2_WORD_Rx 1;
BA_ "U_CD764_MY2022_Tx" SG_ 586 CONMP_RDISP2_WORD_Rx 1;
BA_ "U_U55X_MY2022_Tx" SG_ 586 CONMP_RDISP2_WORD_Rx 1;
BA_ "U_T6_MCA_MY2020_Tx" SG_ 586 CONMP_RDISP2_WORD_Rx 1;
BA_ "U_U55X_MY2022_Rx" SG_ 586 CONMP_RDISP2_WORD_Rx 1;
BA_ "U_CD542_MY2021_Rx" SG_ 586 CONMP_RDISP2_WORD_Rx 1;
BA_ "U_U55X_MY2022_Tx" SG_ 578 CONMP_RDISP2_WORD_Tx 1;
BA_ "U_CD542_MY2021_Tx" SG_ 578 CONMP_RDISP2_WORD_Tx 1;
BA_ "U_T6_MCA_MY2020_Tx" SG_ 578 CONMP_RDISP2_WORD_Tx 1;
BA_ "U_CD764_MY2022_Rx" SG_ 578 CONMP_RDISP2_WORD_Tx 1;
BA_ "U_U55X_MY2022_Rx" SG_ 578 CONMP_RDISP2_WORD_Tx 1;
BA_ "U_T6_MCA_MY2020_Rx" SG_ 578 CONMP_RDISP2_WORD_Tx 1;
BA_ "U_U55X_MY2022_Tx" SG_ 577 NAV_RDISP2_WORD_Tx 1;
BA_ "U_CD542_MY2021_Tx" SG_ 577 NAV_RDISP2_WORD_Tx 1;
BA_ "U_T6_MCA_MY2020_Tx" SG_ 577 NAV_RDISP2_WORD_Tx 1;
BA_ "U_CD764_MY2022_Rx" SG_ 577 NAV_RDISP2_WORD_Tx 1;
BA_ "U_U55X_MY2022_Rx" SG_ 577 NAV_RDISP2_WORD_Tx 1;
BA_ "U_T6_MCA_MY2020_Rx" SG_ 577 NAV_RDISP2_WORD_Tx 1;
BA_ "U_CD764_MY2022_Tx" SG_ 712 NAV_MC_WORD_Rx 1;
BA_ "U_U55X_MY2022_Tx" SG_ 712 NAV_MC_WORD_Rx 1;
BA_ "U_CD764_MY2022_Rx" SG_ 712 NAV_MC_WORD_Rx 1;
BA_ "U_U55X_MY2022_Rx" SG_ 712 NAV_MC_WORD_Rx 1;
BA_ "U_CD542_MY2021_Rx" SG_ 712 NAV_MC_WORD_Rx 1;
BA_ "U_T6_MCA_MY2020_Rx" SG_ 712 NAV_MC_WORD_Rx 1;
BA_ "U_U55X_MY2022_Tx" SG_ 717 DSPAMP_RDISP_WORD_Rx 1;
BA_ "U_CD542_MY2021_Tx" SG_ 717 DSPAMP_RDISP_WORD_Rx 1;
BA_ "U_T6_MCA_MY2020_Tx" SG_ 717 DSPAMP_RDISP_WORD_Rx 1;
BA_ "U_U55X_MY2022_Rx" SG_ 717 DSPAMP_RDISP_WORD_Rx 1;
BA_ "U_T6_MCA_MY2020_Rx" SG_ 717 DSPAMP_RDISP_WORD_Rx 1;
BA_ "U_U55X_MY2022_Tx" SG_ 719 MyKeySrvr_Clnt_Word_Rx 1;
BA_ "U_CD542_MY2021_Tx" SG_ 719 MyKeySrvr_Clnt_Word_Rx 1;
BA_ "U_T6_MCA_MY2020_Tx" SG_ 719 MyKeySrvr_Clnt_Word_Rx 1;
BA_ "U_CD764_MY2022_Rx" SG_ 719 MyKeySrvr_Clnt_Word_Rx 1;
BA_ "U_U55X_MY2022_Rx" SG_ 719 MyKeySrvr_Clnt_Word_Rx 1;
BA_ "U_CD542_MY2021_Rx" SG_ 719 MyKeySrvr_Clnt_Word_Rx 1;
BA_ "U_T6_MCA_MY2020_Rx" SG_ 719 MyKeySrvr_Clnt_Word_Rx 1;
BA_ "GenSigSendType" SG_ 1879 TesterPhysicalReqTBM_HS3 3;
BA_ "GenSigSendType" SG_ 1887 TesterPhysicalResTBM_HS3 3;
BA_ "U_U55X_MY2022_Tx" SG_ 1146 TrlrAidSwtch_D_RqDrv 1;
BA_ "U_T6_MCA_MY2020_Tx" SG_ 1146 TrlrAidSwtch_D_RqDrv 1;
BA_ "U_P702_MY2021_Tx" SG_ 1146 TrlrAidSwtch_D_RqDrv 1;
BA_ "U_U55X_MY2022_Tx" SG_ 1146 TrlrAidCtl_U_RqDrv 1;
BA_ "U_T6_MCA_MY2020_Tx" SG_ 1146 TrlrAidCtl_U_RqDrv 1;
BA_ "U_P702_MY2021_Tx" SG_ 1146 TrlrAidCtl_U_RqDrv 1;
BA_ "GenSigStartValue" SG_ 1146 TrlrAidCtl_U_RqDrv 4093;
BA_ "GenSigStartValueInteger" SG_ 1146 TrlrAidCtl_U_RqDrv 4094;
BA_ "U_U55X_MY2022_Tx" SG_ 737 APIM_ECG_Word_Tx 1;
BA_ "U_CD542_MY2021_Tx" SG_ 737 APIM_ECG_Word_Tx 1;
BA_ "U_T6_MCA_MY2020_Tx" SG_ 737 APIM_ECG_Word_Tx 1;
BA_ "U_CD764_MY2022_Rx" SG_ 737 APIM_ECG_Word_Tx 1;
BA_ "U_U55X_MY2022_Rx" SG_ 737 APIM_ECG_Word_Tx 1;
BA_ "U_CD542_MY2021_Rx" SG_ 737 APIM_ECG_Word_Tx 1;
BA_ "ECGUsedRxSignal" SG_ 737 APIM_ECG_Word_Tx 1;
BA_ "U_T6_MCA_MY2020_Rx" SG_ 737 APIM_ECG_Word_Tx 1;
BA_ "U_CD764_MY2022_Tx" SG_ 745 ECG_APIM_Word_Tx 1;
BA_ "U_U55X_MY2022_Tx" SG_ 745 ECG_APIM_Word_Tx 1;
BA_ "U_CD542_MY2021_Tx" SG_ 745 ECG_APIM_Word_Tx 1;
BA_ "ECGUsedTxSignal" SG_ 745 ECG_APIM_Word_Tx 1;
BA_ "U_T6_MCA_MY2020_Tx" SG_ 745 ECG_APIM_Word_Tx 1;
BA_ "U_CD764_MY2022_Rx" SG_ 745 ECG_APIM_Word_Tx 1;
BA_ "U_U55X_MY2022_Rx" SG_ 745 ECG_APIM_Word_Tx 1;
BA_ "U_CD542_MY2021_Rx" SG_ 745 ECG_APIM_Word_Tx 1;
BA_ "U_T6_MCA_MY2020_Rx" SG_ 745 ECG_APIM_Word_Tx 1;
BA_ "U_CD764_MY2022_Tx" SG_ 1195 TCU_RDISP2_WORD_Rx 1;
BA_ "U_U55X_MY2022_Tx" SG_ 1195 TCU_RDISP2_WORD_Rx 1;
BA_ "U_T6_MCA_MY2020_Tx" SG_ 1195 TCU_RDISP2_WORD_Rx 1;
BA_ "U_CD764_MY2022_Rx" SG_ 1185 TCU_MC_WORD_Rx 1;
BA_ "ECGUsedRxSignal" SG_ 1185 TCU_MC_WORD_Rx 1;
BA_ "U_CD764_MY2022_Tx" SG_ 1435 HUD_GWOnBoardTester 1;
BA_ "U_U55X_MY2022_Tx" SG_ 1435 HUD_GWOnBoardTester 1;
BA_ "U_T6_MCA_MY2020_Tx" SG_ 1435 HUD_GWOnBoardTester 1;
BA_ "GenSigStartValue" SG_ 1435 HUD_GWOnBoardTester 255;
BA_ "ContentDependant" SG_ 1435 HUD_GWOnBoardTester 1;
BA_ "GenSigStartValueInteger" SG_ 1435 HUD_GWOnBoardTester 255;
BA_ "U_CD764_MY2022_Tx" SG_ 1435 HUD_GWNMProxy 1;
BA_ "U_U55X_MY2022_Tx" SG_ 1435 HUD_GWNMProxy 1;
BA_ "U_T6_MCA_MY2020_Tx" SG_ 1435 HUD_GWNMProxy 1;
BA_ "GenSigStartValue" SG_ 1435 HUD_GWNMProxy 255;
BA_ "ContentDependant" SG_ 1435 HUD_GWNMProxy 1;
BA_ "GenSigStartValueInteger" SG_ 1435 HUD_GWNMProxy 255;
BA_ "U_CD764_MY2022_Tx" SG_ 1435 HUD_AutoSarNMReserved4 1;
BA_ "U_U55X_MY2022_Tx" SG_ 1435 HUD_AutoSarNMReserved4 1;
BA_ "U_T6_MCA_MY2020_Tx" SG_ 1435 HUD_AutoSarNMReserved4 1;
BA_ "GenSigStartValue" SG_ 1435 HUD_AutoSarNMReserved4 255;
BA_ "ContentDependant" SG_ 1435 HUD_AutoSarNMReserved4 1;
BA_ "GenSigStartValueInteger" SG_ 1435 HUD_AutoSarNMReserved4 255;
BA_ "U_CD764_MY2022_Tx" SG_ 1435 HUD_AutoSarNMReserved3 1;
BA_ "U_U55X_MY2022_Tx" SG_ 1435 HUD_AutoSarNMReserved3 1;
BA_ "U_T6_MCA_MY2020_Tx" SG_ 1435 HUD_AutoSarNMReserved3 1;
BA_ "GenSigStartValue" SG_ 1435 HUD_AutoSarNMReserved3 255;
BA_ "ContentDependant" SG_ 1435 HUD_AutoSarNMReserved3 1;
BA_ "GenSigStartValueInteger" SG_ 1435 HUD_AutoSarNMReserved3 255;
BA_ "U_CD764_MY2022_Tx" SG_ 1435 HUD_AutoSarNMReserved2 1;
BA_ "U_U55X_MY2022_Tx" SG_ 1435 HUD_AutoSarNMReserved2 1;
BA_ "U_T6_MCA_MY2020_Tx" SG_ 1435 HUD_AutoSarNMReserved2 1;
BA_ "GenSigStartValue" SG_ 1435 HUD_AutoSarNMReserved2 255;
BA_ "ContentDependant" SG_ 1435 HUD_AutoSarNMReserved2 1;
BA_ "GenSigStartValueInteger" SG_ 1435 HUD_AutoSarNMReserved2 255;
BA_ "U_CD764_MY2022_Tx" SG_ 1435 HUD_AutoSarNMReserved 1;
BA_ "U_U55X_MY2022_Tx" SG_ 1435 HUD_AutoSarNMReserved 1;
BA_ "U_T6_MCA_MY2020_Tx" SG_ 1435 HUD_AutoSarNMReserved 1;
BA_ "GenSigStartValue" SG_ 1435 HUD_AutoSarNMReserved 255;
BA_ "ContentDependant" SG_ 1435 HUD_AutoSarNMReserved 1;
BA_ "GenSigStartValueInteger" SG_ 1435 HUD_AutoSarNMReserved 255;
BA_ "U_CD764_MY2022_Tx" SG_ 1435 HUD_AutoSarNMNodeId 1;
BA_ "U_U55X_MY2022_Tx" SG_ 1435 HUD_AutoSarNMNodeId 1;
BA_ "U_T6_MCA_MY2020_Tx" SG_ 1435 HUD_AutoSarNMNodeId 1;
BA_ "GenSigStartValue" SG_ 1435 HUD_AutoSarNMNodeId 155;
BA_ "ContentDependant" SG_ 1435 HUD_AutoSarNMNodeId 1;
BA_ "GenSigStartValueInteger" SG_ 1435 HUD_AutoSarNMNodeId 83;
BA_ "U_CD764_MY2022_Tx" SG_ 1435 HUD_AutoSarNMControl 1;
BA_ "U_U55X_MY2022_Tx" SG_ 1435 HUD_AutoSarNMControl 1;
BA_ "U_T6_MCA_MY2020_Tx" SG_ 1435 HUD_AutoSarNMControl 1;
BA_ "ContentDependant" SG_ 1435 HUD_AutoSarNMControl 1;
BA_ "U_T6_MCA_MY2020_Tx" SG_ 1109 eCallConfirmation 1;
BA_ "U_P702_MY2021_Tx" SG_ 1109 eCallConfirmation 1;
BA_ "U_U55X_MY2022_Tx" SG_ 1109 eCallConfirmation 1;
BA_ "U_CD542_MY2021_Tx" SG_ 1109 eCallConfirmation 1;
BA_ "U_CD764_MY2022_Rx" SG_ 1109 eCallConfirmation 1;
BA_ "GenSigSendType" SG_ 1109 eCallConfirmation 3;
BA_ "U_U55X_MY2022_Tx" SG_ 1492 TRM_GWOnBoardTester 1;
BA_ "U_T6_MCA_MY2020_Tx" SG_ 1492 TRM_GWOnBoardTester 1;
BA_ "U_P702_MY2021_Tx" SG_ 1492 TRM_GWOnBoardTester 1;
BA_ "GenSigStartValue" SG_ 1492 TRM_GWOnBoardTester 255;
BA_ "ContentDependant" SG_ 1492 TRM_GWOnBoardTester 1;
BA_ "GenSigStartValueInteger" SG_ 1492 TRM_GWOnBoardTester 255;
BA_ "U_U55X_MY2022_Tx" SG_ 1492 TRM_GWNMProxy 1;
BA_ "U_T6_MCA_MY2020_Tx" SG_ 1492 TRM_GWNMProxy 1;
BA_ "U_P702_MY2021_Tx" SG_ 1492 TRM_GWNMProxy 1;
BA_ "GenSigStartValue" SG_ 1492 TRM_GWNMProxy 255;
BA_ "ContentDependant" SG_ 1492 TRM_GWNMProxy 1;
BA_ "GenSigStartValueInteger" SG_ 1492 TRM_GWNMProxy 255;
BA_ "U_U55X_MY2022_Tx" SG_ 1492 TRM_AutoSarNMReserved4 1;
BA_ "U_T6_MCA_MY2020_Tx" SG_ 1492 TRM_AutoSarNMReserved4 1;
BA_ "U_P702_MY2021_Tx" SG_ 1492 TRM_AutoSarNMReserved4 1;
BA_ "GenSigStartValue" SG_ 1492 TRM_AutoSarNMReserved4 255;
BA_ "ContentDependant" SG_ 1492 TRM_AutoSarNMReserved4 1;
BA_ "GenSigStartValueInteger" SG_ 1492 TRM_AutoSarNMReserved4 255;
BA_ "U_U55X_MY2022_Tx" SG_ 1492 TRM_AutoSarNMReserved3 1;
BA_ "U_T6_MCA_MY2020_Tx" SG_ 1492 TRM_AutoSarNMReserved3 1;
BA_ "U_P702_MY2021_Tx" SG_ 1492 TRM_AutoSarNMReserved3 1;
BA_ "GenSigStartValue" SG_ 1492 TRM_AutoSarNMReserved3 255;
BA_ "ContentDependant" SG_ 1492 TRM_AutoSarNMReserved3 1;
BA_ "GenSigStartValueInteger" SG_ 1492 TRM_AutoSarNMReserved3 255;
BA_ "U_U55X_MY2022_Tx" SG_ 1492 TRM_AutoSarNMReserved2 1;
BA_ "U_T6_MCA_MY2020_Tx" SG_ 1492 TRM_AutoSarNMReserved2 1;
BA_ "U_P702_MY2021_Tx" SG_ 1492 TRM_AutoSarNMReserved2 1;
BA_ "GenSigStartValue" SG_ 1492 TRM_AutoSarNMReserved2 255;
BA_ "ContentDependant" SG_ 1492 TRM_AutoSarNMReserved2 1;
BA_ "GenSigStartValueInteger" SG_ 1492 TRM_AutoSarNMReserved2 255;
BA_ "U_U55X_MY2022_Tx" SG_ 1492 TRM_AutoSarNMReserved1 1;
BA_ "U_T6_MCA_MY2020_Tx" SG_ 1492 TRM_AutoSarNMReserved1 1;
BA_ "U_P702_MY2021_Tx" SG_ 1492 TRM_AutoSarNMReserved1 1;
BA_ "GenSigStartValue" SG_ 1492 TRM_AutoSarNMReserved1 255;
BA_ "ContentDependant" SG_ 1492 TRM_AutoSarNMReserved1 1;
BA_ "GenSigStartValueInteger" SG_ 1492 TRM_AutoSarNMReserved1 255;
BA_ "U_U55X_MY2022_Tx" SG_ 1492 TRM_AutoSarNMNodeId 1;
BA_ "U_T6_MCA_MY2020_Tx" SG_ 1492 TRM_AutoSarNMNodeId 1;
BA_ "U_P702_MY2021_Tx" SG_ 1492 TRM_AutoSarNMNodeId 1;
BA_ "GenSigStartValue" SG_ 1492 TRM_AutoSarNMNodeId 212;
BA_ "ContentDependant" SG_ 1492 TRM_AutoSarNMNodeId 1;
BA_ "GenSigStartValueInteger" SG_ 1492 TRM_AutoSarNMNodeId 150;
BA_ "U_U55X_MY2022_Tx" SG_ 1492 TRM_AutoSarNMControl 1;
BA_ "U_T6_MCA_MY2020_Tx" SG_ 1492 TRM_AutoSarNMControl 1;
BA_ "U_P702_MY2021_Tx" SG_ 1492 TRM_AutoSarNMControl 1;
BA_ "ContentDependant" SG_ 1492 TRM_AutoSarNMControl 1;
BA_ "U_U55X_MY2022_Tx" SG_ 1945 TesterPhysicalResTRM_ITRM 1;
BA_ "U_T6_MCA_MY2020_Tx" SG_ 1945 TesterPhysicalResTRM_ITRM 1;
BA_ "U_P702_MY2021_Tx" SG_ 1945 TesterPhysicalResTRM_ITRM 1;
BA_ "GenSigSendType" SG_ 1945 TesterPhysicalResTRM_ITRM 3;
BA_ "U_U55X_MY2022_Rx" SG_ 1937 TesterPhysicalReqTRM_ITRM 1;
BA_ "U_T6_MCA_MY2020_Rx" SG_ 1937 TesterPhysicalReqTRM_ITRM 1;
BA_ "U_P702_MY2021_Rx" SG_ 1937 TesterPhysicalReqTRM_ITRM 1;
BA_ "GenSigSendType" SG_ 1937 TesterPhysicalReqTRM_ITRM 3;
BA_ "WakeupSignal" SG_ 300 TrukBedLght_B_Stat2 1;
BA_ "U_CD764_MY2022_Tx" SG_ 2612224006 PARSEDPushHUDtoGWM_ECG 1;
BA_ "U_CD764_MY2022_Rx" SG_ 2612224006 PARSEDPushHUDtoGWM_ECG 1;
BA_ "ECGUsedRxSignal" SG_ 2612224006 PARSEDPushHUDtoGWM_ECG 1;
BA_ "GenSigSendType" SG_ 2612224006 PARSEDPushHUDtoGWM_ECG 3;
BA_ "U_CD764_MY2022_Tx" SG_ 2611175430 PARSEDPhysHUDtoGWM_ECG 1;
BA_ "U_CD764_MY2022_Rx" SG_ 2611175430 PARSEDPhysHUDtoGWM_ECG 1;
BA_ "ECGUsedRxSignal" SG_ 2611175430 PARSEDPhysHUDtoGWM_ECG 1;
BA_ "GenSigSendType" SG_ 2611175430 PARSEDPhysHUDtoGWM_ECG 3;
BA_ "U_CD764_MY2022_Tx" SG_ 2610960600 PARSEDPhysGWM_ECGtoHUD 1;
BA_ "ECGUsedTxSignal" SG_ 2610960600 PARSEDPhysGWM_ECGtoHUD 1;
BA_ "U_CD764_MY2022_Rx" SG_ 2610960600 PARSEDPhysGWM_ECGtoHUD 1;
BA_ "GenSigSendType" SG_ 2610960600 PARSEDPhysGWM_ECGtoHUD 3;
BA_ "U_CD764_MY2022_Tx" SG_ 2610126854 OTAPhysHUDtoGWM_ECG 1;
BA_ "U_CD764_MY2022_Rx" SG_ 2610126854 OTAPhysHUDtoGWM_ECG 1;
BA_ "ECGUsedRxSignal" SG_ 2610126854 OTAPhysHUDtoGWM_ECG 1;
BA_ "GenSigSendType" SG_ 2610126854 OTAPhysHUDtoGWM_ECG 3;
BA_ "U_CD764_MY2022_Tx" SG_ 2609912024 OTAPhysGWM_ECGtoHUD 1;
BA_ "ECGUsedTxSignal" SG_ 2609912024 OTAPhysGWM_ECGtoHUD 1;
BA_ "U_CD764_MY2022_Rx" SG_ 2609912024 OTAPhysGWM_ECGtoHUD 1;
BA_ "GenSigSendType" SG_ 2609912024 OTAPhysGWM_ECGtoHUD 3;
BA_ "GenSigSendType" SG_ 662 Running_Board_Cmd2 3;
BA_ "GenSigSendType" SG_ 662 Third_Rear_Set_Temp 3;
BA_ "GenSigSendType" SG_ 662 Third_Rear_Blower_Speed 3;
BA_ "GenSigSendType" SG_ 662 Rear_Temp 3;
BA_ "GenSigSendType" SG_ 662 Rear_Set_Temp 3;
BA_ "GenSigSendType" SG_ 662 Rear_Blower_Speed 3;
BA_ "GenSigStartValue" SG_ 837 VehCurb_M_Actl 1022;
BA_ "GenSigStartValue" SG_ 837 VehGvwr_M_Actl 1022;
BA_ "MetaData" SG_ 837 SuspVLimBRq_No_Cs 1;
BA_ "MetaData" SG_ 837 SuspVLimBRq_No_Cnt 1;
BA_ "U_U55X_MY2022_Rx" SG_ 837 Ccd_B_Falt 1;
BA_ "U_CD542_MY2021_Rx" SG_ 837 Ccd_B_Falt 1;
BA_ "U_T6_MCA_MY2020_Rx" SG_ 837 Ccd_B_Falt 1;
BA_ "U_CD764_MY2022_Rx" SG_ 837 AirSusp_D_Stat 1;
BA_ "U_CD764_MY2022_Rx" SG_ 837 AirSuspMsgTxt_D_Rq 1;
BA_ "U_CD764_MY2022_Rx" SG_ 837 SuspDrvMde_D_Stat 1;
BA_ "U_T6_MCA_MY2020_Rx" SG_ 837 SuspDrvMde_D_Stat 1;
BA_ "U_CD764_MY2022_Rx" SG_ 837 CcdMsgTxt_D_RqDsply 1;
BA_ "U_CD542_MY2021_Rx" SG_ 837 CcdMsgTxt_D_RqDsply 1;
BA_ "U_T6_MCA_MY2020_Rx" SG_ 837 CcdMsgTxt_D_RqDsply 1;
BA_ "GenSigStartValue" SG_ 1121 OffRdSwtch_D_RqMnu 2;
BA_ "U_U55X_MY2022_Tx" SG_ 140 CcAslButtnIndxIncPress2 1;
BA_ "U_T6_MCA_MY2020_Tx" SG_ 140 CcAslButtnIndxIncPress2 1;
BA_ "GenSigSendType" SG_ 140 CcAslButtnIndxIncPress2 3;
BA_ "U_U55X_MY2022_Tx" SG_ 140 SteWhlSwtchMde_D_Stat 1;
BA_ "U_CD542_MY2021_Tx" SG_ 140 SteWhlSwtchMde_D_Stat 1;
BA_ "U_T6_MCA_MY2020_Tx" SG_ 140 SteWhlSwtchMde_D_Stat 1;
BA_ "GenSigSendType" SG_ 140 SteWhlSwtchMde_D_Stat 3;
BA_ "U_U55X_MY2022_Tx" SG_ 140 CcAslButtnOffCnclPress2 1;
BA_ "U_T6_MCA_MY2020_Tx" SG_ 140 CcAslButtnOffCnclPress2 1;
BA_ "GenSigSendType" SG_ 140 CcAslButtnOffCnclPress2 3;
BA_ "U_U55X_MY2022_Tx" SG_ 140 CcAslButtnIndxDecPress2 1;
BA_ "U_T6_MCA_MY2020_Tx" SG_ 140 CcAslButtnIndxDecPress2 1;
BA_ "GenSigSendType" SG_ 140 CcAslButtnIndxDecPress2 3;
BA_ "U_U55X_MY2022_Tx" SG_ 140 CcAslButtnCnclResPress2 1;
BA_ "U_T6_MCA_MY2020_Tx" SG_ 140 CcAslButtnCnclResPress2 1;
BA_ "GenSigSendType" SG_ 140 CcAslButtnCnclResPress2 3;
BA_ "U_U55X_MY2022_Tx" SG_ 140 CcAslButtnResIncPress3 1;
BA_ "U_T6_MCA_MY2020_Tx" SG_ 140 CcAslButtnResIncPress3 1;
BA_ "GenSigSendType" SG_ 140 CcAslButtnResIncPress3 3;
BA_ "U_U55X_MY2022_Tx" SG_ 140 CcButtnOnPress3 1;
BA_ "U_T6_MCA_MY2020_Tx" SG_ 140 CcButtnOnPress3 1;
BA_ "GenSigSendType" SG_ 140 CcButtnOnPress3 3;
BA_ "U_U55X_MY2022_Tx" SG_ 140 CcButtnOnOffPress3 1;
BA_ "U_T6_MCA_MY2020_Tx" SG_ 140 CcButtnOnOffPress3 1;
BA_ "GenSigSendType" SG_ 140 CcButtnOnOffPress3 3;
BA_ "U_U55X_MY2022_Tx" SG_ 140 CcButtnOnOffCnclPress3 1;
BA_ "U_T6_MCA_MY2020_Tx" SG_ 140 CcButtnOnOffCnclPress3 1;
BA_ "GenSigSendType" SG_ 140 CcButtnOnOffCnclPress3 3;
BA_ "U_U55X_MY2022_Tx" SG_ 140 CcButtnOffPress3 1;
BA_ "U_T6_MCA_MY2020_Tx" SG_ 140 CcButtnOffPress3 1;
BA_ "GenSigSendType" SG_ 140 CcButtnOffPress3 3;
BA_ "U_U55X_MY2022_Tx" SG_ 140 CcAsllButtnResPress3 1;
BA_ "U_T6_MCA_MY2020_Tx" SG_ 140 CcAsllButtnResPress3 1;
BA_ "GenSigSendType" SG_ 140 CcAsllButtnResPress3 3;
BA_ "U_U55X_MY2022_Tx" SG_ 140 CcAslButtnSetPress3 1;
BA_ "U_T6_MCA_MY2020_Tx" SG_ 140 CcAslButtnSetPress3 1;
BA_ "GenSigSendType" SG_ 140 CcAslButtnSetPress3 3;
BA_ "U_U55X_MY2022_Tx" SG_ 140 CcAslButtnSetIncPress3 1;
BA_ "U_T6_MCA_MY2020_Tx" SG_ 140 CcAslButtnSetIncPress3 1;
BA_ "GenSigSendType" SG_ 140 CcAslButtnSetIncPress3 3;
BA_ "U_U55X_MY2022_Tx" SG_ 140 CcAslButtnSetDecPress3 1;
BA_ "U_T6_MCA_MY2020_Tx" SG_ 140 CcAslButtnSetDecPress3 1;
BA_ "GenSigSendType" SG_ 140 CcAslButtnSetDecPress3 3;
BA_ "U_U55X_MY2022_Tx" SG_ 140 CcAslButtnResDecPress3 1;
BA_ "U_T6_MCA_MY2020_Tx" SG_ 140 CcAslButtnResDecPress3 1;
BA_ "GenSigSendType" SG_ 140 CcAslButtnResDecPress3 3;
BA_ "U_U55X_MY2022_Tx" SG_ 140 CcAslButtnOnPress3 1;
BA_ "U_T6_MCA_MY2020_Tx" SG_ 140 CcAslButtnOnPress3 1;
BA_ "GenSigSendType" SG_ 140 CcAslButtnOnPress3 3;
BA_ "U_U55X_MY2022_Tx" SG_ 140 CcAslButtnOnOffCncl3 1;
BA_ "U_T6_MCA_MY2020_Tx" SG_ 140 CcAslButtnOnOffCncl3 1;
BA_ "GenSigSendType" SG_ 140 CcAslButtnOnOffCncl3 3;
BA_ "U_U55X_MY2022_Tx" SG_ 140 CcAslButtnDeny_B_Actl3 1;
BA_ "U_T6_MCA_MY2020_Tx" SG_ 140 CcAslButtnDeny_B_Actl3 1;
BA_ "GenSigSendType" SG_ 140 CcAslButtnDeny_B_Actl3 3;
BA_ "U_U55X_MY2022_Tx" SG_ 140 CcAslButtnCnclPress3 1;
BA_ "U_T6_MCA_MY2020_Tx" SG_ 140 CcAslButtnCnclPress3 1;
BA_ "GenSigSendType" SG_ 140 CcAslButtnCnclPress3 3;
BA_ "U_U55X_MY2022_Tx" SG_ 140 AslButtnOnOffPress3 1;
BA_ "U_T6_MCA_MY2020_Tx" SG_ 140 AslButtnOnOffPress3 1;
BA_ "GenSigSendType" SG_ 140 AslButtnOnOffPress3 3;
BA_ "U_U55X_MY2022_Tx" SG_ 140 AslButtnOnOffCnclPress2 1;
BA_ "U_T6_MCA_MY2020_Tx" SG_ 140 AslButtnOnOffCnclPress2 1;
BA_ "GenSigSendType" SG_ 140 AslButtnOnOffCnclPress2 3;
BA_ "U_U55X_MY2022_Tx" SG_ 546 PrplSnd_D_Rq 1;
BA_ "U_CD542_MY2021_Tx" SG_ 546 PrplSnd_D_Rq 1;
BA_ "U_T6_MCA_MY2020_Tx" SG_ 546 PrplSnd_D_Rq 1;
BA_ "U_U55X_MY2022_Rx" SG_ 546 PrplSnd_D_Rq 1;
BA_ "U_T6_MCA_MY2020_Rx" SG_ 546 PrplSnd_D_Rq 1;
BA_ "GenSigSendType" SG_ 546 PrplSnd_D_Rq 3;
BA_ "U_CD764_MY2022_Tx" SG_ 546 SYNC_New_Attn_Event 1;
BA_ "U_U55X_MY2022_Tx" SG_ 546 SYNC_New_Attn_Event 1;
BA_ "U_CD542_MY2021_Tx" SG_ 546 SYNC_New_Attn_Event 1;
BA_ "U_T6_MCA_MY2020_Tx" SG_ 546 SYNC_New_Attn_Event 1;
BA_ "U_P702_MY2021_Tx" SG_ 546 SYNC_New_Attn_Event 1;
BA_ "U_CD764_MY2022_Rx" SG_ 546 SYNC_New_Attn_Event 1;
BA_ "U_U55X_MY2022_Rx" SG_ 546 SYNC_New_Attn_Event 1;
BA_ "U_CD542_MY2021_Rx" SG_ 546 SYNC_New_Attn_Event 1;
BA_ "U_T6_MCA_MY2020_Rx" SG_ 546 SYNC_New_Attn_Event 1;
BA_ "U_P702_MY2021_Rx" SG_ 546 SYNC_New_Attn_Event 1;
BA_ "GenSigSendType" SG_ 546 SYNC_New_Attn_Event 3;
BA_ "U_CD764_MY2022_Tx" SG_ 546 SYNC_Attn_Info_Audio 1;
BA_ "U_U55X_MY2022_Tx" SG_ 546 SYNC_Attn_Info_Audio 1;
BA_ "U_CD542_MY2021_Tx" SG_ 546 SYNC_Attn_Info_Audio 1;
BA_ "U_T6_MCA_MY2020_Tx" SG_ 546 SYNC_Attn_Info_Audio 1;
BA_ "U_P702_MY2021_Tx" SG_ 546 SYNC_Attn_Info_Audio 1;
BA_ "U_CD764_MY2022_Rx" SG_ 546 SYNC_Attn_Info_Audio 1;
BA_ "U_U55X_MY2022_Rx" SG_ 546 SYNC_Attn_Info_Audio 1;
BA_ "U_CD542_MY2021_Rx" SG_ 546 SYNC_Attn_Info_Audio 1;
BA_ "U_T6_MCA_MY2020_Rx" SG_ 546 SYNC_Attn_Info_Audio 1;
BA_ "U_P702_MY2021_Rx" SG_ 546 SYNC_Attn_Info_Audio 1;
BA_ "GenSigSendType" SG_ 546 SYNC_Attn_Info_Audio 3;
BA_ "U_CD764_MY2022_Tx" SG_ 546 Prompt_Directionality 1;
BA_ "U_U55X_MY2022_Tx" SG_ 546 Prompt_Directionality 1;
BA_ "U_CD542_MY2021_Tx" SG_ 546 Prompt_Directionality 1;
BA_ "U_T6_MCA_MY2020_Tx" SG_ 546 Prompt_Directionality 1;
BA_ "U_P702_MY2021_Tx" SG_ 546 Prompt_Directionality 1;
BA_ "U_CD764_MY2022_Rx" SG_ 546 Prompt_Directionality 1;
BA_ "U_U55X_MY2022_Rx" SG_ 546 Prompt_Directionality 1;
BA_ "U_CD542_MY2021_Rx" SG_ 546 Prompt_Directionality 1;
BA_ "U_T6_MCA_MY2020_Rx" SG_ 546 Prompt_Directionality 1;
BA_ "U_P702_MY2021_Rx" SG_ 546 Prompt_Directionality 1;
BA_ "GenSigSendType" SG_ 546 Prompt_Directionality 3;
BA_ "U_CD764_MY2022_Tx" SG_ 546 Audible_Beep 1;
BA_ "U_U55X_MY2022_Tx" SG_ 546 Audible_Beep 1;
BA_ "U_CD542_MY2021_Tx" SG_ 546 Audible_Beep 1;
BA_ "U_T6_MCA_MY2020_Tx" SG_ 546 Audible_Beep 1;
BA_ "U_P702_MY2021_Tx" SG_ 546 Audible_Beep 1;
BA_ "U_CD764_MY2022_Rx" SG_ 546 Audible_Beep 1;
BA_ "U_U55X_MY2022_Rx" SG_ 546 Audible_Beep 1;
BA_ "U_CD542_MY2021_Rx" SG_ 546 Audible_Beep 1;
BA_ "U_T6_MCA_MY2020_Rx" SG_ 546 Audible_Beep 1;
BA_ "U_P702_MY2021_Rx" SG_ 546 Audible_Beep 1;
BA_ "GenSigSendType" SG_ 546 Audible_Beep 3;
BA_ "U_CD764_MY2022_Tx" SG_ 546 Alert_Chan 1;
BA_ "U_U55X_MY2022_Tx" SG_ 546 Alert_Chan 1;
BA_ "U_CD542_MY2021_Tx" SG_ 546 Alert_Chan 1;
BA_ "U_T6_MCA_MY2020_Tx" SG_ 546 Alert_Chan 1;
BA_ "U_P702_MY2021_Tx" SG_ 546 Alert_Chan 1;
BA_ "U_CD764_MY2022_Rx" SG_ 546 Alert_Chan 1;
BA_ "U_U55X_MY2022_Rx" SG_ 546 Alert_Chan 1;
BA_ "U_CD542_MY2021_Rx" SG_ 546 Alert_Chan 1;
BA_ "U_T6_MCA_MY2020_Rx" SG_ 546 Alert_Chan 1;
BA_ "U_P702_MY2021_Rx" SG_ 546 Alert_Chan 1;
BA_ "GenSigSendType" SG_ 546 Alert_Chan 3;
BA_ "U_T6_MCA_MY2020_Rx" SG_ 1186 AwdDrvMde_D2_Stat 1;
BA_ "U_CD764_MY2022_Rx" SG_ 1186 FrontDiffLckLamp_D_Rq 1;
BA_ "U_U55X_MY2022_Rx" SG_ 1186 FrontDiffLckLamp_D_Rq 1;
BA_ "U_T6_MCA_MY2020_Rx" SG_ 1186 FrontDiffLckLamp_D_Rq 1;
BA_ "U_T6_MCA_MY2020_Rx" SG_ 1186 FrontDiffLckMsg_D_Rq 1;
BA_ "U_T6_MCA_MY2020_Rx" SG_ 1186 AwdStat2_D_RqDsply 1;
BA_ "U_CD764_MY2022_Rx" SG_ 1186 RearDiffLckLamp_D_Rq 1;
BA_ "U_CD542_MY2021_Rx" SG_ 1186 RearDiffLckLamp_D_Rq 1;
BA_ "U_P702_MY2021_Rx" SG_ 1186 RearDiffLckLamp_D_Rq 1;
BA_ "U_U55X_MY2022_Rx" SG_ 1186 RearDiffLckLamp_D_Rq 1;
BA_ "U_T6_MCA_MY2020_Rx" SG_ 1186 RearDiffLckLamp_D_Rq 1;
BA_ "GenSigStartValue" SG_ 1186 FrontDiffLck_Tq_Actl 16382;
BA_ "GenSigStartValue" SG_ 1186 SelDrvMdeAwd2_D_Stat 31;
BA_ "GenSigStartValueInteger" SG_ 1186 SelDrvMdeAwd2_D_Stat 31;
BA_ "U_U55X_MY2022_Rx" SG_ 1186 RearDiffLckMsg_D_Rq 1;
BA_ "U_T6_MCA_MY2020_Rx" SG_ 1186 RearDiffLckMsg_D_Rq 1;
BA_ "U_P702_MY2021_Rx" SG_ 1186 RearDiffLckMsg_D_Rq 1;
BA_ "U_U55X_MY2022_Rx" SG_ 1186 LsdSrvcRqd_B_Rq 1;
BA_ "U_CD542_MY2021_Rx" SG_ 1186 LsdSrvcRqd_B_Rq 1;
BA_ "U_T6_MCA_MY2020_Rx" SG_ 1186 LsdSrvcRqd_B_Rq 1;
BA_ "U_P702_MY2021_Rx" SG_ 1186 LsdSrvcRqd_B_Rq 1;
BA_ "U_CD764_MY2022_Rx" SG_ 1130 DrvSlipCtlOffLamp_D_Rq_UB 1;
BA_ "U_U55X_MY2022_Rx" SG_ 1130 DrvSlipCtlOffLamp_D_Rq_UB 1;
BA_ "U_CD542_MY2021_Rx" SG_ 1130 DrvSlipCtlOffLamp_D_Rq_UB 1;
BA_ "U_T6_MCA_MY2020_Rx" SG_ 1130 DrvSlipCtlOffLamp_D_Rq_UB 1;
BA_ "U_P702_MY2021_Rx" SG_ 1130 DrvSlipCtlOffLamp_D_Rq_UB 1;
BA_ "U_CD764_MY2022_Rx" SG_ 1130 DrvSlipCtlMdeMsg_D_Rq_UB 1;
BA_ "U_U55X_MY2022_Rx" SG_ 1130 DrvSlipCtlMdeMsg_D_Rq_UB 1;
BA_ "U_CD542_MY2021_Rx" SG_ 1130 DrvSlipCtlMdeMsg_D_Rq_UB 1;
BA_ "U_T6_MCA_MY2020_Rx" SG_ 1130 DrvSlipCtlMdeMsg_D_Rq_UB 1;
BA_ "U_P702_MY2021_Rx" SG_ 1130 DrvSlipCtlMdeMsg_D_Rq_UB 1;
BA_ "U_CD764_MY2022_Rx" SG_ 1130 DrvSlipCtlOffLamp_D_Rq 1;
BA_ "U_U55X_MY2022_Rx" SG_ 1130 DrvSlipCtlOffLamp_D_Rq 1;
BA_ "U_CD542_MY2021_Rx" SG_ 1130 DrvSlipCtlOffLamp_D_Rq 1;
BA_ "U_T6_MCA_MY2020_Rx" SG_ 1130 DrvSlipCtlOffLamp_D_Rq 1;
BA_ "U_P702_MY2021_Rx" SG_ 1130 DrvSlipCtlOffLamp_D_Rq 1;
BA_ "GenSigSendType" SG_ 1130 DrvSlipCtlOffLamp_D_Rq 3;
BA_ "U_CD764_MY2022_Rx" SG_ 1130 DrvSlipCtlMdeMsg_D_Rq 1;
BA_ "U_U55X_MY2022_Rx" SG_ 1130 DrvSlipCtlMdeMsg_D_Rq 1;
BA_ "U_CD542_MY2021_Rx" SG_ 1130 DrvSlipCtlMdeMsg_D_Rq 1;
BA_ "U_T6_MCA_MY2020_Rx" SG_ 1130 DrvSlipCtlMdeMsg_D_Rq 1;
BA_ "U_P702_MY2021_Rx" SG_ 1130 DrvSlipCtlMdeMsg_D_Rq 1;
BA_ "GenSigSendType" SG_ 1130 DrvSlipCtlMdeMsg_D_Rq 3;
BA_ "U_CD764_MY2022_Rx" SG_ 1130 HtrnWarnLamp_B_Dsply_UB 1;
BA_ "U_U55X_MY2022_Rx" SG_ 1130 HtrnWarnLamp_B_Dsply_UB 1;
BA_ "U_T6_MCA_MY2020_Rx" SG_ 1130 HtrnWarnLamp_B_Dsply_UB 1;
BA_ "U_P702_MY2021_Rx" SG_ 1130 HtrnWarnLamp_B_Dsply_UB 1;
BA_ "U_CD764_MY2022_Rx" SG_ 1130 HtrnWarnLamp_B_Dsply 1;
BA_ "U_U55X_MY2022_Rx" SG_ 1130 HtrnWarnLamp_B_Dsply 1;
BA_ "U_CD542_MY2021_Rx" SG_ 1130 HtrnWarnLamp_B_Dsply 1;
BA_ "U_T6_MCA_MY2020_Rx" SG_ 1130 HtrnWarnLamp_B_Dsply 1;
BA_ "U_P702_MY2021_Rx" SG_ 1130 HtrnWarnLamp_B_Dsply 1;
BA_ "GenSigSendType" SG_ 1130 HtrnWarnLamp_B_Dsply 3;
BA_ "U_CD764_MY2022_Rx" SG_ 1130 HtrnSrvcRqd_B_Dsply_UB 1;
BA_ "U_U55X_MY2022_Rx" SG_ 1130 HtrnSrvcRqd_B_Dsply_UB 1;
BA_ "U_CD542_MY2021_Rx" SG_ 1130 HtrnSrvcRqd_B_Dsply_UB 1;
BA_ "U_T6_MCA_MY2020_Rx" SG_ 1130 HtrnSrvcRqd_B_Dsply_UB 1;
BA_ "U_P702_MY2021_Rx" SG_ 1130 HtrnSrvcRqd_B_Dsply_UB 1;
BA_ "U_CD764_MY2022_Rx" SG_ 1130 HtrnSrvcRqd_B_Dsply 1;
BA_ "U_U55X_MY2022_Rx" SG_ 1130 HtrnSrvcRqd_B_Dsply 1;
BA_ "U_CD542_MY2021_Rx" SG_ 1130 HtrnSrvcRqd_B_Dsply 1;
BA_ "U_T6_MCA_MY2020_Rx" SG_ 1130 HtrnSrvcRqd_B_Dsply 1;
BA_ "U_P702_MY2021_Rx" SG_ 1130 HtrnSrvcRqd_B_Dsply 1;
BA_ "GenSigSendType" SG_ 1130 HtrnSrvcRqd_B_Dsply 3;
BA_ "U_CD764_MY2022_Rx" SG_ 1130 ChrgrSrvcRqd_B_Rq_UB 1;
BA_ "U_T6_MCA_MY2020_Rx" SG_ 1130 ChrgrSrvcRqd_B_Rq_UB 1;
BA_ "U_P702_MY2021_Rx" SG_ 1130 ChrgrSrvcRqd_B_Rq_UB 1;
BA_ "U_CD764_MY2022_Rx" SG_ 1130 ChrgrSrvcRqd_B_Rq 1;
BA_ "U_CD542_MY2021_Rx" SG_ 1130 ChrgrSrvcRqd_B_Rq 1;
BA_ "U_T6_MCA_MY2020_Rx" SG_ 1130 ChrgrSrvcRqd_B_Rq 1;
BA_ "U_P702_MY2021_Rx" SG_ 1130 ChrgrSrvcRqd_B_Rq 1;
BA_ "GenSigSendType" SG_ 1130 ChrgrSrvcRqd_B_Rq 3;
BA_ "U_CD764_MY2022_Rx" SG_ 1130 BattTracSrvcRqd_B_Rq_UB 1;
BA_ "U_CD542_MY2021_Rx" SG_ 1130 BattTracSrvcRqd_B_Rq_UB 1;
BA_ "U_P702_MY2021_Rx" SG_ 1130 BattTracSrvcRqd_B_Rq_UB 1;
BA_ "U_CD764_MY2022_Rx" SG_ 1130 BattTracSrvcRqd_B_Rq 1;
BA_ "U_CD542_MY2021_Rx" SG_ 1130 BattTracSrvcRqd_B_Rq 1;
BA_ "U_T6_MCA_MY2020_Rx" SG_ 1130 BattTracSrvcRqd_B_Rq 1;
BA_ "U_P702_MY2021_Rx" SG_ 1130 BattTracSrvcRqd_B_Rq 1;
BA_ "GenSigSendType" SG_ 1130 BattTracSrvcRqd_B_Rq 3;
BA_ "U_CD764_MY2022_Rx" SG_ 1130 BrkPadMsgTxt_D_Rq_UB 1;
BA_ "U_T6_MCA_MY2020_Rx" SG_ 1130 BrkPadMsgTxt_D_Rq_UB 1;
BA_ "U_CD764_MY2022_Rx" SG_ 1130 BrkPadMsgTxt_D_Rq 1;
BA_ "U_T6_MCA_MY2020_Rx" SG_ 1130 BrkPadMsgTxt_D_Rq 1;
BA_ "GenSigSendType" SG_ 1130 BrkPadMsgTxt_D_Rq 3;
BA_ "U_CD764_MY2022_Rx" SG_ 1130 SuspDrvMde_D_Stat 1;
BA_ "U_T6_MCA_MY2020_Rx" SG_ 1130 SuspDrvMde_D_Stat 1;
BA_ "U_CD764_MY2022_Rx" SG_ 1130 SuspDrvMde_D_Stat_UB 1;
BA_ "U_T6_MCA_MY2020_Rx" SG_ 1130 SuspDrvMde_D_Stat_UB 1;
BA_ "U_T6_MCA_MY2020_Rx" SG_ 1042 TrlrAnCalib_Pc_Actl 1;
BA_ "U_CD542_MY2021_Rx" SG_ 1042 VehRol_An_Dsply_UB 1;
BA_ "U_U55X_MY2022_Rx" SG_ 1042 VehRol_An_Dsply_UB 1;
BA_ "U_T6_MCA_MY2020_Rx" SG_ 1042 VehRol_An_Dsply_UB 1;
BA_ "U_P702_MY2021_Rx" SG_ 1042 VehRol_An_Dsply_UB 1;
BA_ "U_CD542_MY2021_Rx" SG_ 1042 VehPtch_An_Dsply_UB 1;
BA_ "U_U55X_MY2022_Rx" SG_ 1042 VehPtch_An_Dsply_UB 1;
BA_ "U_T6_MCA_MY2020_Rx" SG_ 1042 VehPtch_An_Dsply_UB 1;
BA_ "U_P702_MY2021_Rx" SG_ 1042 VehPtch_An_Dsply_UB 1;
BA_ "U_CD542_MY2021_Rx" SG_ 1042 VehRol_An_Dsply 1;
BA_ "U_U55X_MY2022_Rx" SG_ 1042 VehRol_An_Dsply 1;
BA_ "U_T6_MCA_MY2020_Rx" SG_ 1042 VehRol_An_Dsply 1;
BA_ "U_P702_MY2021_Rx" SG_ 1042 VehRol_An_Dsply 1;
BA_ "GenSigStartValueInteger" SG_ 1042 VehRol_An_Dsply 64;
BA_ "U_CD542_MY2021_Rx" SG_ 1042 VehPtch_An_Dsply 1;
BA_ "U_U55X_MY2022_Rx" SG_ 1042 VehPtch_An_Dsply 1;
BA_ "U_T6_MCA_MY2020_Rx" SG_ 1042 VehPtch_An_Dsply 1;
BA_ "U_P702_MY2021_Rx" SG_ 1042 VehPtch_An_Dsply 1;
BA_ "GenSigStartValueInteger" SG_ 1042 VehPtch_An_Dsply 64;
BA_ "U_U55X_MY2022_Rx" SG_ 1042 TrlrBrk_Pc_Rq_UB 1;
BA_ "U_P702_MY2021_Rx" SG_ 1042 TrlrBrk_Pc_Rq_UB 1;
BA_ "U_T6_MCA_MY2020_Rx" SG_ 1042 TrlrBrk_Pc_Rq_UB 1;
BA_ "U_U55X_MY2022_Rx" SG_ 1042 TrlrBrk_Pc_Rq 1;
BA_ "U_P702_MY2021_Rx" SG_ 1042 TrlrBrk_Pc_Rq 1;
BA_ "U_T6_MCA_MY2020_Rx" SG_ 1042 TrlrBrk_Pc_Rq 1;
BA_ "U_CD542_MY2021_Rx" SG_ 1042 VehYaw_W_Actl_UB 1;
BA_ "U_T6_MCA_MY2020_Rx" SG_ 1042 VehYaw_W_Actl_UB 1;
BA_ "U_P702_MY2021_Rx" SG_ 1042 VehYaw_W_Actl_UB 1;
BA_ "U_CD542_MY2021_Rx" SG_ 1042 VehYaw_W_Actl 1;
BA_ "U_T6_MCA_MY2020_Rx" SG_ 1042 VehYaw_W_Actl 1;
BA_ "U_P702_MY2021_Rx" SG_ 1042 VehYaw_W_Actl 1;
BA_ "GenSigStartValue" SG_ 1042 VehYaw_W_Actl 65534;
BA_ "GenSigStartValueInteger" SG_ 1042 VehYaw_W_Actl 65534;
BA_ "U_U55X_MY2022_Tx" SG_ 1093 TrlBrkInitOut_D_Stat 1;
BA_ "U_T6_MCA_MY2020_Tx" SG_ 1093 TrlBrkInitOut_D_Stat 1;
BA_ "U_P702_MY2021_Tx" SG_ 1093 TrlBrkInitOut_D_Stat 1;
BA_ "U_U55X_MY2022_Rx" SG_ 1093 TrlBrkInitOut_D_Stat 1;
BA_ "U_T6_MCA_MY2020_Rx" SG_ 1093 TrlBrkInitOut_D_Stat 1;
BA_ "U_P702_MY2021_Rx" SG_ 1093 TrlBrkInitOut_D_Stat 1;
BA_ "U_U55X_MY2022_Tx" SG_ 1093 TrlrBrkOut_No_Dsply 1;
BA_ "U_T6_MCA_MY2020_Tx" SG_ 1093 TrlrBrkOut_No_Dsply 1;
BA_ "U_P702_MY2021_Tx" SG_ 1093 TrlrBrkOut_No_Dsply 1;
BA_ "U_U55X_MY2022_Rx" SG_ 1093 TrlrBrkOut_No_Dsply 1;
BA_ "U_T6_MCA_MY2020_Rx" SG_ 1093 TrlrBrkOut_No_Dsply 1;
BA_ "U_P702_MY2021_Rx" SG_ 1093 TrlrBrkOut_No_Dsply 1;
BA_ "U_U55X_MY2022_Tx" SG_ 1093 TrlrBrkMde_D_Actl 1;
BA_ "U_T6_MCA_MY2020_Tx" SG_ 1093 TrlrBrkMde_D_Actl 1;
BA_ "U_P702_MY2021_Tx" SG_ 1093 TrlrBrkMde_D_Actl 1;
BA_ "U_U55X_MY2022_Rx" SG_ 1093 TrlrBrkMde_D_Actl 1;
BA_ "U_T6_MCA_MY2020_Rx" SG_ 1093 TrlrBrkMde_D_Actl 1;
BA_ "U_P702_MY2021_Rx" SG_ 1093 TrlrBrkMde_D_Actl 1;
BA_ "U_U55X_MY2022_Tx" SG_ 1093 TrlrBrkGain_No_Actl 1;
BA_ "U_T6_MCA_MY2020_Tx" SG_ 1093 TrlrBrkGain_No_Actl 1;
BA_ "U_P702_MY2021_Tx" SG_ 1093 TrlrBrkGain_No_Actl 1;
BA_ "U_CD542_MY2021_Rx" SG_ 1093 TrlrBrkGain_No_Actl 1;
BA_ "U_U55X_MY2022_Rx" SG_ 1093 TrlrBrkGain_No_Actl 1;
BA_ "U_T6_MCA_MY2020_Rx" SG_ 1093 TrlrBrkGain_No_Actl 1;
BA_ "U_P702_MY2021_Rx" SG_ 1093 TrlrBrkGain_No_Actl 1;
BA_ "U_U55X_MY2022_Tx" SG_ 1093 TrlrBrkDsply_B_Rq 1;
BA_ "U_T6_MCA_MY2020_Tx" SG_ 1093 TrlrBrkDsply_B_Rq 1;
BA_ "U_P702_MY2021_Tx" SG_ 1093 TrlrBrkDsply_B_Rq 1;
BA_ "U_U55X_MY2022_Rx" SG_ 1093 TrlrBrkDsply_B_Rq 1;
BA_ "U_T6_MCA_MY2020_Rx" SG_ 1093 TrlrBrkDsply_B_Rq 1;
BA_ "U_P702_MY2021_Rx" SG_ 1093 TrlrBrkDsply_B_Rq 1;
BA_ "U_U55X_MY2022_Tx" SG_ 1093 TrlrBrkDcnnt_B_Actl 1;
BA_ "U_T6_MCA_MY2020_Tx" SG_ 1093 TrlrBrkDcnnt_B_Actl 1;
BA_ "U_P702_MY2021_Tx" SG_ 1093 TrlrBrkDcnnt_B_Actl 1;
BA_ "U_U55X_MY2022_Rx" SG_ 1093 TrlrBrkDcnnt_B_Actl 1;
BA_ "U_T6_MCA_MY2020_Rx" SG_ 1093 TrlrBrkDcnnt_B_Actl 1;
BA_ "U_P702_MY2021_Rx" SG_ 1093 TrlrBrkDcnnt_B_Actl 1;
BA_ "U_U55X_MY2022_Tx" SG_ 1093 TrlrBrkActCnnct_B_Actl 1;
BA_ "U_T6_MCA_MY2020_Tx" SG_ 1093 TrlrBrkActCnnct_B_Actl 1;
BA_ "U_P702_MY2021_Tx" SG_ 1093 TrlrBrkActCnnct_B_Actl 1;
BA_ "U_CD764_MY2022_Rx" SG_ 1093 TrlrBrkActCnnct_B_Actl 1;
BA_ "U_CD542_MY2021_Rx" SG_ 1093 TrlrBrkActCnnct_B_Actl 1;
BA_ "U_U55X_MY2022_Rx" SG_ 1093 TrlrBrkActCnnct_B_Actl 1;
BA_ "U_T6_MCA_MY2020_Rx" SG_ 1093 TrlrBrkActCnnct_B_Actl 1;
BA_ "U_P702_MY2021_Rx" SG_ 1093 TrlrBrkActCnnct_B_Actl 1;
BA_ "U_U55X_MY2022_Tx" SG_ 1093 StopLamp_B_RqTrlrBrk 1;
BA_ "U_T6_MCA_MY2020_Tx" SG_ 1093 StopLamp_B_RqTrlrBrk 1;
BA_ "U_P702_MY2021_Tx" SG_ 1093 StopLamp_B_RqTrlrBrk 1;
BA_ "ContentDependant" SG_ 1093 StopLamp_B_RqTrlrBrk 1;
BA_ "U_U55X_MY2022_Tx" SG_ 1093 TrlrBrkCtl_B_Falt 1;
BA_ "U_T6_MCA_MY2020_Tx" SG_ 1093 TrlrBrkCtl_B_Falt 1;
BA_ "U_P702_MY2021_Tx" SG_ 1093 TrlrBrkCtl_B_Falt 1;
BA_ "U_U55X_MY2022_Rx" SG_ 1093 TrlrBrkCtl_B_Falt 1;
BA_ "U_T6_MCA_MY2020_Rx" SG_ 1093 TrlrBrkCtl_B_Falt 1;
BA_ "U_P702_MY2021_Rx" SG_ 1093 TrlrBrkCtl_B_Falt 1;
BA_ "U_U55X_MY2022_Tx" SG_ 1093 TrlrBrkActCirct_B_Falt 1;
BA_ "U_T6_MCA_MY2020_Tx" SG_ 1093 TrlrBrkActCirct_B_Falt 1;
BA_ "U_P702_MY2021_Tx" SG_ 1093 TrlrBrkActCirct_B_Falt 1;
BA_ "U_U55X_MY2022_Rx" SG_ 1093 TrlrBrkActCirct_B_Falt 1;
BA_ "U_T6_MCA_MY2020_Rx" SG_ 1093 TrlrBrkActCirct_B_Falt 1;
BA_ "U_P702_MY2021_Rx" SG_ 1093 TrlrBrkActCirct_B_Falt 1;
BA_ "U_CD764_MY2022_Rx" SG_ 1138 ActChrgEndYr_No2_Actl 1;
BA_ "U_U55X_MY2022_Rx" SG_ 1138 ActChrgEndYr_No2_Actl 1;
BA_ "U_CD542_MY2021_Rx" SG_ 1138 ActChrgEndYr_No2_Actl 1;
BA_ "U_T6_MCA_MY2020_Rx" SG_ 1138 ActChrgEndYr_No2_Actl 1;
BA_ "U_CD542_MY2021_Rx" SG_ 1138 BattChrgTrgtLMin_T_Est 1;
BA_ "U_U55X_MY2022_Rx" SG_ 1138 BattChrgTrgtLMin_T_Est 1;
BA_ "U_T6_MCA_MY2020_Rx" SG_ 1138 BattChrgTrgtLMin_T_Est 1;
BA_ "U_P702_MY2021_Rx" SG_ 1138 BattChrgTrgtLMin_T_Est 1;
BA_ "U_CD542_MY2021_Rx" SG_ 1138 ActChrgEndYr_No_Actl 1;
BA_ "U_U55X_MY2022_Rx" SG_ 1138 ActChrgEndYr_No_Actl 1;
BA_ "U_T6_MCA_MY2020_Rx" SG_ 1138 ActChrgEndYr_No_Actl 1;
BA_ "U_P702_MY2021_Rx" SG_ 1138 ActChrgEndYr_No_Actl 1;
BA_ "U_CD764_MY2022_Rx" SG_ 1138 ActChrgEndMnth_No_Actl 1;
BA_ "U_CD542_MY2021_Rx" SG_ 1138 ActChrgEndMnth_No_Actl 1;
BA_ "U_U55X_MY2022_Rx" SG_ 1138 ActChrgEndMnth_No_Actl 1;
BA_ "U_T6_MCA_MY2020_Rx" SG_ 1138 ActChrgEndMnth_No_Actl 1;
BA_ "U_P702_MY2021_Rx" SG_ 1138 ActChrgEndMnth_No_Actl 1;
BA_ "GenSigStartValue" SG_ 1138 ActChrgEndMnth_No_Actl 1;
BA_ "GenSigStartValueInteger" SG_ 1138 ActChrgEndMnth_No_Actl 1;
BA_ "U_CD764_MY2022_Rx" SG_ 1138 ActChrgEndMin_No_Actl 1;
BA_ "U_CD542_MY2021_Rx" SG_ 1138 ActChrgEndMin_No_Actl 1;
BA_ "U_U55X_MY2022_Rx" SG_ 1138 ActChrgEndMin_No_Actl 1;
BA_ "U_T6_MCA_MY2020_Rx" SG_ 1138 ActChrgEndMin_No_Actl 1;
BA_ "U_P702_MY2021_Rx" SG_ 1138 ActChrgEndMin_No_Actl 1;
BA_ "U_CD764_MY2022_Rx" SG_ 1138 ActChrgEndHr_No_Actl 1;
BA_ "U_CD542_MY2021_Rx" SG_ 1138 ActChrgEndHr_No_Actl 1;
BA_ "U_U55X_MY2022_Rx" SG_ 1138 ActChrgEndHr_No_Actl 1;
BA_ "U_T6_MCA_MY2020_Rx" SG_ 1138 ActChrgEndHr_No_Actl 1;
BA_ "U_P702_MY2021_Rx" SG_ 1138 ActChrgEndHr_No_Actl 1;
BA_ "U_CD764_MY2022_Rx" SG_ 1138 ActChrgEndDay_No_Actl 1;
BA_ "U_CD542_MY2021_Rx" SG_ 1138 ActChrgEndDay_No_Actl 1;
BA_ "U_U55X_MY2022_Rx" SG_ 1138 ActChrgEndDay_No_Actl 1;
BA_ "U_T6_MCA_MY2020_Rx" SG_ 1138 ActChrgEndDay_No_Actl 1;
BA_ "U_P702_MY2021_Rx" SG_ 1138 ActChrgEndDay_No_Actl 1;
BA_ "GenSigStartValue" SG_ 1138 ActChrgEndDay_No_Actl 1;
BA_ "GenSigStartValueInteger" SG_ 1138 ActChrgEndDay_No_Actl 1;
BA_ "U_CD764_MY2022_Rx" SG_ 1139 ActChrgStrtYr_No2_Actl 1;
BA_ "U_U55X_MY2022_Rx" SG_ 1139 ActChrgStrtYr_No2_Actl 1;
BA_ "U_CD542_MY2021_Rx" SG_ 1139 ActChrgStrtYr_No2_Actl 1;
BA_ "U_T6_MCA_MY2020_Rx" SG_ 1139 ActChrgStrtYr_No2_Actl 1;
BA_ "U_CD542_MY2021_Rx" SG_ 1139 BattChrgTrgtLMax_T_Est 1;
BA_ "U_U55X_MY2022_Rx" SG_ 1139 BattChrgTrgtLMax_T_Est 1;
BA_ "U_T6_MCA_MY2020_Rx" SG_ 1139 BattChrgTrgtLMax_T_Est 1;
BA_ "U_P702_MY2021_Rx" SG_ 1139 BattChrgTrgtLMax_T_Est 1;
BA_ "U_CD542_MY2021_Rx" SG_ 1139 ActChrgStrtYr_No_Actl 1;
BA_ "U_U55X_MY2022_Rx" SG_ 1139 ActChrgStrtYr_No_Actl 1;
BA_ "U_T6_MCA_MY2020_Rx" SG_ 1139 ActChrgStrtYr_No_Actl 1;
BA_ "U_P702_MY2021_Rx" SG_ 1139 ActChrgStrtYr_No_Actl 1;
BA_ "U_CD764_MY2022_Rx" SG_ 1139 ActChrgStrtMin_No_Actl 1;
BA_ "U_CD542_MY2021_Rx" SG_ 1139 ActChrgStrtMin_No_Actl 1;
BA_ "U_U55X_MY2022_Rx" SG_ 1139 ActChrgStrtMin_No_Actl 1;
BA_ "U_T6_MCA_MY2020_Rx" SG_ 1139 ActChrgStrtMin_No_Actl 1;
BA_ "U_P702_MY2021_Rx" SG_ 1139 ActChrgStrtMin_No_Actl 1;
BA_ "U_CD542_MY2021_Rx" SG_ 1139 ActChrgStrtHr_No_Actl 1;
BA_ "U_CD764_MY2022_Rx" SG_ 1139 ActChrgStrtHr_No_Actl 1;
BA_ "U_U55X_MY2022_Rx" SG_ 1139 ActChrgStrtHr_No_Actl 1;
BA_ "U_T6_MCA_MY2020_Rx" SG_ 1139 ActChrgStrtHr_No_Actl 1;
BA_ "U_P702_MY2021_Rx" SG_ 1139 ActChrgStrtHr_No_Actl 1;
BA_ "U_CD764_MY2022_Rx" SG_ 1139 ActChrgStrtDay_No_Actl 1;
BA_ "U_CD542_MY2021_Rx" SG_ 1139 ActChrgStrtDay_No_Actl 1;
BA_ "U_U55X_MY2022_Rx" SG_ 1139 ActChrgStrtDay_No_Actl 1;
BA_ "U_T6_MCA_MY2020_Rx" SG_ 1139 ActChrgStrtDay_No_Actl 1;
BA_ "U_P702_MY2021_Rx" SG_ 1139 ActChrgStrtDay_No_Actl 1;
BA_ "GenSigStartValue" SG_ 1139 ActChrgStrtDay_No_Actl 1;
BA_ "GenSigStartValueInteger" SG_ 1139 ActChrgStrtDay_No_Actl 1;
BA_ "U_CD764_MY2022_Rx" SG_ 1139 ActChrgStrMnth_No_Actl 1;
BA_ "U_CD542_MY2021_Rx" SG_ 1139 ActChrgStrMnth_No_Actl 1;
BA_ "U_U55X_MY2022_Rx" SG_ 1139 ActChrgStrMnth_No_Actl 1;
BA_ "U_T6_MCA_MY2020_Rx" SG_ 1139 ActChrgStrMnth_No_Actl 1;
BA_ "U_P702_MY2021_Rx" SG_ 1139 ActChrgStrMnth_No_Actl 1;
BA_ "GenSigStartValue" SG_ 1139 ActChrgStrMnth_No_Actl 1;
BA_ "GenSigStartValueInteger" SG_ 1139 ActChrgStrMnth_No_Actl 1;
BA_ "U_U55X_MY2022_Rx" SG_ 1145 EstmChrgTimeLP_St 1;
BA_ "U_CD542_MY2021_Rx" SG_ 1145 EstmChrgTimeLP_St 1;
BA_ "U_T6_MCA_MY2020_Rx" SG_ 1145 EstmChrgTimeLP_St 1;
BA_ "U_P702_MY2021_Rx" SG_ 1145 EstmChrgTimeLP_St 1;
BA_ "U_U55X_MY2022_Rx" SG_ 1145 EstmChrgTimeHP_St 1;
BA_ "U_CD542_MY2021_Rx" SG_ 1145 EstmChrgTimeHP_St 1;
BA_ "U_T6_MCA_MY2020_Rx" SG_ 1145 EstmChrgTimeHP_St 1;
BA_ "U_P702_MY2021_Rx" SG_ 1145 EstmChrgTimeHP_St 1;
BA_ "U_T6_MCA_MY2020_Rx" SG_ 1145 ChargeNowDuration_St 1;
BA_ "U_CD542_MY2021_Rx" SG_ 1145 ChargeNowDuration_St 1;
BA_ "U_U55X_MY2022_Rx" SG_ 1145 ChargeNowDuration_St 1;
BA_ "U_U55X_MY2022_Rx" SG_ 1145 VehElRngeNut_L2_Dsply 1;
BA_ "GenSigStartValue" SG_ 1145 VehElRngeNut_L2_Dsply 8190;
BA_ "U_U55X_MY2022_Rx" SG_ 1145 VehElRngeNut_L_Dsply 1;
BA_ "U_CD542_MY2021_Rx" SG_ 1145 VehElRngeNut_L_Dsply 1;
BA_ "U_T6_MCA_MY2020_Rx" SG_ 1145 VehElRngeNut_L_Dsply 1;
BA_ "U_P702_MY2021_Rx" SG_ 1145 VehElRngeNut_L_Dsply 1;
BA_ "U_U55X_MY2022_Rx" SG_ 1145 NxtUsgSocEst_Pc_Dsply 1;
BA_ "U_CD542_MY2021_Rx" SG_ 1145 NxtUsgSocEst_Pc_Dsply 1;
BA_ "U_T6_MCA_MY2020_Rx" SG_ 1145 NxtUsgSocEst_Pc_Dsply 1;
BA_ "U_P702_MY2021_Rx" SG_ 1145 NxtUsgSocEst_Pc_Dsply 1;
BA_ "U_CD764_MY2022_Tx" SG_ 1232 AHU_EnsembleName_St 1;
BA_ "U_U55X_MY2022_Tx" SG_ 1232 AHU_EnsembleName_St 1;
BA_ "U_CD542_MY2021_Tx" SG_ 1232 AHU_EnsembleName_St 1;
BA_ "U_T6_MCA_MY2020_Tx" SG_ 1232 AHU_EnsembleName_St 1;
BA_ "U_P702_MY2021_Tx" SG_ 1232 AHU_EnsembleName_St 1;
BA_ "U_U55X_MY2022_Rx" SG_ 1232 AHU_EnsembleName_St 1;
BA_ "U_CD542_MY2021_Rx" SG_ 1232 AHU_EnsembleName_St 1;
BA_ "U_T6_MCA_MY2020_Rx" SG_ 1232 AHU_EnsembleName_St 1;
BA_ "U_P702_MY2021_Rx" SG_ 1232 AHU_EnsembleName_St 1;
BA_ "U_CD764_MY2022_Tx" SG_ 1232 AHU_AutoConfigOcc_Shakr 1;
BA_ "U_U55X_MY2022_Tx" SG_ 1232 AHU_AutoConfigOcc_Shakr 1;
BA_ "U_T6_MCA_MY2020_Tx" SG_ 1232 AHU_AutoConfigOcc_Shakr 1;
BA_ "U_P702_MY2021_Tx" SG_ 1232 AHU_AutoConfigOcc_Shakr 1;
BA_ "U_U55X_MY2022_Rx" SG_ 1232 AHU_AutoConfigOcc_Shakr 1;
BA_ "U_CD542_MY2021_Rx" SG_ 1232 AHU_AutoConfigOcc_Shakr 1;
BA_ "U_T6_MCA_MY2020_Rx" SG_ 1232 AHU_AutoConfigOcc_Shakr 1;
BA_ "U_P702_MY2021_Rx" SG_ 1232 AHU_AutoConfigOcc_Shakr 1;
BA_ "U_CD764_MY2022_Tx" SG_ 1232 AHU_AutoConfigOcc_Rear 1;
BA_ "U_U55X_MY2022_Tx" SG_ 1232 AHU_AutoConfigOcc_Rear 1;
BA_ "U_CD542_MY2021_Tx" SG_ 1232 AHU_AutoConfigOcc_Rear 1;
BA_ "U_T6_MCA_MY2020_Tx" SG_ 1232 AHU_AutoConfigOcc_Rear 1;
BA_ "U_P702_MY2021_Tx" SG_ 1232 AHU_AutoConfigOcc_Rear 1;
BA_ "U_U55X_MY2022_Rx" SG_ 1232 AHU_AutoConfigOcc_Rear 1;
BA_ "U_CD542_MY2021_Rx" SG_ 1232 AHU_AutoConfigOcc_Rear 1;
BA_ "U_T6_MCA_MY2020_Rx" SG_ 1232 AHU_AutoConfigOcc_Rear 1;
BA_ "U_P702_MY2021_Rx" SG_ 1232 AHU_AutoConfigOcc_Rear 1;
BA_ "U_CD764_MY2022_Tx" SG_ 1232 AHU_AutoConfigOcc_Front 1;
BA_ "U_U55X_MY2022_Tx" SG_ 1232 AHU_AutoConfigOcc_Front 1;
BA_ "U_CD542_MY2021_Tx" SG_ 1232 AHU_AutoConfigOcc_Front 1;
BA_ "U_T6_MCA_MY2020_Tx" SG_ 1232 AHU_AutoConfigOcc_Front 1;
BA_ "U_P702_MY2021_Tx" SG_ 1232 AHU_AutoConfigOcc_Front 1;
BA_ "U_U55X_MY2022_Rx" SG_ 1232 AHU_AutoConfigOcc_Front 1;
BA_ "U_CD542_MY2021_Rx" SG_ 1232 AHU_AutoConfigOcc_Front 1;
BA_ "U_T6_MCA_MY2020_Rx" SG_ 1232 AHU_AutoConfigOcc_Front 1;
BA_ "U_P702_MY2021_Rx" SG_ 1232 AHU_AutoConfigOcc_Front 1;
BA_ "U_CD764_MY2022_Tx" SG_ 1232 AHU_AutoConfigOcc_Drvr 1;
BA_ "U_U55X_MY2022_Tx" SG_ 1232 AHU_AutoConfigOcc_Drvr 1;
BA_ "U_T6_MCA_MY2020_Tx" SG_ 1232 AHU_AutoConfigOcc_Drvr 1;
BA_ "U_P702_MY2021_Tx" SG_ 1232 AHU_AutoConfigOcc_Drvr 1;
BA_ "U_U55X_MY2022_Rx" SG_ 1232 AHU_AutoConfigOcc_Drvr 1;
BA_ "U_CD542_MY2021_Rx" SG_ 1232 AHU_AutoConfigOcc_Drvr 1;
BA_ "U_T6_MCA_MY2020_Rx" SG_ 1232 AHU_AutoConfigOcc_Drvr 1;
BA_ "U_P702_MY2021_Rx" SG_ 1232 AHU_AutoConfigOcc_Drvr 1;
BA_ "U_CD764_MY2022_Tx" SG_ 1232 AHU_AutoConfigOcc_Cnvrt 1;
BA_ "U_U55X_MY2022_Tx" SG_ 1232 AHU_AutoConfigOcc_Cnvrt 1;
BA_ "U_T6_MCA_MY2020_Tx" SG_ 1232 AHU_AutoConfigOcc_Cnvrt 1;
BA_ "U_P702_MY2021_Tx" SG_ 1232 AHU_AutoConfigOcc_Cnvrt 1;
BA_ "U_U55X_MY2022_Rx" SG_ 1232 AHU_AutoConfigOcc_Cnvrt 1;
BA_ "U_CD542_MY2021_Rx" SG_ 1232 AHU_AutoConfigOcc_Cnvrt 1;
BA_ "U_T6_MCA_MY2020_Rx" SG_ 1232 AHU_AutoConfigOcc_Cnvrt 1;
BA_ "U_P702_MY2021_Rx" SG_ 1232 AHU_AutoConfigOcc_Cnvrt 1;
BA_ "U_CD764_MY2022_Tx" SG_ 1232 AHU_AutoConfigOcc_Allst 1;
BA_ "U_U55X_MY2022_Tx" SG_ 1232 AHU_AutoConfigOcc_Allst 1;
BA_ "U_T6_MCA_MY2020_Tx" SG_ 1232 AHU_AutoConfigOcc_Allst 1;
BA_ "U_P702_MY2021_Tx" SG_ 1232 AHU_AutoConfigOcc_Allst 1;
BA_ "U_U55X_MY2022_Rx" SG_ 1232 AHU_AutoConfigOcc_Allst 1;
BA_ "U_CD542_MY2021_Rx" SG_ 1232 AHU_AutoConfigOcc_Allst 1;
BA_ "U_T6_MCA_MY2020_Rx" SG_ 1232 AHU_AutoConfigOcc_Allst 1;
BA_ "U_P702_MY2021_Rx" SG_ 1232 AHU_AutoConfigOcc_Allst 1;
BA_ "U_CD764_MY2022_Tx" SG_ 1232 ACU_DigitalRadio_St 1;
BA_ "U_U55X_MY2022_Tx" SG_ 1232 ACU_DigitalRadio_St 1;
BA_ "U_CD542_MY2021_Tx" SG_ 1232 ACU_DigitalRadio_St 1;
BA_ "U_T6_MCA_MY2020_Tx" SG_ 1232 ACU_DigitalRadio_St 1;
BA_ "U_P702_MY2021_Tx" SG_ 1232 ACU_DigitalRadio_St 1;
BA_ "U_P702_MY2021_Rx" SG_ 1232 ACU_DigitalRadio_St 1;
BA_ "U_U55X_MY2022_Rx" SG_ 1232 ACU_DigitalRadio_St 1;
BA_ "U_CD542_MY2021_Rx" SG_ 1232 ACU_DigitalRadio_St 1;
BA_ "U_T6_MCA_MY2020_Rx" SG_ 1232 ACU_DigitalRadio_St 1;
BA_ "U_CD764_MY2022_Tx" SG_ 1232 ACU_Configuration 1;
BA_ "U_U55X_MY2022_Tx" SG_ 1232 ACU_Configuration 1;
BA_ "U_CD542_MY2021_Tx" SG_ 1232 ACU_Configuration 1;
BA_ "U_T6_MCA_MY2020_Tx" SG_ 1232 ACU_Configuration 1;
BA_ "U_P702_MY2021_Tx" SG_ 1232 ACU_Configuration 1;
BA_ "U_P702_MY2021_Rx" SG_ 1232 ACU_Configuration 1;
BA_ "U_U55X_MY2022_Rx" SG_ 1232 ACU_Configuration 1;
BA_ "U_CD542_MY2021_Rx" SG_ 1232 ACU_Configuration 1;
BA_ "U_T6_MCA_MY2020_Rx" SG_ 1232 ACU_Configuration 1;
BA_ "U_CD764_MY2022_Tx" SG_ 1232 ACU_MediaPlayer_St 1;
BA_ "U_U55X_MY2022_Tx" SG_ 1232 ACU_MediaPlayer_St 1;
BA_ "U_CD542_MY2021_Tx" SG_ 1232 ACU_MediaPlayer_St 1;
BA_ "U_T6_MCA_MY2020_Tx" SG_ 1232 ACU_MediaPlayer_St 1;
BA_ "U_P702_MY2021_Tx" SG_ 1232 ACU_MediaPlayer_St 1;
BA_ "U_P702_MY2021_Rx" SG_ 1232 ACU_MediaPlayer_St 1;
BA_ "U_U55X_MY2022_Rx" SG_ 1232 ACU_MediaPlayer_St 1;
BA_ "U_CD542_MY2021_Rx" SG_ 1232 ACU_MediaPlayer_St 1;
BA_ "U_T6_MCA_MY2020_Rx" SG_ 1232 ACU_MediaPlayer_St 1;
BA_ "GenSigStartValue" SG_ 1141 WhlPwFront_Pc_Dsply 511;
BA_ "GenSigStartValue" SG_ 1141 WhlPwRear_Pc_Dsply 511;
BA_ "U_T6_MCA_MY2020_Rx" SG_ 1141 AirAmbTePlgIn_D_Dsply 1;
BA_ "GenSigStartValue" SG_ 1141 MtrTrac2_Tq_Actl 4095;
BA_ "GenSigStartValueInteger" SG_ 1141 MtrTrac2_Tq_Actl 4095;
BA_ "U_T6_MCA_MY2020_Rx" SG_ 1141 PtRmtRprt_D_Rq 1;
BA_ "WakeupSignal" SG_ 1141 PtRmtRprt_D_Rq 1;
BA_ "U_T6_MCA_MY2020_Rx" SG_ 1141 PreCondID_No_Rq 1;
BA_ "U_T6_MCA_MY2020_Rx" SG_ 1141 NxtUsg_D_Rq 1;
BA_ "U_U55X_MY2022_Rx" SG_ 1141 NtfctnConflict1_D_Rq 1;
BA_ "U_CD542_MY2021_Rx" SG_ 1141 NtfctnConflict1_D_Rq 1;
BA_ "U_T6_MCA_MY2020_Rx" SG_ 1141 NtfctnConflict1_D_Rq 1;
BA_ "U_P702_MY2021_Rx" SG_ 1141 NtfctnConflict1_D_Rq 1;
BA_ "U_T6_MCA_MY2020_Rx" SG_ 1141 ChrgLocID_No_Rq 1;
BA_ "U_T6_MCA_MY2020_Rx" SG_ 1141 ChrgLocGPS_D_Rq 1;
BA_ "U_U55X_MY2022_Rx" SG_ 1141 OfbChrgSetSync_D_Stat 1;
BA_ "U_CD542_MY2021_Rx" SG_ 1141 OfbChrgSetSync_D_Stat 1;
BA_ "U_T6_MCA_MY2020_Rx" SG_ 1141 OfbChrgSetSync_D_Stat 1;
BA_ "U_CD764_MY2022_Rx" SG_ 631 RearPassWindowPos 1;
BA_ "U_U55X_MY2022_Rx" SG_ 631 RearPassWindowPos 1;
BA_ "U_CD542_MY2021_Rx" SG_ 631 RearPassWindowPos 1;
BA_ "U_T6_MCA_MY2020_Rx" SG_ 631 RearPassWindowPos 1;
BA_ "U_P702_MY2021_Rx" SG_ 631 RearPassWindowPos 1;
BA_ "GenSigSendType" SG_ 631 RearPassWindowPos 3;
BA_ "WakeupSignal" SG_ 631 RearPassWindowPos 1;
BA_ "U_CD764_MY2022_Rx" SG_ 631 RearDriverWindowPos 1;
BA_ "U_U55X_MY2022_Rx" SG_ 631 RearDriverWindowPos 1;
BA_ "U_CD542_MY2021_Rx" SG_ 631 RearDriverWindowPos 1;
BA_ "U_T6_MCA_MY2020_Rx" SG_ 631 RearDriverWindowPos 1;
BA_ "U_P702_MY2021_Rx" SG_ 631 RearDriverWindowPos 1;
BA_ "GenSigSendType" SG_ 631 RearDriverWindowPos 3;
BA_ "WakeupSignal" SG_ 631 RearDriverWindowPos 1;
BA_ "U_CD542_MY2021_Rx" SG_ 631 PassWindowPosition 1;
BA_ "U_U55X_MY2022_Rx" SG_ 631 PassWindowPosition 1;
BA_ "U_T6_MCA_MY2020_Rx" SG_ 631 PassWindowPosition 1;
BA_ "GenSigSendType" SG_ 631 PassWindowPosition 3;
BA_ "WakeupSignal" SG_ 631 PassWindowPosition 1;
BA_ "U_CD764_MY2022_Rx" SG_ 631 RearPassWindowPos_UB 1;
BA_ "U_U55X_MY2022_Rx" SG_ 631 RearPassWindowPos_UB 1;
BA_ "U_CD542_MY2021_Rx" SG_ 631 RearPassWindowPos_UB 1;
BA_ "U_T6_MCA_MY2020_Rx" SG_ 631 RearPassWindowPos_UB 1;
BA_ "U_P702_MY2021_Rx" SG_ 631 RearPassWindowPos_UB 1;
BA_ "U_CD764_MY2022_Rx" SG_ 631 RearDriverWindowPos_UB 1;
BA_ "U_U55X_MY2022_Rx" SG_ 631 RearDriverWindowPos_UB 1;
BA_ "U_CD542_MY2021_Rx" SG_ 631 RearDriverWindowPos_UB 1;
BA_ "U_T6_MCA_MY2020_Rx" SG_ 631 RearDriverWindowPos_UB 1;
BA_ "U_P702_MY2021_Rx" SG_ 631 RearDriverWindowPos_UB 1;
BA_ "U_CD542_MY2021_Rx" SG_ 631 PassWindowPosition_UB 1;
BA_ "U_T6_MCA_MY2020_Rx" SG_ 631 PassWindowPosition_UB 1;
BA_ "U_U55X_MY2022_Rx" SG_ 631 PassWindowPosition_UB 1;
BA_ "U_CD764_MY2022_Rx" SG_ 631 DriverWindowPosition 1;
BA_ "U_U55X_MY2022_Rx" SG_ 631 DriverWindowPosition 1;
BA_ "U_CD542_MY2021_Rx" SG_ 631 DriverWindowPosition 1;
BA_ "U_T6_MCA_MY2020_Rx" SG_ 631 DriverWindowPosition 1;
BA_ "U_P702_MY2021_Rx" SG_ 631 DriverWindowPosition 1;
BA_ "GenSigSendType" SG_ 631 DriverWindowPosition 3;
BA_ "WakeupSignal" SG_ 631 DriverWindowPosition 1;
BA_ "U_CD764_MY2022_Rx" SG_ 631 DriverWindowPosition_UB 1;
BA_ "U_U55X_MY2022_Rx" SG_ 631 DriverWindowPosition_UB 1;
BA_ "U_CD542_MY2021_Rx" SG_ 631 DriverWindowPosition_UB 1;
BA_ "U_T6_MCA_MY2020_Rx" SG_ 631 DriverWindowPosition_UB 1;
BA_ "U_P702_MY2021_Rx" SG_ 631 DriverWindowPosition_UB 1;
BA_ "U_CD542_MY2021_Rx" SG_ 631 CnvtTopPos_Up_Stat 1;
BA_ "U_CD764_MY2022_Rx" SG_ 631 CnvtTopPos_Up_Stat 1;
BA_ "U_U55X_MY2022_Rx" SG_ 631 CnvtTopPos_Up_Stat 1;
BA_ "U_P702_MY2021_Rx" SG_ 631 CnvtTopPos_Up_Stat 1;
BA_ "GenSigSendType" SG_ 631 CnvtTopPos_Up_Stat 3;
BA_ "ContentDependant" SG_ 631 CnvtTopPos_Up_Stat 1;
BA_ "WakeupSignal" SG_ 631 CnvtTopPos_Up_Stat 1;
BA_ "U_CD764_MY2022_Rx" SG_ 631 Memory_Cmd 1;
BA_ "U_U55X_MY2022_Rx" SG_ 631 Memory_Cmd 1;
BA_ "U_CD542_MY2021_Rx" SG_ 631 Memory_Cmd 1;
BA_ "U_T6_MCA_MY2020_Rx" SG_ 631 Memory_Cmd 1;
BA_ "U_P702_MY2021_Rx" SG_ 631 Memory_Cmd 1;
BA_ "GenSigSendType" SG_ 631 Memory_Cmd 3;
BA_ "WakeupSignal" SG_ 631 Memory_Cmd 1;
BA_ "U_CD542_MY2021_Rx" SG_ 631 CnvtTopPos_Up_Stat_UB 1;
BA_ "U_CD764_MY2022_Rx" SG_ 631 CnvtTopPos_Up_Stat_UB 1;
BA_ "U_U55X_MY2022_Rx" SG_ 631 CnvtTopPos_Up_Stat_UB 1;
BA_ "U_P702_MY2021_Rx" SG_ 631 CnvtTopPos_Up_Stat_UB 1;
BA_ "U_CD764_MY2022_Rx" SG_ 631 Memory_Cmd_UB 1;
BA_ "U_U55X_MY2022_Rx" SG_ 631 Memory_Cmd_UB 1;
BA_ "U_CD542_MY2021_Rx" SG_ 631 Memory_Cmd_UB 1;
BA_ "U_T6_MCA_MY2020_Rx" SG_ 631 Memory_Cmd_UB 1;
BA_ "U_P702_MY2021_Rx" SG_ 631 Memory_Cmd_UB 1;
BA_ "U_U55X_MY2022_Rx" SG_ 631 EstmChrgTimeLP_St 1;
BA_ "U_CD542_MY2021_Rx" SG_ 631 EstmChrgTimeLP_St 1;
BA_ "U_T6_MCA_MY2020_Rx" SG_ 631 EstmChrgTimeLP_St 1;
BA_ "U_P702_MY2021_Rx" SG_ 631 EstmChrgTimeLP_St 1;
BA_ "GenSigSendType" SG_ 631 EstmChrgTimeLP_St 3;
BA_ "U_U55X_MY2022_Rx" SG_ 631 EstmChrgTimeHP_St 1;
BA_ "U_CD542_MY2021_Rx" SG_ 631 EstmChrgTimeHP_St 1;
BA_ "U_T6_MCA_MY2020_Rx" SG_ 631 EstmChrgTimeHP_St 1;
BA_ "U_P702_MY2021_Rx" SG_ 631 EstmChrgTimeHP_St 1;
BA_ "GenSigSendType" SG_ 631 EstmChrgTimeHP_St 3;
BA_ "U_T6_MCA_MY2020_Rx" SG_ 631 ChargeNowDuration_St 1;
BA_ "U_CD542_MY2021_Rx" SG_ 631 ChargeNowDuration_St 1;
BA_ "U_U55X_MY2022_Rx" SG_ 631 ChargeNowDuration_St 1;
BA_ "GenSigSendType" SG_ 631 ChargeNowDuration_St 3;
BA_ "U_CD542_MY2021_Rx" SG_ 631 CnvtTopMsgTxt_D_Rq_UB 1;
BA_ "U_T6_MCA_MY2020_Rx" SG_ 631 CnvtTopMsgTxt_D_Rq_UB 1;
BA_ "U_CD542_MY2021_Rx" SG_ 631 CnvtTopMsgTxt_D_Rq 1;
BA_ "U_T6_MCA_MY2020_Rx" SG_ 631 CnvtTopMsgTxt_D_Rq 1;
BA_ "GenSigSendType" SG_ 631 CnvtTopMsgTxt_D_Rq 3;
BA_ "WakeupSignal" SG_ 631 CnvtTopMsgTxt_D_Rq 1;
BA_ "U_CD542_MY2021_Rx" SG_ 631 CnvtTopPos_Dn_Stat_UB 1;
BA_ "U_U55X_MY2022_Rx" SG_ 631 CnvtTopPos_Dn_Stat_UB 1;
BA_ "U_P702_MY2021_Rx" SG_ 631 CnvtTopPos_Dn_Stat_UB 1;
BA_ "U_CD542_MY2021_Rx" SG_ 631 CnvtTopPos_Dn_Stat 1;
BA_ "U_U55X_MY2022_Rx" SG_ 631 CnvtTopPos_Dn_Stat 1;
BA_ "U_P702_MY2021_Rx" SG_ 631 CnvtTopPos_Dn_Stat 1;
BA_ "GenSigSendType" SG_ 631 CnvtTopPos_Dn_Stat 3;
BA_ "ContentDependant" SG_ 631 CnvtTopPos_Dn_Stat 1;
BA_ "WakeupSignal" SG_ 631 CnvtTopPos_Dn_Stat 1;
BA_ "U_U55X_MY2022_Rx" SG_ 631 EstmChrgTimeLP_St_UB 1;
BA_ "U_P702_MY2021_Rx" SG_ 631 EstmChrgTimeLP_St_UB 1;
BA_ "U_CD542_MY2021_Rx" SG_ 631 EstmChrgTimeLP_St_UB 1;
BA_ "U_T6_MCA_MY2020_Rx" SG_ 631 EstmChrgTimeLP_St_UB 1;
BA_ "U_U55X_MY2022_Rx" SG_ 631 EstmChrgTimeHP_St_UB 1;
BA_ "U_P702_MY2021_Rx" SG_ 631 EstmChrgTimeHP_St_UB 1;
BA_ "U_CD542_MY2021_Rx" SG_ 631 EstmChrgTimeHP_St_UB 1;
BA_ "U_T6_MCA_MY2020_Rx" SG_ 631 EstmChrgTimeHP_St_UB 1;
BA_ "U_CD542_MY2021_Rx" SG_ 631 ChargeNowDuration_St_UB 1;
BA_ "U_U55X_MY2022_Rx" SG_ 631 ChargeNowDuration_St_UB 1;
BA_ "U_T6_MCA_MY2020_Rx" SG_ 631 ChargeNowDuration_St_UB 1;
BA_ "U_P702_MY2021_Rx" SG_ 631 ChargeNowDuration_St_UB 1;
BA_ "U_CD542_MY2021_Rx" SG_ 1140 BattTracPw_Pc_Avail 1;
BA_ "U_CD542_MY2021_Rx" SG_ 1140 RgenLongTerm_L_Dsply 1;
BA_ "U_T6_MCA_MY2020_Rx" SG_ 1140 RgenLongTerm_L_Dsply 1;
BA_ "U_CD542_MY2021_Rx" SG_ 1140 PreCondStat_D_Dsply 1;
BA_ "U_T6_MCA_MY2020_Rx" SG_ 1140 PreCondStat_D_Dsply 1;
BA_ "U_CD542_MY2021_Rx" SG_ 1140 RgenLongTerm_Pc_Dsply 1;
BA_ "U_T6_MCA_MY2020_Rx" SG_ 1140 RgenLongTerm_Pc_Dsply 1;
BA_ "U_CD542_MY2021_Rx" SG_ 1140 RgenEvntLvl_Pc_Dsply 1;
BA_ "U_T6_MCA_MY2020_Rx" SG_ 1140 RgenEvntLvl_Pc_Dsply 1;
BA_ "GenSigStartValue" SG_ 1140 RgenEvntLvl_Pc_Dsply 1022;
BA_ "GenSigStartValueInteger" SG_ 1140 RgenEvntLvl_Pc_Dsply 1023;
BA_ "U_CD542_MY2021_Rx" SG_ 1140 BrkEvntComplt_B_Dsply 1;
BA_ "U_T6_MCA_MY2020_Rx" SG_ 1140 BrkEvntComplt_B_Dsply 1;
BA_ "U_CD542_MY2021_Rx" SG_ 1140 ExtChrgrFalt_B_Dsply 1;
BA_ "U_T6_MCA_MY2020_Rx" SG_ 1140 ExtChrgrFalt_B_Dsply 1;
BA_ "U_CD542_MY2021_Rx" SG_ 873 PwWhlLvl_Pc_Dsply 1;
BA_ "U_T6_MCA_MY2020_Rx" SG_ 873 PwWhlLvl_Pc_Dsply 1;
BA_ "GenSigStartValue" SG_ 873 PwWhlLvl_Pc_Dsply 511;
BA_ "U_CD542_MY2021_Rx" SG_ 873 VehVAnimation_Pc_Dsply 1;
BA_ "U_T6_MCA_MY2020_Rx" SG_ 873 VehVAnimation_Pc_Dsply 1;
BA_ "U_CD542_MY2021_Rx" SG_ 873 BattTracEMaint_B_Dsply 1;
BA_ "U_T6_MCA_MY2020_Rx" SG_ 873 BattTracEMaint_B_Dsply 1;
BA_ "U_CD764_MY2022_Rx" SG_ 873 BattPwLvl2_Pc_Dsply 1;
BA_ "U_U55X_MY2022_Rx" SG_ 873 BattPwLvl2_Pc_Dsply 1;
BA_ "U_P702_MY2021_Rx" SG_ 873 BattPwLvl2_Pc_Dsply 1;
BA_ "U_CD542_MY2021_Rx" SG_ 873 BattPwLvl2_Pc_Dsply 1;
BA_ "U_T6_MCA_MY2020_Rx" SG_ 873 BattPwLvl2_Pc_Dsply 1;
BA_ "GenSigStartValueInteger" SG_ 873 BattPwLvl2_Pc_Dsply 511;
BA_ "U_CD542_MY2021_Rx" SG_ 873 EffRelTrgtOn_B_Dsply 1;
BA_ "U_T6_MCA_MY2020_Rx" SG_ 873 EffRelTrgtOn_B_Dsply 1;
BA_ "U_CD542_MY2021_Rx" SG_ 873 EffInstThres_Pc_Dsply 1;
BA_ "U_T6_MCA_MY2020_Rx" SG_ 873 EffInstThres_Pc_Dsply 1;
BA_ "U_CD542_MY2021_Rx" SG_ 873 EffInstLvl_Pc_Dsply 1;
BA_ "U_T6_MCA_MY2020_Rx" SG_ 873 EffInstLvl_Pc_Dsply 1;
BA_ "U_U55X_MY2022_Rx" SG_ 873 GpsElMdeActv_B_Dsply 1;
BA_ "U_CD542_MY2021_Rx" SG_ 873 GpsElMdeActv_B_Dsply 1;
BA_ "U_T6_MCA_MY2020_Rx" SG_ 873 GpsElMdeActv_B_Dsply 1;
BA_ "U_P702_MY2021_Rx" SG_ 873 GpsElMdeActv_B_Dsply 1;
BA_ "U_CD542_MY2021_Rx" SG_ 873 LoAirAmbPlgIn_B_Dsply 1;
BA_ "U_T6_MCA_MY2020_Rx" SG_ 873 LoAirAmbPlgIn_B_Dsply 1;
VAL_ 611 AwdTerrMdeChng_D_Rdy 7 "Fault" 6 "Undefined_2" 5 "Undefined_1" 4 "ModeUnavailDrInputRqd" 3 "SpOpModes_NotSupported" 2 "ModeUnavailDynamicCond" 1 "Module_In_Initialization" 0 "Mode_Change_Available" ;
VAL_ 611 AwdTerrMde_D_Actl 7 "Fail_Safe_Default" 6 "Dynamic_Mode" 5 "Rock_Crawl_Mode" 4 "Mud_Ruts_Mode" 3 "Sand_Mode" 2 "Undefined" 1 "Low_Mu_Mode" 0 "Special_Operating_Mode_Off" ;
VAL_ 611 AwdSys_D_Stat 3 "Faulty" 2 "NotUsed" 1 "_4x4_L_H_Active" 0 "_4x4_L_H_Inactive" ;
VAL_ 611 AwdStat_D_RqDsply 31 "Rear_Diff_Lock_Not_Avail" 30 "_4wd_Lock_Required" 29 "Cfg_Perf_Redc_See_Manual" 28 "To_Engage_4x4_Release_Aped" 27 "To_Engage_4x4_Slow_To_3MPH" 26 "Shift_To_Neutral" 25 "Lkr_Mode_Unavail_TMS" 24 " _4x4_Mode_Unavail_TMS" 23 "Out_of_4Low_Crawl" 22 "AWD_PTU_Oil_Changed" 21 "Change_AWD_PTU_Oil" 20 "Neutral_Tow_Disabled" 19 "Neutral_Tow_Enabled" 18 "AWD_OFF" 17 "_4x4_Off_Road_Speed" 16 "_4x4_Extreme_Off_Road_Mode" 15 "_4x4_Exiting_Off_Road" 14 "_4x4_Off_Road_Mode" 10 "_4x4_Locked_Temporarily" 9 "Shift_In_Progress" 13 "Blocked_Shift_Assist" 12 "_4x4_Auto_Restored" 11 "_4x4_Disabled_Temporarily" 7 "Out_of_4Low__Neutral" 6 "Out_of_4Low__Brake" 5 "Out_of_4Low__Speed" 4 "Into_4Low__Clutch" 3 "Into_4Low__Neutral" 2 "Into_4Low__Brake" 1 "Into_4Low__Speed" 0 "Normal__No_Message" 8 "Out_of_4Low__Clutch" ;
VAL_ 611 AwdLck_D_Stat 9 "Undefined" 8 "Under_External_Torque_Ctrl" 7 "Torque_Limited_by_Cmd" 6 "Fully_Locked_by_Cmd" 5 "Disabled" 4 "Warning" 3 "Fault" 2 "Inactive" 1 "Completely_Opened_by_Cmd" 0 "OK" ;
VAL_ 611 AwdSrvcRqd_B_Rq 1 "On" 0 "Off" ;
VAL_ 611 AwdLck_Tq_Rq 4095 "Fault" 4094 "Unknown" ;
VAL_ 611 AwdOffRoadMode_D_Stats 3 "Invalid" 2 "Extreme_Off_Road" 1 "Off_Road" 0 "Normal_Mode" ;
VAL_ 611 AwdLoLamp_D_RqDsply 3 "Not_Used" 2 "Flash" 1 "On" 0 "Off" ;
VAL_ 611 AwdHiLamp_D_RqDsply 3 "Not_Used" 2 "Flash" 1 "On" 0 "Off" ;
VAL_ 611 AwdAutoLamp_D_RqDsply 3 "Not_Used" 2 "Flash" 1 "On" 0 "Off" ;
VAL_ 611 Awd2wdLamp_D_RqDsply 3 "Not_Used" 2 "Flash" 1 "On" 0 "Off" ;
VAL_ 611 AwdRnge_D_Actl 7 "Unknown" 6 "High_Range_2wd" 5 "High_Range_Auto" 4 "High_Range_Locked" 3 "Neutral" 2 "Low_Range_2wd" 1 "Low_Range_Auto" 0 "Low_Range_Locked" ;
VAL_ 611 NtrlTowAvail_B_Stat 1 "Available" 0 "NotAvailable" ;
VAL_ 611 AwdDrvMde_D_Stat 7 "Faulty" 6 "NotAvailable" 5 "RockCrawl" 4 "Baja" 3 "MudAndSand" 2 "Weather" 1 "Sport" 0 "Normal" ;
VAL_ 611 SelDrvMdeAwd_D_Stat 0 "NotAvailable" 1 "Available" 2 "TemporarilyNotAvailable" 3 "Faulty" ;
VAL_ 264 CabnAmb_Te_Actl_UB 1 "Fresh_data" 0 "Unchanged_data" ;
VAL_ 264 CabnAmb_Te_Actl 255 "Fault" ;
VAL_ 264 ChrgCordLck_D_Stat_UB 1 "Fresh_data" 0 "Unchanged_data" ;
VAL_ 264 ChrgCordLck_D_Stat 7 "Faulty" 6 "LockFail" 5 "UnlockFail" 4 "LockInProgress" 3 "UnlockInProgress" 2 "Lock" 1 "Unlock" 0 "Retain" ;
VAL_ 264 PwPckTqRdy_B_Dsply 1 "On" 0 "Off" ;
VAL_ 264 HtrnOvrTeLamp_B_Dsply_UB 1 "Fresh_data" 0 "Unchanged_data" ;
VAL_ 264 HtrnOvrTeLamp_B_Dsply 1 "On" 0 "Off" ;
VAL_ 264 PwPckTqRdy_B_Dsply_UB 1 "Fresh_data" 0 "Unchanged_data" ;
VAL_ 264 BpedDrvAppl_D_Actl 3 "_Not_Allowed" 2 "Driver_Braking" 1 "Driver_Not_Braking" 0 "Not_Allowed" ;
VAL_ 264 BpedDrvAppl_D_Actl_UB 1 "Fresh_data" 0 "Unchanged_data" ;
VAL_ 264 BattTracSoc_Pc_Dsply_UB 1 "Fresh_data" 0 "Unchanged_data" ;
VAL_ 264 BattTracSoc_Pc_Dsply 255 "Faulty" 254 "NoDataExists" ;
VAL_ 1114 TrailCtlSwtch_B_Stat2 1 "Pressed" 0 "Not_Pressed" ;
VAL_ 1114 TrlBrkInitOut_D_Rq 3 "Heavy" 2 "Medium" 1 "Light" 0 "Null" ;
VAL_ 968 RvltnMatchAllw_D_Rq 3 "RevolutionMatchDisabled" 2 "RevolutionMatchEnabled" 1 "ChangeWithDriveMode" 0 "NoSelection" ;
VAL_ 968 BrkDrvMde_D_Rq 7 "Faulty" 6 "RockCrawl" 5 "Baja" 4 "DragOrMudAndSand" 3 "Track" 2 "Snow_Wet" 1 "Sport" 0 "Normal" ;
VAL_ 968 LnchCtl_D_Rq 3 "NotUsed2" 2 "NotUsed1" 1 "LC_On" 0 "LC_Off" ;
VAL_ 968 CurrentColor_CmdGage 15 "NotUsed7" 14 "NotUsed6" 13 "NotUsed5" 12 "NotUsed4" 11 "NotUsed3" 10 "NotUsed2" 9 "NotUsed1" 8 "Null" 7 "Color7" 6 "Color6" 5 "Color5" 4 "Color4" 3 "Color3" 2 "Color2" 1 "Color1" 0 "Off" ;
VAL_ 968 BlendedColor_CmdGage 3 "NotUsed" 2 "Null" 1 "On" 0 "Off" ;
VAL_ 968 BlendColorRed_CmdGage 15 "NotUsed10" 14 "NotUsed9" 13 "NotUsed8" 12 "NotUsed7" 11 "NotUsed6" 10 "NotUsed5" 9 "NotUsed4" 8 "NotUsed3" 7 "NotUsed2" 6 "NotUsed1" 5 "_5" 4 "_4" 3 "_3" 2 "_2" 1 "_1" 0 "Null" ;
VAL_ 968 BlendColorGrn_CmdGage 15 "NotUsed10" 14 "NotUsed9" 13 "NotUsed8" 12 "NotUsed7" 11 "NotUsed6" 10 "NotUsed5" 9 "NotUsed4" 8 "NotUsed3" 7 "NotUsed2" 6 "NotUsed1" 5 "_5" 4 "_4" 3 "_3" 2 "_2" 1 "_1" 0 "Null" ;
VAL_ 968 BlendColorBlue_CmdGage 15 "NotUsed10" 14 "NotUsed9" 13 "NotUsed8" 12 "NotUsed7" 11 "NotUsed6" 10 "NotUsed5" 9 "NotUsed4" 8 "NotUsed3" 7 "NotUsed2" 6 "NotUsed1" 5 "_5" 4 "_4" 3 "_3" 2 "_2" 1 "_1" 0 "Null" ;
VAL_ 968 Dimming_Level_Cmd 3 "Low" 2 "Not_Used" 1 "High" 0 "Null" ;
VAL_ 968 Current_Color_Cmd 15 "NotUsed7" 14 "NotUsed6" 13 "NotUsed5" 12 "NotUsed4" 11 "NotUsed3" 10 "NotUsed2" 9 "NotUsed1" 8 "Null" 7 "Color7" 6 "Color6" 5 "Color5" 4 "Color4" 3 "Color3" 2 "Color2" 1 "Color1" 0 "Off" ;
VAL_ 968 BlendedColorRed_Cmd 15 "NotUsed10" 14 "NotUsed9" 13 "NotUsed8" 12 "NotUsed7" 11 "NotUsed6" 10 "NotUsed5" 9 "NotUsed4" 8 "NotUsed3" 7 "NotUsed2" 6 "NotUsed1" 5 "_5" 4 "_4" 3 "_3" 2 "_2" 1 "_1" 0 "Null" ;
VAL_ 968 BlendedColorGreen_Cmd 15 "NotUsed10" 14 "NotUsed9" 13 "NotUsed8" 12 "NotUsed7" 11 "NotUsed6" 10 "NotUsed5" 9 "NotUsed4" 8 "NotUsed3" 7 "NotUsed2" 6 "NotUsed1" 5 "_5" 4 "_4" 3 "_3" 2 "_2" 1 "_1" 0 "Null" ;
VAL_ 968 BlendedColorBlue_Cmd 15 "NotUsed10" 14 "NotUsed9" 13 "NotUsed8" 12 "NotUsed7" 11 "NotUsed6" 10 "NotUsed5" 9 "NotUsed4" 8 "NotUsed3" 7 "NotUsed2" 6 "NotUsed1" 5 "_5" 4 "_4" 3 "_3" 2 "_2" 1 "_1" 0 "Null" ;
VAL_ 968 BlendedColor_Cmd 3 "NotUsed" 2 "Null" 1 "On" 0 "Off" ;
VAL_ 968 SuspDrvMde_D_Rq 7 "Faulty" 6 "NotUsed2" 5 "NotUsed1" 4 "Drag" 3 "Track" 2 "Snow_Wet" 1 "Sport" 0 "Normal" ;
VAL_ 968 SlMde_D_Rq 3 "IsaNotConfigured" 2 "Manual_Mode" 1 "Auto_Mode" 0 "Null" ;
VAL_ 968 IsaOffst_D_Rq 15 "Faulty" 14 "Null" 13 "Thirteen" 12 "Twelve" 11 "Eleven" 10 "Ten" 9 "Nine" 8 "Eight" 7 "Seven" 6 "Six" 5 "Five" 4 "Four" 3 "Three" 2 "Two" 1 "One" 0 "Zero" ;
VAL_ 969 Dimming_Level_Stat 3 "Low" 2 "Not_Used" 1 "High" 0 "Null" ;
VAL_ 969 Current_Color_Stat 15 "NotUsed7" 14 "NotUsed6" 13 "NotUsed5" 12 "NotUsed4" 11 "NotUsed3" 10 "NotUsed2" 9 "NotUsed1" 8 "Null" 7 "Color7" 6 "Color6" 5 "Color5" 4 "Color4" 3 "Color3" 2 "Color2" 1 "Color1" 0 "Off" ;
VAL_ 969 BlendedColorRed_Stat 15 "NotUsed10" 14 "NotUsed9" 13 "NotUsed8" 12 "NotUsed7" 11 "NotUsed6" 10 "NotUsed5" 9 "NotUsed4" 8 "NotUsed3" 7 "NotUsed2" 6 "NotUsed1" 5 "_5" 4 "_4" 3 "_3" 2 "_2" 1 "_1" 0 "Null" ;
VAL_ 969 BlendedColorGreen_Stat 15 "NotUsed10" 14 "NotUsed9" 13 "NotUsed8" 12 "NotUsed7" 11 "NotUsed6" 10 "NotUsed5" 9 "NotUsed4" 8 "NotUsed3" 7 "NotUsed2" 6 "NotUsed1" 5 "_5" 4 "_4" 3 "_3" 2 "_2" 1 "_1" 0 "Null" ;
VAL_ 969 BlendedColorBlue_Stat 15 "NotUsed10" 14 "NotUsed9" 13 "NotUsed8" 12 "NotUsed7" 11 "NotUsed6" 10 "NotUsed5" 9 "NotUsed4" 8 "NotUsed3" 7 "NotUsed2" 6 "NotUsed1" 5 "_5" 4 "_4" 3 "_3" 2 "_2" 1 "_1" 0 "Null" ;
VAL_ 969 BlendedColor_Stat 3 "NotUsed" 2 "Null" 1 "On" 0 "Off" ;
VAL_ 969 TurnLampRrOut_B_Stat 1 "Out" 0 "Null" ;
VAL_ 969 TurnLampRlOut_B_Stat 1 "Out" 0 "Null" ;
VAL_ 1006 PersIndexIpmb_D_Actl 7 "Unused_3" 6 "Unused_2" 5 "Unused_1" 4 "Vehicle" 3 "PERS_4" 2 "PERS_3" 1 "PERS_2" 0 "PERS_1" ;
VAL_ 130 EngExhMdeQuiet_B_RqDrv2 1 "Pressed" 0 "Not_Pressed" ;
VAL_ 130 SteWhlSwtchHome_B_Stat 1 "Pressed" 0 "Not_Pressed" ;
VAL_ 130 SteWhlSwtchInfo_B_Stat 1 "Pressed" 0 "Not_Pressed" ;
VAL_ 130 SelDrvMdeSwtch_D_Stat4 3 "Faulty" 2 "SwitchState2" 1 "SwitchState1" 0 "NotPressed" ;
VAL_ 130 SelDrvMdeSwtch3_D_Stat4 3 "Faulty" 2 "Pressed" 1 "NotPressed" 0 "Null" ;
VAL_ 130 SelDrvMdeSwtch2_D_Stat4 3 "Faulty" 2 "Pressed" 1 "NotPressed" 0 "Null" ;
VAL_ 130 SelDrvMdeSwtch1_D_Stat4 3 "Faulty" 2 "Pressed" 1 "NotPressed" 0 "Null" ;
VAL_ 130 PoliceAux4Swtch_B_Stat 1 "Switch_Active" 0 "Switch_Not_Active" ;
VAL_ 130 PoliceAux3Swtch_B_Stat 1 "Switch_Active" 0 "Switch_Not_Active" ;
VAL_ 130 PoliceAux2Swtch_B_Stat 1 "Switch_Active" 0 "Switch_Not_Active" ;
VAL_ 130 PoliceAux1Swtch_B_Stat 1 "Switch_Active" 0 "Switch_Not_Active" ;
VAL_ 130 SteWhlSwtchView_B_Stat 1 "Pressed" 0 "Not_Pressed" ;
VAL_ 130 SteWhlSwtchSet_B_Stat 1 "Pressed" 0 "Not_Pressed" ;
VAL_ 130 SteWhlSwtchPhon_B_Stat 1 "Pressed" 0 "Not_Pressed" ;
VAL_ 130 SteWhlSwtchNav_B_Stat 1 "Pressed" 0 "Not_Pressed" ;
VAL_ 130 SteWhlSwtchMed_B_Stat 1 "Pressed" 0 "Not_Pressed" ;
VAL_ 130 SteWhlSwtchIod_B_Stat 1 "Pressed" 0 "Not_Pressed" ;
VAL_ 130 SteWhlSwtchHud_B_Stat 1 "Pressed" 0 "Not_Pressed" ;
VAL_ 130 SteWhlSwtchBack_B_Stat 1 "Pressed" 0 "Not_Pressed" ;
VAL_ 130 SteWhlSwtchMenu_B_Stat 1 "Pressed" 0 "Not_Pressed" ;
VAL_ 130 SteEffortInc_B_RqDrv 1 "Pressed" 0 "Not_Pressed" ;
VAL_ 130 SelDrvMdeInc_B_RqDrv 1 "Pressed" 0 "Not_Pressed" ;
VAL_ 130 SelDrvMdeDec_B_RqDrv 1 "Pressed" 0 "Not_Pressed" ;
VAL_ 130 SuspDampInc_B_RqDrv 1 "Pressed" 0 "Not_Pressed" ;
VAL_ 130 SteWhlSwtchUp_B_Stat 1 "Pressed" 0 "Not_Pressed" ;
VAL_ 130 SteWhlSwtchRght_B_Stat 1 "Pressed" 0 "Not_Pressed" ;
VAL_ 130 SteWhlSwtchOk_B_Stat 1 "Pressed" 0 "Not_Pressed" ;
VAL_ 130 SteWhlSwtchLeft_B_Stat 1 "Pressed" 0 "Not_Pressed" ;
VAL_ 130 SteWhlSwtchDown_B_Stat 1 "Pressed" 0 "Not_Pressed" ;
VAL_ 1244 Con_InfotainmentVer_St 1 "B299" 0 "invalid" ;
VAL_ 1243 Con_BTAud_InfotainmVer_St 1 "B299" 0 "invalid" ;
VAL_ 681 Con_DB1FilterConfig_St 31 "UnknownActive" 9 "Reserved" 8 "Podcast" 7 "Audiobook" 6 "Composer" 5 "Track" 4 "Genre" 3 "Album" 2 "Artist" 1 "Playlist" 0 "Root" ;
VAL_ 681 Con_DB1Filter3_St 1023 "All" 1022 "SIIndex_1022" 1 "SIIndex_1" 0 "NotEngaged" ;
VAL_ 681 Con_DB1Filter2_St 65535 "All" 65534 "SIIndex_65534" 1 "SIIndex_1" 0 "NotEngaged" ;
VAL_ 681 Con_DB1Filter1_St 65535 "All" 65534 "SIIndex_65534" 1 "SIIndex_1" 0 "NotEngaged" ;
VAL_ 741 Con_USB_Playtype_St 2 "Playlist" 1 "Folder" 0 "Invalid" ;
VAL_ 741 Con_ShowSWDLprogress_St 5 "ConSWUpdateSuccess" 4 "ConSWUpdateNotNecessary" 3 "ConSWUpdateFailed" 2 "ConSWUpdateInProgress" 1 "ConSWUpdateNotRunning" 0 "Invalid" ;
VAL_ 741 Con_iPod_IntroScan_St 3 "OnTheFolderSelGroup" 2 "OnTheDevice" 1 "Off" 0 "Invalid" ;
VAL_ 741 Con_iPod_Shuffle_St 3 "OnTheFolderSelGroup" 2 "OnTheDevice" 1 "Off" 0 "Invalid" ;
VAL_ 741 Con_iPod_Repeat_St 7 "Reserved2" 6 "Reserved1" 5 "Reserved" 4 "RepeatOnDevice" 3 "RepeatOnFolder" 2 "RepeatOnTrack" 1 "Off" 0 "Invalid" ;
VAL_ 741 Con_USB_Repeat_St 7 "Reserved2" 6 "Reserved1" 5 "Reserved" 4 "RepeatOnDevice" 3 "RepeatOnFolder" 2 "RepeatOnTrack" 1 "Off" 0 "Invalid" ;
VAL_ 741 Con_USB_IntroScan_St 3 "OnTheFolderSelGroup" 2 "OnTheDevice" 1 "Off" 0 "Invalid" ;
VAL_ 741 Con_USB_Shuffle_St 3 "OnTheFolderSelGroup" 2 "OnTheDevice" 1 "Off" 0 "Invalid" ;
VAL_ 741 Con_iPod_Error_St 8 "NoDataInFolder" 7 "NoRespFromDevice" 6 "UnableToRead" 5 "NoDataOnDevice" 4 "FileSysNotSupported" 3 "DeviceNotSupported" 2 "InvalidFile" 1 "NoError" 0 "Invalid" ;
VAL_ 741 Con_USB_Error_St 9 "USBHubNotSupported" 8 "NoDataInFolder" 7 "NoRespFromDevice" 6 "UnableToRead" 5 "NoDataOnDevice" 4 "FileSysNotSupported" 3 "DeviceNotSupported" 2 "InvalidFile" 1 "NoError" 0 "Invalid" ;
VAL_ 741 Con_iPod_FunctStatus_St 7 "Reserved2" 6 "Reserved1" 5 "Reserved" 4 "Reading" 3 "Ready" 2 "Initilization" 1 "Free" 0 "Invalid" ;
VAL_ 741 Con_USB_FunctStatus_St 7 "Reserved2" 6 "Reserved1" 5 "Reserved" 4 "Reading" 3 "Ready" 2 "Initilization" 1 "Free" 0 "Invalid" ;
VAL_ 741 Con_USB_OpMode_St 7 "FastRewind20" 6 "FastRewind10" 5 "FastForward20" 4 "FastForward10" 3 "Pause" 2 "Play" 1 "Stop" 0 "Invalid" ;
VAL_ 741 Con_iPod_OpMode_St 7 "FastRewind20" 6 "FastRewind10" 5 "FastForward20" 4 "FastForward10" 3 "Pause" 2 "Play" 1 "Stop" 0 "Invalid" ;
VAL_ 954 ExtLghtFront_D_RqBody 3 "NotUsed" 2 "On" 1 "Off" 0 "Null" ;
VAL_ 954 CrtsyLghtRear_D_Stat 3 "NotUsed" 2 "Automatic" 1 "Manual" 0 "Null" ;
VAL_ 954 PosLghtFl_D_Stat 3 "Faulty" 2 "Outage" 1 "On" 0 "Off" ;
VAL_ 954 PosLghtFr_D_Stat 3 "Faulty" 2 "Outage" 1 "On" 0 "Off" ;
VAL_ 954 CargoLght_D_Stat 3 "NotUsed" 2 "Automatic" 1 "Manual" 0 "Null" ;
VAL_ 954 TlghtTestLght_D_Stat 7 "Error" 6 "AllOff" 5 "TestingReverseLights" 4 "TestingBrakeLights" 3 "TestingLeftTurnSignal" 2 "TestingRightTurnSignal" 1 "ParkingLightsIlluminated" 0 "Null" ;
VAL_ 954 LghtAmbDrvMde_B_Stat 1 "Automatic" 0 "Manual" ;
VAL_ 954 KeylessIdl_B_Stat 1 "Pressed" 0 "Not_Pressed" ;
VAL_ 954 PwRnngBoardPoll_D_Stat 3 "NotUsed" 2 "PkPresent" 1 "PkNotPresent" 0 "NotPolling" ;
VAL_ 954 PoliceDmngLvl_D_Stat 7 "NotUsed" 6 "Off_Night" 5 "Off_Day" 4 "Low1Night" 3 "Low1Day" 2 "Inactive" 1 "Decommissioned" 0 "Null" ;
VAL_ 954 TrlrHitchLamp_D_Stat 1 "On" 0 "Off" ;
VAL_ 954 LicPlateLght_B_Stat 1 "On" 0 "Off" ;
VAL_ 954 TrukBedLght_B_Stat 1 "On" 0 "Off" ;
VAL_ 954 VehWlcmFrwlMde_D_Stat 7 "IlluminatedExit" 6 "CourtesyLightingDelayExt" 5 "CourtesyLightingExtended" 4 "CourtesyLightingDelayAll" 3 "CourtesyLightingAll" 2 "IlluminatedEntry" 1 "Approach" 0 "Null" ;
VAL_ 954 PudSptLghtRight_D_Rq 3 "NotUsed" 2 "On" 1 "Off" 0 "Null" ;
VAL_ 954 PudSptLghtLeft_D_Rq 3 "NotUsed" 2 "On" 1 "Off" 0 "Null" ;
VAL_ 954 ExtLghtRight_D_Stat 3 "NotUsed" 2 "On" 1 "Off" 0 "Null" ;
VAL_ 954 VehWlcmFrwl_D_Stat 3 "RunStart" 2 "Farewell" 1 "Welcome" 0 "Null" ;
VAL_ 954 ExtLghtRear_D_Stat 3 "NotUsed" 2 "On" 1 "Off" 0 "Null" ;
VAL_ 954 ExtLghtLeft_D_Stat 3 "NotUsed" 2 "On" 1 "Off" 0 "Null" ;
VAL_ 954 ExtLghtAlrt_B_Rq 1 "Yes" 0 "No" ;
VAL_ 954 ExtLght_D_Falt 3 "Error" 2 "NoStationary" 1 "StartEngine" 0 "Null" ;
VAL_ 954 ExtLghtFront_D_Stat 3 "NotUsed" 2 "On" 1 "Off" 0 "Null" ;
VAL_ 954 TlghtTestPrecnd_D_Stat 7 "Error" 6 "NotStationary" 5 "InteractionPresent" 4 "PreconditionsPassed" 3 "BattSocLessThan75Percent" 2 "TailLightsOn" 1 "IgnitionNotOn" 0 "Null" ;
VAL_ 954 TlghtTest_D_Stat 3 "InProgress" 2 "Ended" 1 "Completed" 0 "Null" ;
VAL_ 125 VehRolComp_W_Actl 4094 "NoDataExists" 4095 "Fault" ;
VAL_ 125 VehVertComp_A_Actl 1022 "NoDataExists" 1023 "Fault" ;
VAL_ 125 BrkTot_Tq_RqArb 8191 "Fault" 8190 "Unknown" ;
VAL_ 125 BrkTot_Tq_Actl 8191 "Fault" 8190 "Unknown" ;
VAL_ 125 HsaStat_D_Actl 7 "Faulty" 6 "FaultyWithDriverIndication" 5 "SlowRelease" 4 "FastRelease" 3 "ActiveBrakePedalReleased" 2 "ActiveBrakePedalPressed" 1 "FindingGradient" 0 "Inactive" ;
VAL_ 1082 PwTgateInhbtMsgTxt_B_Rq_UB 1 "Fresh_data" 0 "Unchanged_data" ;
VAL_ 1082 PwTgateInhbtMsgTxt_B_Rq 1 "DisplayMessage" 0 "NoMessage" ;
VAL_ 1082 SldrrStat_B_Actl_UB 1 "Fresh_data" 0 "Unchanged_data" ;
VAL_ 1082 SldrrStat_B_Actl 1 "Ajar" 0 "Closed" ;
VAL_ 1082 SldrlStat_B_Actl_UB 1 "Fresh_data" 0 "Unchanged_data" ;
VAL_ 1082 SldrlStat_B_Actl 1 "Ajar" 0 "Closed" ;
VAL_ 1082 StabBarFaltMsgTxt_D_Rq_UB 1 "Fresh_data" 0 "Unchanged_data" ;
VAL_ 1082 StabBarCnnctLamp_D_Rq_UB 1 "Fresh_data" 0 "Unchanged_data" ;
VAL_ 1082 StabBarCnncMsgTxt_D_Rq_UB 1 "Fresh_data" 0 "Unchanged_data" ;
VAL_ 1082 StabBarFaltMsgTxt_D_Rq 3 "Message3" 2 "Message2" 1 "Message1" 0 "NoMessage" ;
VAL_ 1082 StabBarCnnctLamp_D_Rq 3 "Fast_Flash" 2 "Slow_Flash" 1 "On" 0 "Off" ;
VAL_ 1082 StabBarCnncMsgTxt_D_Rq 15 "Message15" 14 "Message14" 13 "Message13" 12 "Message12" 11 "Message11" 10 "Message10" 9 "Message9" 8 "Message8" 7 "Message7" 6 "Message6" 5 "Message5" 4 "Message4" 3 "Message3" 2 "Message2" 1 "Message1" 0 "NoMessage" ;
VAL_ 1115 HUD_TextMessage_Rq 3 "Cancel" 2 "Ignore" 1 "Listen" 0 "Invalid" ;
VAL_ 1115 HUD_BTIncomingCall_Rq 2 "DeclineIncomingCall" 1 "AcceptIncomingCall" 0 "Inactive" ;
VAL_ 1115 HUD_BTInCallOptions_Rq 6 "EndHoldCall" 5 "HoldCall" 4 "GotoHandsfreeMode" 3 "GotoPrivacyMode" 2 "JoinCalls" 1 "SwitchCalls" 0 "Inactive" ;
VAL_ 1115 HUD_BTEndTelService_Rq 1 "EndOngoingTelephonyCall" 0 "Inactive" ;
VAL_ 811 ExtLghtDsply_D_Stat 7 "NotUsed" 6 "PressToOn3" 5 "PressToOff3" 4 "PressToOn2" 3 "PressToOff2" 2 "PressToOn1" 1 "PressToOff1" 0 "Reset" ;
VAL_ 811 SpeedoMajorUnit_D_Confg 3 "NotUsed" 2 "Kph" 1 "Mph" 0 "Null" ;
VAL_ 811 ScMnSoc_Pc_RqMnu 127 "Faulty" 126 "NoDataExists" ;
VAL_ 811 ScEnbl_D_RqMnu 3 "NotUsed" 2 "On" 1 "Off" 0 "Null" ;
VAL_ 811 OnePdlDrvButtn_B_Falt 1 "Faulted" 0 "NotFaulted" ;
VAL_ 811 OnePdlDrvButtn_B_Stat 1 "Pressed" 0 "Not_Pressed" ;
VAL_ 811 LongTermReset_B_RqMnu 1 "On" 0 "Off" ;
VAL_ 811 DistToStopover_L_Actl 65535 "Faulty" ;
VAL_ 811 StopoverType_D_Stat 7 "Faulty" 6 "NotUsed_1" 5 "Other" 4 "Work" 3 "Home" 2 "ChargeStation" 1 "FinalDestination" 0 "Null" ;
VAL_ 811 ExtLghtRight_D_RqMnu 7 "NotUsed" 6 "PressToOn3" 5 "PressToOff3" 4 "PressToOn2" 3 "PressToOff2" 2 "PressToOn1" 1 "PressToOff1" 0 "Reset" ;
VAL_ 811 AutoLghtOvrrd_B_RqDrv 1 "Allowed" 0 "NotAllowed" ;
VAL_ 811 ExtLghtRear_D_RqMnu 7 "NotUsed" 6 "PressToOn3" 5 "PressToOff3" 4 "PressToOn2" 3 "PressToOff2" 2 "PressToOn1" 1 "PressToOff1" 0 "Reset" ;
VAL_ 811 ExtLghtLeft_D_RqMnu 7 "NotUsed" 6 "PressToOn3" 5 "PressToOff3" 4 "PressToOn2" 3 "PressToOff2" 2 "PressToOn1" 1 "PressToOff1" 0 "Reset" ;
VAL_ 811 ExtLghtFront_D_RqMnu 7 "NotUsed" 6 "PressToOn3" 5 "PressToOff3" 4 "PressToOn2" 3 "PressToOff2" 2 "PressToOn1" 1 "PressToOff1" 0 "Reset" ;
VAL_ 811 GoTEditMnte_T_RqMnu 15 "Faulty" 14 "NoDataExists" 13 "NotUsed_2" 12 "NotUsed_1" 11 "Minute_55" 10 "Minute_50" 9 "Minute_45" 8 "Minute_40" 7 "Minute_35" 6 "Minute_30" 5 "Minute_25" 4 "Minute_20" 3 "Minute_15" 2 "Minute_10" 1 "Minute_5" 0 "Minute_0" ;
VAL_ 811 GoTEditHr_T_RqMnu 31 "Faulty" 30 "NoDataExists" ;
VAL_ 563 GridSrvc01_D_RqCld 3 "Faulty" 2 "No_Data_Exists" 1 "On" 0 "Off" ;
VAL_ 563 DrvBhavAudioAlrt_D_Rq 58 "NotUsed_51" 57 "NotUsed_50" 56 "NotUsed_49" 55 "NotUsed_48" 54 "NotUsed_47" 53 "NotUsed_46" 52 "NotUsed_45" 25 "NotUsed_18" 24 "NotUsed_17" 23 "NotUsed_16" 22 "NotUsed_15" 21 "NotUsed_14" 20 "NotUsed_13" 19 "NotUsed_12" 18 "NotUsed_11" 17 "NotUsed_10" 16 "NotUsed_9" 15 "NotUsed_8" 14 "NotUsed_7" 13 "NotUsed_6" 12 "NotUsed_5" 11 "NotUsed_4" 10 "NotUsed_3" 9 "NotUsed_2" 8 "NotUsed_1" 7 "ExcessiveIdleAndUnbuckled" 6 "ExcessiveSpeedAndUnbuckled" 5 "SeatbeltUnbuckled" 4 "HardBrakingBegin" 3 "HardAccelerationBegin" 2 "ExcessiveSpeedBegin" 1 "ExcessiveIdleBegin" 0 "NoMessage" 63 "NotUsed_56" 62 "NotUsed_55" 61 "NotUsed_54" 60 "NotUsed_53" 59 "NotUsed_52" ;
VAL_ 563 NtfyDrvTrgtDist_L2_Rq 8191 "Faulty" 8190 "NoDataExists" ;
VAL_ 563 BattChrgStrtStop_D_Rq 3 "ReturnToSettings" 2 "StopCharge" 1 "StartCharge" 0 "NoNewRequest" ;
VAL_ 563 DrvBhavWarn_B_Rq 1 "On" 0 "Off" ;
VAL_ 563 OfbChrgSetSync_D_Rq 3 "Fail" 2 "Success" 1 "InProgress" 0 "NoSyncInProgress" ;
VAL_ 563 KeyOffPwMde_D_Stat 7 "NotUsed_6" 6 "NotUsed_5" 5 "NotUsed_4" 4 "NotUsed_3" 0 "Inactive" 1 "On" 2 "NotUsed_1" 3 "NotUsed_2" ;
VAL_ 563 ModemReset_D_Stat 15 "NotUsed_10" 14 "NotUsed_9" 13 "NotUsed_8" 12 "NotUsed_7" 11 "NotUsed_6" 10 "NotUsed_5" 9 "NotUsed_4" 8 "NotUsed_3" 7 "NotUsed_2" 6 "NotUsed_1" 5 "WifiHotSpotResetComplete" 4 "CcsResetComplete" 3 "OnlineTrafficResetComplete" 2 "PaakResetComplete" 1 "ResetNotComplete" 0 "Null" ;
VAL_ 563 FactoryReset_St 3 "NotUsed_2" 2 "NotUsed_1" 1 "FactoryDefaultsRestored" 0 "Null" ;
VAL_ 794 DcacFaltMsgTxt_D2_Rq_UB 1 "Fresh_data" 0 "Unchanged_data" ;
VAL_ 794 DcacFaltMsgTxt_D2_Rq 63 "NotUsed_47" 17 "NotUsed_1" 16 "HevDerate" 15 "HvacOn" 14 "OvercurrentLP" 13 "EngineRun" 12 "Service" 11 "NotAvailable" 10 "PlugWarn" 9 "PlugWarnDrive" 8 "BreakerC" 7 "BreakerB" 6 "BreakerA" 5 "FuelLow" 4 "AcOnOutput" 3 "Temperature" 2 "Gfci" 1 "Overcurrent" 0 "Ok" ;
VAL_ 794 HvacBlwrRear_D_Stat_UB 1 "Fresh_data" 0 "Unchanged_data" ;
VAL_ 794 HvacBlwrFront_D_Stat_UB 1 "Fresh_data" 0 "Unchanged_data" ;
VAL_ 794 HvacBlwrRear_D_Stat 31 "Not_Used" 20 "Full_On" 19 "95_Percent" 18 "90_Percent" 17 "85_Percent" 16 "80_Percent" 15 "75_Percent" 14 "70_Percent" 13 "65_Percent" 12 "60_Percent" 11 "55_Percent" 10 "50_Percent" 9 "45_Percent" 8 "40_Percent" 7 "35_Percent" 6 "30_Percent" 5 "25_Percent" 4 "20_Percent" 3 "15_Percent" 2 "10_Percent" 1 "5_Percent" 0 "Off" ;
VAL_ 794 HvacBlwrFront_D_Stat 31 "Not_Used" 20 "Full_On" 19 "95_Percent" 18 "90_Percent" 17 "85_Percent" 16 "80_Percent" 15 "75_Percent" 14 "70_Percent" 13 "65_Percent" 12 "60_Percent" 11 "55_Percent" 10 "50_Percent" 9 "45_Percent" 8 "40_Percent" 7 "35_Percent" 6 "30_Percent" 5 "25_Percent" 4 "20_Percent" 3 "15_Percent" 2 "10_Percent" 1 "5_Percent" 0 "Off" ;
VAL_ 794 SpotLghtLeft_D_Stat_UB 1 "Fresh_data" 0 "Unchanged_data" ;
VAL_ 794 SpotLghtRight_D_Stat_UB 1 "Fresh_data" 0 "Unchanged_data" ;
VAL_ 794 SpotLghtRight_D_Stat 1 "On" 0 "Off" ;
VAL_ 794 SpotLghtLeft_D_Stat 1 "On" 0 "Off" ;
VAL_ 356 AltFuelOpMde_D_Stat 7 "NotUSed" 6 "AltFuelMde_To_GasMde" 5 "GasMde_To_AltFuelMde" 4 "ForcedAltFuelMde" 3 "AltFuelMde" 2 "ForcedGasMde_AltFuelSysErr" 1 "ForcedGasMde_AltFuelLow" 0 "GasMde" ;
VAL_ 356 AltFuelLvlWarn_D_Actl 7 "DteLevel5Lowest" 6 "DteLevel4" 5 "DteLevel3" 4 "DteLevel2NonMyKey" 3 "DteLevel1MyKey" 2 "VeryLow" 1 "Low" 0 "Ok" ;
VAL_ 356 AltFuelLvl_D_Stat 1 "Fault" 0 "No_Fault" ;
VAL_ 356 AltFuelMde_B_RqDrv 1 "On" 0 "Off" ;
VAL_ 356 AltFuelFalt_D_Stat 3 "NotUsed" 2 "Fault_MIL" 1 "Fault_NoMIL" 0 "Normal" ;
VAL_ 1146 TrlrAidSwtch_D_RqDrv 3 "Faulty" 2 "NotUsed" 1 "Pressed" 0 "Not_Pressed" ;
VAL_ 1146 TrlrAidCtl_U_RqDrv 4095 "Faulty" 4094 "NoDataExists" ;
VAL_ 1109 eCallConfirmation 7 "Unused_2" 6 "CallComplete_DTMF_Timeout" 5 "eCall_Configured_Off" 4 "Call_Unsuccessful" 3 "Call_Cancelled" 2 "Call_Completed" 1 "Call_In_Progress" 0 "Normal" ;
VAL_ 300 TrukBedLght_B_Stat2 1 "On" 0 "Off" ;
VAL_ 662 Running_Board_Cmd2 3 "Unused" 2 "Manually_Deployed" 1 "All_Enabled" 0 "All_Disabled" ;
VAL_ 662 Third_Rear_Set_Temp 31 "HI" 30 "29_5" 29 "29_0" 28 "28_5" 27 "28_0" 26 "27_5" 25 "27_0" 24 "26_5" 23 "26_0" 22 "25_5" 21 "25_0" 20 "24_5" 19 "24_0" 18 "23_5" 17 "23_0" 16 "22_5" 15 "22_0" 14 "21_5" 13 "21_0" 12 "20_5" 11 "20_0" 10 "19_5" 9 "19_0" 8 "18_5" 7 "18_0" 6 "17_5" 5 "17_0" 4 "16_5" 3 "16_0" 2 "15_5" 1 "LO" 0 "No_Request" ;
VAL_ 662 Third_Rear_Blower_Speed 15 "NotUsed_6" 14 "NotUsed_5" 13 "NotUsed_4" 12 "NotUsed_3" 11 "NotUsed_2" 10 "Zero_Blower" 9 "Max_Blower" 8 "Min_Blower" 7 "Blower_Speed_7" 6 "Blower_Speed_6" 5 "Blower_Speed_5" 4 "Blower_Speed_4" 3 "Blower_Speed_3" 2 "Blower_Speed_2" 1 "Blower_Speed_1" 0 "No_Request" ;
VAL_ 662 Rear_Temp 15 "NotUsed_6" 14 "NotUsed_5" 13 "NotUsed_4" 12 "NotUsed_3" 11 "NotUsed_2" 10 "NotUsed_1" 9 "Max_Heating" 8 "Level_3_Heating" 7 "Level_2_Heating" 6 "Level_1_Heating" 5 "No_Heating_Cooling" 4 "Level_1_Cooling" 3 "Level_2_Cooling" 2 "Level_3_Cooling" 1 "Max_Cooling" 0 "No_Request" ;
VAL_ 662 Rear_Set_Temp 31 "HI" 30 "29_5" 29 "29_0" 28 "28_5" 27 "28_0" 26 "27_5" 25 "27_0" 24 "26_5" 23 "26_0" 22 "25_5" 21 "25_0" 20 "24_5" 19 "24_0" 18 "23_5" 17 "23_0" 16 "22_5" 15 "22_0" 14 "21_5" 13 "21_0" 12 "20_5" 11 "20_0" 10 "19_5" 9 "19_0" 8 "18_5" 7 "18_0" 6 "17_5" 5 "17_0" 4 "16_5" 3 "16_0" 2 "15_5" 1 "LO" 0 "No_Request" ;
VAL_ 662 Rear_Blower_Speed 15 "NotUsed_6" 14 "NotUsed_5" 13 "NotUsed_4" 12 "NotUsed_3" 11 "NotUsed_2" 10 "Zero_Blower" 9 "Max_Blower" 8 "Min_Blower" 7 "Blower_Speed_7" 6 "Blower_Speed_6" 5 "Blower_Speed_5" 4 "Blower_Speed_4" 3 "Blower_Speed_3" 2 "Blower_Speed_2" 1 "Blower_Speed_1" 0 "No_Request" ;
VAL_ 837 VehCurb_M_Actl 1023 "Faulty" 1022 "NoDataExists" ;
VAL_ 837 VehGvwr_M_Actl 1023 "Faulty" 1022 "NoDataExists" ;
VAL_ 837 VdmSustnActv_B_Rq 1 "Active" 0 "Inactive" ;
VAL_ 837 Ccd_B_Falt 1 "Yes" 0 "No" ;
VAL_ 837 SuspVLim_B_Rq 1 "True" 0 "False" ;
VAL_ 837 SelDrvMdeSusp_D_Stat 3 "Faulty" 2 "TemporarilyNotAvailable" 1 "Available" 0 "NotAvailable" ;
VAL_ 837 AdptDrvMdePt_D_Rq 7 "Faulty" 6 "NotUsed3" 5 "NotUsed2" 4 "NotUsed1" 3 "Powertrain2Sport" 2 "Powertrain2Normal" 1 "Powertrain2Comfort" 0 "AdaptiveNotActive" ;
VAL_ 837 AdptDrvMdeChassis_D_Rq 7 "Faulty" 6 "NotUsed3" 5 "NotUsed2" 4 "NotUsed1" 3 "Chassis2Sport" 2 "Chassis2Normal" 1 "Chassis2Comfort" 0 "AdaptiveNotActive" ;
VAL_ 837 AirSprngRateRr_D_Rq 3 "NoRequest" 2 "Firm" 1 "Medium" 0 "Soft" ;
VAL_ 837 AirSprngRateRl_D_Rq 3 "NoRequest" 2 "Firm" 1 "Medium" 0 "Soft" ;
VAL_ 837 SuspType_B_Stat 1 "Magnetic" 0 "NonMagnetic" ;
VAL_ 837 AirSprngRateFr_D_Rq 3 "NoRequest" 2 "Firm" 1 "Medium" 0 "Soft" ;
VAL_ 837 AirSprngRateFl_D_Rq 3 "NoRequest" 2 "Firm" 1 "Medium" 0 "Soft" ;
VAL_ 837 AirSusp_D_Stat 3 "NotUsed" 2 "On" 1 "Off" 0 "Null" ;
VAL_ 837 AirSuspMsgTxt_D_Rq 3 "NotUsed" 2 "Faulty" 1 "Override" 0 "NoMessage" ;
VAL_ 837 SuspDrvMde_D_Stat 7 "Faulty" 6 "NotUsed2" 5 "NotUsed1" 4 "Drag" 3 "Track" 2 "Snow_Wet" 1 "Sport" 0 "Normal" ;
VAL_ 837 CcdMsgTxt_D_RqDsply 15 "Unused8" 14 "Unused7" 13 "Unused6" 12 "Unused5" 11 "Unused4" 10 "Unused3" 9 "Unused2" 8 "StationaryMode" 7 "Mode_Change_Unavailable" 6 "CCD_Temporarily_Off" 5 "CCD_Service_Required" 4 "Faulty" 3 "Sport" 2 "Normal" 1 "Comfort" 0 "No_Mode_Selected" ;
VAL_ 1121 OffRdSwtch_D_RqMnu 3 "Faulty" 2 "NoRequest" 1 "On" 0 "Off" ;
VAL_ 1121 SelDrvMdeSwtchOk_D_Stat 3 "Faulty" 2 "Pressed" 1 "NotPressed" 0 "Null" ;
VAL_ 1121 AutoHoldSwtch_D_Stat2 3 "Faulty" 2 "NotUsed" 1 "Pressed" 0 "Not_Pressed" ;
VAL_ 1121 PrkAidSwtch_D_RqDrv3 1 "Pressed" 0 "Not_Pressed" ;
VAL_ 1121 ApaSwtch_D_RqDrv3 3 "NotUsed2" 2 "NotUsed1" 1 "Pressed" 0 "Not_Pressed" ;
VAL_ 1121 StopStrtDrvMde_B_RqBtn2 1 "Pressed" 0 "Not_Pressed" ;
VAL_ 1121 SelDrvMdeSwtch_D_Stat 3 "Faulty" 2 "SwitchState2" 1 "SwitchState1" 0 "NotPressed" ;
VAL_ 1121 SelDrvMdeCnt_D_Stat 4 "FourCounts" 3 "ThreeCounts" 2 "TwoCounts" 1 "OneCount" 0 "ZeroCounts" 7 "SevenOrMoreCounts" 6 "SixCounts" 5 "FiveCounts" ;
VAL_ 670 DrHandleOuterRl_D_Stat 7 "NotUsed" 6 "Transition" 5 "FlushFault" 4 "DeployFault2" 3 "DeployFault1" 2 "Flush" 1 "Deploy" 0 "None" ;
VAL_ 670 DrHandleOuterFl_D_Stat 7 "NotUsed" 6 "Transition" 5 "FlushFault" 4 "DeployFault2" 3 "DeployFault1" 2 "Flush" 1 "Deploy" 0 "None" ;
VAL_ 669 DrHandleOuterRr_D_Stat 7 "NotUsed" 6 "Transition" 5 "FlushFault" 4 "DeployFault2" 3 "DeployFault1" 2 "Flush" 1 "Deploy" 0 "None" ;
VAL_ 669 DrHandleOuterFr_D_Stat 7 "NotUsed" 6 "Transition" 5 "FlushFault" 4 "DeployFault2" 3 "DeployFault1" 2 "Flush" 1 "Deploy" 0 "None" ;
VAL_ 140 CcAslButtnIndxIncPress2 1 "Button_Pressed" 0 "Button_Not_Pressed" ;
VAL_ 140 SteWhlSwtchMde_D_Stat 3 "NotUsed_2" 2 "NotUsed_1" 1 "Dialog" 0 "Domain" ;
VAL_ 140 CcAslButtnOffCnclPress2 1 "Button_Pressed" 0 "Button_Not_Pressed" ;
VAL_ 140 CcAslButtnIndxDecPress2 1 "Button_Pressed" 0 "Button_Not_Pressed" ;
VAL_ 140 CcAslButtnCnclResPress2 1 "Button_Pressed" 0 "Button_Not_Pressed" ;
VAL_ 140 CcAslButtnResIncPress3 1 "Pressed" 0 "Not pressed" ;
VAL_ 140 CcButtnOnPress3 1 "Pressed" 0 "Not pressed" ;
VAL_ 140 CcButtnOnOffPress3 1 "Pressed" 0 "Not pressed" ;
VAL_ 140 CcButtnOnOffCnclPress3 1 "Pressed" 0 "Not pressed" ;
VAL_ 140 CcButtnOffPress3 1 "Pressed" 0 "Not pressed" ;
VAL_ 140 CcAsllButtnResPress3 1 "Pressed" 0 "Not pressed" ;
VAL_ 140 CcAslButtnSetPress3 1 "Pressed" 0 "Not pressed" ;
VAL_ 140 CcAslButtnSetIncPress3 1 "Pressed" 0 "Not pressed" ;
VAL_ 140 CcAslButtnSetDecPress3 1 "Pressed" 0 "Not pressed" ;
VAL_ 140 CcAslButtnResDecPress3 1 "Pressed" 0 "Not pressed" ;
VAL_ 140 CcAslButtnOnPress3 1 "Pressed" 0 "Not pressed" ;
VAL_ 140 CcAslButtnOnOffCncl3 1 "Pressed" 0 "Not pressed" ;
VAL_ 140 CcAslButtnDeny_B_Actl3 1 "Pressed" 0 "Not pressed" ;
VAL_ 140 CcAslButtnCnclPress3 1 "Pressed" 0 "Not pressed" ;
VAL_ 140 AslButtnOnOffPress3 1 "Pressed" 0 "Not pressed" ;
VAL_ 140 AslButtnOnOffCnclPress2 1 "Pressed" 0 "Not pressed" ;
VAL_ 546 PrplSnd_D_Rq 3 "NotUsed" 2 "Enabled" 1 "Disabled" 0 "Null" ;
VAL_ 546 SYNC_New_Attn_Event 1 "Active" 0 "Inactive" ;
VAL_ 546 SYNC_Attn_Info_Audio 7 "Unknown" 6 "Attenuation_6" 5 "Attenuation_5" 4 "Attenuation_4" 3 "Attenuation_3" 2 "Attenuation_2" 1 "Attenuation_1" 0 "Inactive" ;
VAL_ 546 Prompt_Directionality 3 "RearSpeakers" 2 "FrontSpeakers" 1 "ALL" 0 "Inactive" ;
VAL_ 546 Audible_Beep 1 "Active" 0 "Inactive" ;
VAL_ 546 Alert_Chan 2 "Initialize_for_Prompts" 1 "Mute" 0 "Inactive" ;
VAL_ 1186 AwdDrvMde_D2_Stat 15 "Faulty" 14 "NotUsed_7" 13 "NotUsed_6" 12 "NotUsed_5" 11 "NotUsed_4" 10 "NotUsed_3" 9 "NotUsed_2" 8 "NotUsed_1" 7 "NotAvailable" 6 "TowHaul" 5 "RockCrawl" 4 "Baja" 3 "MudAndSand" 2 "Weather" 1 "Sport" 0 "Normal" ;
VAL_ 1186 FrontDiffLckLamp_D_Rq 3 "Triggered" 2 "Flash" 1 "On" 0 "Off" ;
VAL_ 1186 FrontDiffLckMsg_D_Rq 7 "LockerDisabled" 6 "LockerEnabled" 5 "LockerAccelPedal" 4 "Speed4" 3 "Speed3" 2 "Speed2" 1 "Speed1" 0 "NormalNoMessage" ;
VAL_ 1186 AwdStat2_D_RqDsply 31 "NotUsed_29" 30 "NotUsed_28" 29 "NotUsed_27" 28 "NotUsed_26" 27 "NotUsed_25" 26 "NotUsed_24" 25 "NotUsed_23" 24 "NotUsed_22" 23 "NotUsed_21" 22 "NotUsed_20" 21 "NotUsed_19" 20 "NotUsed_18" 19 "NotUsed_17" 18 "NotUsed_16" 17 "NotUsed_15" 16 "NotUsed_14" 15 "NotUsed_13" 14 "NotUsed_12" 13 "NotUsed_11" 12 "NotUsed_10" 11 "NotUsed_9" 10 "NotUsed_8" 9 "NotUsed_7" 8 "NotUsed_6" 7 "NotUsed_5" 6 "NotUsed_4" 5 "Unavailable4x4Mode" 4 "UnavailableDriveMode" 3 "HillHoldFail" 2 "TCaseOilChanged" 1 "ChangeTCaseOil" 0 "Normal" ;
VAL_ 1186 RearDiffLckLamp_D_Rq 3 "Not_Used" 2 "Flash" 1 "On" 0 "Off" ;
VAL_ 1186 RearDiffFalt_D_Stat 3 "Diff_Failed_Closed" 2 "Diff_Failed_Open" 1 "Fault_Non_Specific" 0 "No_Fault" ;
VAL_ 1186 RearDiffLck_Tq_Actl 4095 "Fault" 4094 "Unknown" ;
VAL_ 1186 FrontDiffFalt_D_Stat 3 "Diff_Failed_Closed" 2 "Diff_Failed_Open" 1 "Fault_Non_Specific" 0 "No_Fault" ;
VAL_ 1186 FrontDiffLck_Tq_Actl 16383 "Faulty" 16382 "NoDataExists" ;
VAL_ 1186 SelDrvMdeAwd2_D_Stat 31 "Faulty" 30 "NotUsed_17" 29 "NotUsed_16" 28 "NotUsed_15" 27 "NotUsed_14" 26 "NotUsed_13" 25 "NotUsed_12" 24 "NotUsed_11" 23 "NotUsed_10" 22 "NotUsed_9" 21 "NotUsed_8" 20 "CustomMode" 19 "OnePedalDrive" 18 "DragMode" 17 "EvLaterChargeMode" 16 "EvNowMode" 15 "TrackMode" 14 "RoughRoadMode" 13 "NotAvailable" 12 "HighSpeedDesertMode_Baja" 11 "SportAdaptiveMode" 10 "RockCrawlMode" 9 "MudRutsMode" 8 "SandMode" 7 "EconomyMode" 6 "GrassGravelSnow" 5 "TowHaulMode" 4 "SportMode" 3 "Normal_4L" 2 "Normal_4A" 1 "Normal_2H" 0 "NormalMode" ;
VAL_ 1186 RearDiffLckMsg_D_Rq 7 "Locker_Disabled" 6 "Locker_Enabled" 5 "Locker_Accel_Pedal" 4 "Speed4" 3 "Speed3" 2 "Spee2" 1 "Speed1" 0 "Normal__No_Message " ;
VAL_ 1186 LsdSrvcRqd_B_Rq 1 "On" 0 "Off" ;
VAL_ 1130 DrvSlipCtlOffLamp_D_Rq_UB 1 "Fresh_data" 0 "Unchanged_data" ;
VAL_ 1130 DrvSlipCtlMdeMsg_D_Rq_UB 1 "Fresh_data" 0 "Unchanged_data" ;
VAL_ 1130 DrvSlipCtlOffLamp_D_Rq 3 "Fast_Flash" 2 "Slow_Flash" 1 "On" 0 "Off" ;
VAL_ 1130 DrvSlipCtlMdeMsg_D_Rq 31 "Message31" 30 "Message30" 29 "Message29" 28 "Message28" 27 "Message27" 26 "Message26" 25 "Message25" 24 "Message24" 23 "Message23" 22 "Message22" 21 "Message21" 20 "Message20" 19 "Message19" 18 "Message18" 17 "Message17" 16 "Message16" 15 "Message15" 14 "Message14" 13 "Message13" 12 "Message12" 11 "Message11" 10 "Message10" 9 "Message9" 8 "Message8" 7 "Message7" 6 "Message6" 5 "Message5" 4 "Message4" 3 "Message3" 2 "Message2" 1 "Message1" 0 "NoMessage" ;
VAL_ 1130 HtrnWarnLamp_B_Dsply_UB 1 "Fresh_data" 0 "Unchanged_data" ;
VAL_ 1130 HtrnWarnLamp_B_Dsply 1 "On" 0 "Off" ;
VAL_ 1130 HtrnSrvcRqd_B_Dsply_UB 1 "Fresh_data" 0 "Unchanged_data" ;
VAL_ 1130 HtrnSrvcRqd_B_Dsply 1 "On" 0 "Off" ;
VAL_ 1130 ChrgrSrvcRqd_B_Rq_UB 1 "Fresh_data" 0 "Unchanged_data" ;
VAL_ 1130 ChrgrSrvcRqd_B_Rq 1 "On" 0 "Off" ;
VAL_ 1130 BattTracSrvcRqd_B_Rq_UB 1 "Fresh_data" 0 "Unchanged_data" ;
VAL_ 1130 BattTracSrvcRqd_B_Rq 1 "On" 0 "Off" ;
VAL_ 1130 BrkPadMsgTxt_D_Rq_UB 1 "Fresh_data" 0 "Unchanged_data" ;
VAL_ 1130 BrkPadMsgTxt_D_Rq 3 "Faulty" 2 "PadsOk" 1 "ReplacePads" 0 "Null" ;
VAL_ 1130 SuspDrvMde_D_Stat 7 "Faulty" 6 "NotUsed2" 5 "NotUsed1" 4 "Drag" 3 "Track" 2 "Snow_Wet" 1 "Sport" 0 "Normal" ;
VAL_ 1130 SuspDrvMde_D_Stat_UB 1 "Fresh_data" 0 "Unchanged_data" ;
VAL_ 1042 TrlrAnCalib_Pc_Actl 15 "Faulty" ;
VAL_ 1042 VehRol_An_Dsply_UB 1 "Fresh_data" 0 "Unchanged_data" ;
VAL_ 1042 VehPtch_An_Dsply_UB 1 "Fresh_data" 0 "Unchanged_data" ;
VAL_ 1042 VehRol_An_Dsply 127 "Faulty" 126 "NoDataExists" ;
VAL_ 1042 VehPtch_An_Dsply 127 "Faulty" 126 "NoDataExists" ;
VAL_ 1042 TrlrBrk_Pc_Rq_UB 1 "Fresh_data" 0 "Unchanged_data" ;
VAL_ 1042 VehYaw_W_Actl_UB 1 "Fresh_data" 0 "Unchanged_data" ;
VAL_ 1042 VehYaw_W_Actl 65535 "Faulty" 65534 "NoDataExists" ;
VAL_ 1093 TrlBrkInitOut_D_Stat 3 "Heavy" 2 "Medium" 1 "Light" 0 "Null" ;
VAL_ 1093 TrlrBrkMde_D_Actl 1 "Electric_Over_Hydraulic" 0 "Electric" ;
VAL_ 1093 TrlrBrkDsply_B_Rq 1 "Yes" 0 "No" ;
VAL_ 1093 TrlrBrkDcnnt_B_Actl 1 "Yes" 0 "No" ;
VAL_ 1093 TrlrBrkActCnnct_B_Actl 1 "Yes" 0 "No" ;
VAL_ 1093 StopLamp_B_RqTrlrBrk 1 "Yes" 0 "No" ;
VAL_ 1093 TrlrBrkCtl_B_Falt 1 "Yes" 0 "No" ;
VAL_ 1093 TrlrBrkActCirct_B_Falt 1 "Yes" 0 "No" ;
VAL_ 1138 BattChrgTrgtLMin_T_Est 2047 "Faulty" 2046 "NoDataExists" ;
VAL_ 1138 ActChrgEndYr_No_Actl 31 "Invalid" ;
VAL_ 1138 ActChrgEndMnth_No_Actl 15 "Invalid" ;
VAL_ 1138 ActChrgEndMin_No_Actl 63 "Invalid" 62 "Unknown" ;
VAL_ 1138 ActChrgEndHr_No_Actl 31 "Invalid" 30 "Unknown" ;
VAL_ 1138 ActChrgEndDay_No_Actl 31 "Invalid" ;
VAL_ 1139 BattChrgTrgtLMax_T_Est 2047 "Faulty" 2046 "NoDataExists" ;
VAL_ 1139 ActChrgStrtYr_No_Actl 31 "Invalid" ;
VAL_ 1139 ActChrgStrtMin_No_Actl 63 "Invalid" 62 "Unknown" ;
VAL_ 1139 ActChrgStrtHr_No_Actl 31 "Invalid" 30 "Unknown" ;
VAL_ 1139 ActChrgStrtDay_No_Actl 31 "Invalid" ;
VAL_ 1139 ActChrgStrMnth_No_Actl 15 "Invalid" ;
VAL_ 1145 EstmChrgTimeLP_St 255 "Invalid" ;
VAL_ 1145 EstmChrgTimeHP_St 255 "Invalid" ;
VAL_ 1145 ChargeNowDuration_St 255 "Invalid" ;
VAL_ 1145 VehElRngeNut_L2_Dsply 8191 "Faulty" 8190 "NoDataExists" ;
VAL_ 1145 VehElRngeNut_L_Dsply 4095 "Faulty" 4094 "NoDataExists" ;
VAL_ 1145 NxtUsgSocEst_Pc_Dsply 255 "Faulty" 254 "NoDataExists" ;
VAL_ 1232 AHU_EnsembleName_St 1 "Supported" 0 "Not_Supported" ;
VAL_ 1232 AHU_AutoConfigOcc_Shakr 1 "Supported" 0 "Not_Supported" ;
VAL_ 1232 AHU_AutoConfigOcc_Rear 1 "Supported" 0 "Not_Supported" ;
VAL_ 1232 AHU_AutoConfigOcc_Front 1 "Supported" 0 "Not_Supported" ;
VAL_ 1232 AHU_AutoConfigOcc_Drvr 1 "Supported" 0 "Not_Supported" ;
VAL_ 1232 AHU_AutoConfigOcc_Cnvrt 1 "Supported" 0 "Not_Supported" ;
VAL_ 1232 AHU_AutoConfigOcc_Allst 1 "Supported" 0 "Not_Supported" ;
VAL_ 1232 ACU_DigitalRadio_St 5 "DAB_RadioSystemWithPTY_JAP" 4 "DAB_RadioSystemWithPTY_GCC" 3 "DAB_RadioSystemWithPTY_NA" 2 "DAB_RadioSystemWithPTY_EU_AndROW" 1 "WithoutDigitalRadioSystem" 0 "Invalid" ;
VAL_ 1232 ACU_Configuration 6 "HIN_HSRNS" 0 "Invalid" 1 "LowLevelAudio" 2 "HighLevelAudio" 3 "LowLevelNavigation" 4 "HighLevelNavigation" 5 "HIN_LSRNS" ;
VAL_ 1232 ACU_MediaPlayer_St 0 "Invalid" 1 "MusicCassettePlayer" 2 "CdSinglePlayer" 3 "CdChanger" ;
VAL_ 1141 AirAmbTePlgIn_D_Dsply 3 "NotUsed" 2 "Hot_Outside_Plg_In_Msg" 1 "Cold_Outside_Plg_In_Msg" 0 "No_Plg_In_Msg" ;
VAL_ 1141 PtRmtRprt_D_Rq 15 "NotUsed_4" 14 "NotUsed_3" 13 "NotUsed_2" 12 "PlugInToMaintain12vBattery" 11 "SettingUpdated" 10 "FastChargeComplete" 9 "ChargeNotOccurring" 8 "OneTimeSocReached" 7 "BatteryTemperatureReminder" 6 "ReducedPerformance" 5 "LimitedPerformance" 4 "ChargeFault" 3 "ChargeComplete" 2 "VehiclePreconditioned" 1 "TripDistanceAchieved" 0 "NoReportRequest" ;
VAL_ 1141 NxtUsg_D_Rq 0 "Invalid" 1 "Not_Requested" 2 "Requested" 3 "NotUsed" ;
VAL_ 1141 NtfctnConflict1_D_Rq 7 "NotUsed_4" 6 "NotUsed_3" 5 "NotUsed_2" 4 "NotUsed_1" 3 "ChargeWindow" 2 "DepartureTime" 1 "NoConflictExists" 0 "Null" ;
VAL_ 1141 ChrgLocGPS_D_Rq 0 "Inactive" 1 "Not_Requested" 2 "Requested" 3 "NotUsed" ;
VAL_ 1141 OfbChrgSetSync_D_Stat 3 "Fail" 2 "Success" 1 "InProgress" 0 "NoSyncInProgress" ;
VAL_ 631 RearPassWindowPos 7 "Unused2" 6 "Unused1" 5 "Fully_Open" 4 "Bet60Percent_FullyOpen" 3 "Bet10Percent_60Percent" 2 "BetFully_10PercentOpen" 1 "Fully_Closed" 0 "Undefined" ;
VAL_ 631 RearDriverWindowPos 7 "Unused2" 6 "Unused1" 5 "Fully_Open" 4 "Bet60Percent_FullyOpen" 3 "Bet10Percent_60Percent" 2 "BetFully_10PercentOpen" 1 "Fully_Closed" 0 "Undefined" ;
VAL_ 631 PassWindowPosition 7 "Unused2" 6 "Unused1" 5 "Fully_Open" 4 "Bet60Percent_FullyOpen" 3 "Bet10Percent_60Percent" 2 "BetFully_10PercentOpen" 1 "Fully_Closed" 0 "Undefined" ;
VAL_ 631 RearPassWindowPos_UB 1 "Fresh_data" 0 "Unchanged_data" ;
VAL_ 631 RearDriverWindowPos_UB 1 "Fresh_data" 0 "Unchanged_data" ;
VAL_ 631 PassWindowPosition_UB 1 "Fresh_data" 0 "Unchanged_data" ;
VAL_ 631 DriverWindowPosition 7 "Unused2" 6 "Unused1" 5 "Fully_Open" 4 "Bet60Percent_FullyOpen" 3 "Bet10Percent_60Percent" 2 "BetFully_10PercentOpen" 1 "Fully_Closed" 0 "Undefined" ;
VAL_ 631 DriverWindowPosition_UB 1 "Fresh_data" 0 "Unchanged_data" ;
VAL_ 631 CnvtTopPos_Up_Stat 1 "Up" 0 "Not_Up" ;
VAL_ 631 Memory_Cmd 7 "Recall_3" 4 "Store_4" 3 "Store_3" 6 "Recall_2" 5 "Recall_1" 2 "Store_2" 1 "Store_1" 0 "Null" 8 "Recall_4" ;
VAL_ 631 CnvtTopPos_Up_Stat_UB 1 "Fresh_data" 0 "Unchanged_data" ;
VAL_ 631 Memory_Cmd_UB 1 "Fresh_data" 0 "Unchanged_data" ;
VAL_ 631 EstmChrgTimeLP_St 255 "Invalid" ;
VAL_ 631 EstmChrgTimeHP_St 255 "Invalid" ;
VAL_ 631 ChargeNowDuration_St 255 "Invalid" ;
VAL_ 631 CnvtTopMsgTxt_D_Rq_UB 1 "Fresh_data" 0 "Unchanged_data" ;
VAL_ 631 CnvtTopMsgTxt_D_Rq 3 "NotSecure" 2 "NotAvailable" 1 "RemoveCaps" 0 "NoWarning" ;
VAL_ 631 CnvtTopPos_Dn_Stat_UB 1 "Fresh_data" 0 "Unchanged_data" ;
VAL_ 631 CnvtTopPos_Dn_Stat 1 "Down" 0 "Not_Down" ;
VAL_ 631 EstmChrgTimeLP_St_UB 1 "Fresh_data" 0 "Unchanged_data" ;
VAL_ 631 EstmChrgTimeHP_St_UB 1 "Fresh_data" 0 "Unchanged_data" ;
VAL_ 631 ChargeNowDuration_St_UB 1 "Fresh_data" 0 "Unchanged_data" ;
VAL_ 1140 BattTracPw_Pc_Avail 255 "Faulty" 254 "NoDataExists" ;
VAL_ 1140 RgenLongTerm_L_Dsply 16777215 "Faulty" 16777214 "NoDataExists" ;
VAL_ 1140 PreCondStat_D_Dsply 7 "Reserved3" 6 "Reserved2" 5 "Reserved1" 4 "Faulted" 3 "Complete" 2 "In_Progress" 1 "Scheduled" 0 "Not_Scheduled" ;
VAL_ 1140 RgenEvntLvl_Pc_Dsply 1023 "Fault" 1022 "NoDataExists" ;
VAL_ 1140 BrkEvntComplt_B_Dsply 1 "On" 0 "Off" ;
VAL_ 1140 ExtChrgrFalt_B_Dsply 1 "Yes" 0 "No" ;
VAL_ 873 BattTracEMaint_B_Dsply 1 "On" 0 "Off" ;
VAL_ 873 EffRelTrgtOn_B_Dsply 1 "On" 0 "Off" ;
VAL_ 873 GpsElMdeActv_B_Dsply 1 "On" 0 "Off" ;
VAL_ 873 LoAirAmbPlgIn_B_Dsply 1 "On" 0 "Off" ;
